// *************************************************************************** *
// *                                                                           *
// *                      Mentor Graphics Corporation                          *
// *                          All rights reserved                              *
// *                                                                           *
// *************************************************************************** *
// *                                                                           *
// * Description:         CANDB File                                           *
// * Generated at:        2020-04-14 13:10:10                                  *
// * System:              SDB20010                                             *
// * Variant:             HX11                                                 *
// * Network:             BodyExposedCAN                                       *
// *                                                                           *
// *************************************************************************** *
// *                                                                           *
// *             THIS CONFIGURATION MIGHT CONTAIN SOME ERRORS                  *
// *              IF THE INPUT MODEL WAS NOT PROPERLY FORMED!                  *
// *                    Do Not Use this File directly!                         *
// *                                                                           *
// *************************************************************************** *
VERSION "BodyExposedCAN"

NS_ :

BS_:

BU_:  CEM ETC HCML HCMR

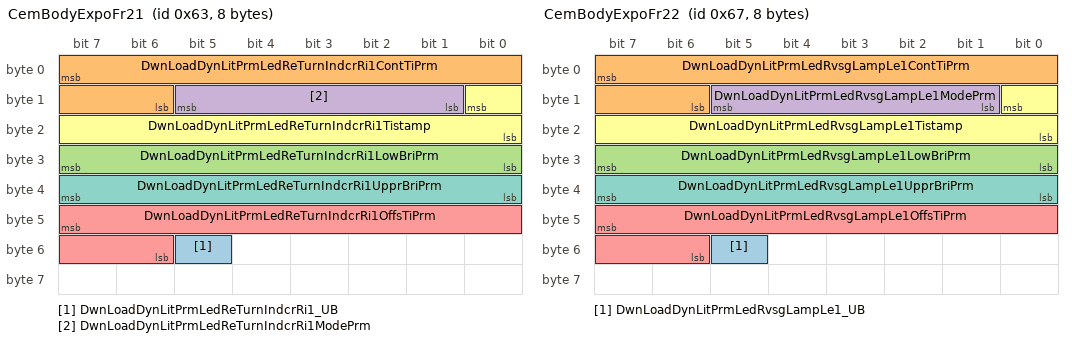
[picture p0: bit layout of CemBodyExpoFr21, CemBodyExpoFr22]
BO_ 99 CemBodyExpoFr21: 8 CEM
 SG_ DwnLoadDynLitPrmLedReTurnIndcrRi1_UB : 53|1@0+ (1,0) [0|1] "" Vector_XXX
 SG_ DwnLoadDynLitPrmLedReTurnIndcrRi1ContTiPrm : 7|10@0+ (1.0,0.0) [0.0|1000.0] "Milliseconds" Vector_XXX
 SG_ DwnLoadDynLitPrmLedReTurnIndcrRi1LowBriPrm : 31|8@0+ (1.0,0.0) [0.0|100.0] "%" Vector_XXX
 SG_ DwnLoadDynLitPrmLedReTurnIndcrRi1ModePrm : 13|5@0+ (1,0) [0|31] "" Vector_XXX
 SG_ DwnLoadDynLitPrmLedReTurnIndcrRi1OffsTiPrm : 47|10@0+ (1.0,0.0) [0.0|1000.0] "Milliseconds" Vector_XXX
 SG_ DwnLoadDynLitPrmLedReTurnIndcrRi1Tistamp : 8|9@0+ (1.0,0.0) [0.0|511.0] "Unitless" Vector_XXX
 SG_ DwnLoadDynLitPrmLedReTurnIndcrRi1UpprBriPrm : 39|8@0+ (1.0,0.0) [0.0|100.0] "%" Vector_XXX

BO_ 103 CemBodyExpoFr22: 8 CEM
 SG_ DwnLoadDynLitPrmLedRvsgLampLe1_UB : 53|1@0+ (1,0) [0|1] "" Vector_XXX
 SG_ DwnLoadDynLitPrmLedRvsgLampLe1ContTiPrm : 7|10@0+ (1.0,0.0) [0.0|1000.0] "Milliseconds" Vector_XXX
 SG_ DwnLoadDynLitPrmLedRvsgLampLe1LowBriPrm : 31|8@0+ (1.0,0.0) [0.0|100.0] "%" Vector_XXX
 SG_ DwnLoadDynLitPrmLedRvsgLampLe1ModePrm : 13|5@0+ (1,0) [0|31] "" Vector_XXX
 SG_ DwnLoadDynLitPrmLedRvsgLampLe1OffsTiPrm : 47|10@0+ (1.0,0.0) [0.0|1000.0] "Milliseconds" Vector_XXX
 SG_ DwnLoadDynLitPrmLedRvsgLampLe1Tistamp : 8|9@0+ (1.0,0.0) [0.0|511.0] "Unitless" Vector_XXX
 SG_ DwnLoadDynLitPrmLedRvsgLampLe1UpprBriPrm : 39|8@0+ (1.0,0.0) [0.0|100.0] "%" Vector_XXX

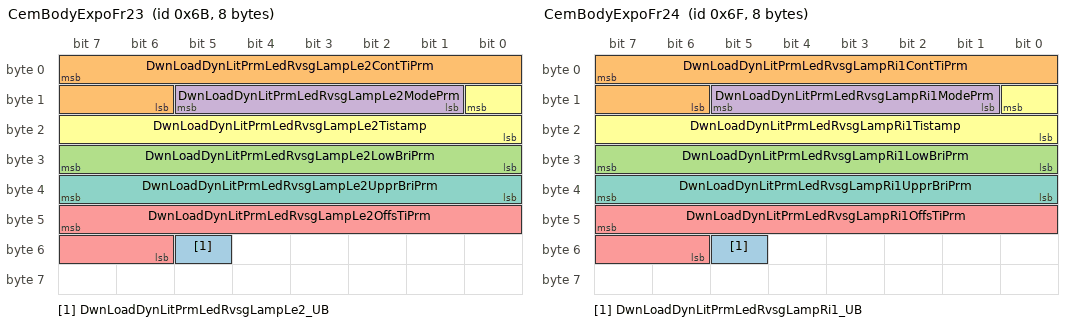
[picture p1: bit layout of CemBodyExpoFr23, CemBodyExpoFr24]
BO_ 107 CemBodyExpoFr23: 8 CEM
 SG_ DwnLoadDynLitPrmLedRvsgLampLe2_UB : 53|1@0+ (1,0) [0|1] "" Vector_XXX
 SG_ DwnLoadDynLitPrmLedRvsgLampLe2ContTiPrm : 7|10@0+ (1.0,0.0) [0.0|1000.0] "Milliseconds" Vector_XXX
 SG_ DwnLoadDynLitPrmLedRvsgLampLe2LowBriPrm : 31|8@0+ (1.0,0.0) [0.0|100.0] "%" Vector_XXX
 SG_ DwnLoadDynLitPrmLedRvsgLampLe2ModePrm : 13|5@0+ (1,0) [0|31] "" Vector_XXX
 SG_ DwnLoadDynLitPrmLedRvsgLampLe2OffsTiPrm : 47|10@0+ (1.0,0.0) [0.0|1000.0] "Milliseconds" Vector_XXX
 SG_ DwnLoadDynLitPrmLedRvsgLampLe2Tistamp : 8|9@0+ (1.0,0.0) [0.0|511.0] "Unitless" Vector_XXX
 SG_ DwnLoadDynLitPrmLedRvsgLampLe2UpprBriPrm : 39|8@0+ (1.0,0.0) [0.0|100.0] "%" Vector_XXX

BO_ 111 CemBodyExpoFr24: 8 CEM
 SG_ DwnLoadDynLitPrmLedRvsgLampRi1_UB : 53|1@0+ (1,0) [0|1] "" Vector_XXX
 SG_ DwnLoadDynLitPrmLedRvsgLampRi1ContTiPrm : 7|10@0+ (1.0,0.0) [0.0|1000.0] "Milliseconds" Vector_XXX
 SG_ DwnLoadDynLitPrmLedRvsgLampRi1LowBriPrm : 31|8@0+ (1.0,0.0) [0.0|100.0] "%" Vector_XXX
 SG_ DwnLoadDynLitPrmLedRvsgLampRi1ModePrm : 13|5@0+ (1,0) [0|31] "" Vector_XXX
 SG_ DwnLoadDynLitPrmLedRvsgLampRi1OffsTiPrm : 47|10@0+ (1.0,0.0) [0.0|1000.0] "Milliseconds" Vector_XXX
 SG_ DwnLoadDynLitPrmLedRvsgLampRi1Tistamp : 8|9@0+ (1.0,0.0) [0.0|511.0] "Unitless" Vector_XXX
 SG_ DwnLoadDynLitPrmLedRvsgLampRi1UpprBriPrm : 39|8@0+ (1.0,0.0) [0.0|100.0] "%" Vector_XXX

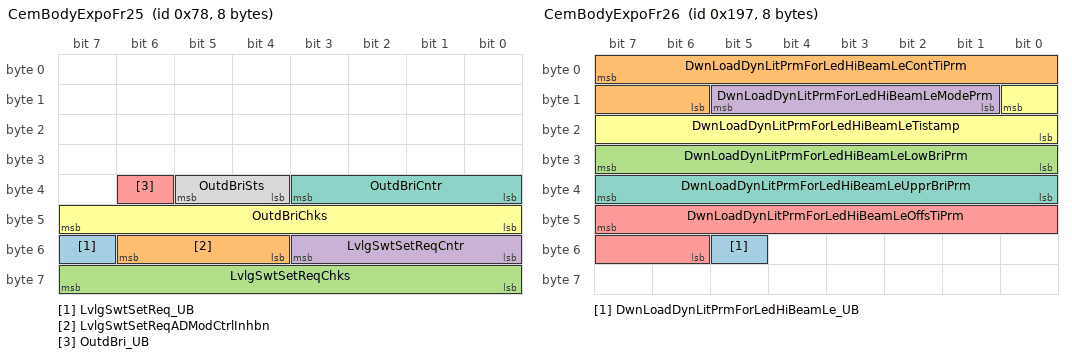
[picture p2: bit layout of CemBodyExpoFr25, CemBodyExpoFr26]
BO_ 120 CemBodyExpoFr25: 8 CEM
 SG_ LvlgSwtSetReq_UB : 55|1@0+ (1,0) [0|1] "" HCML,HCMR
 SG_ LvlgSwtSetReqADModCtrlInhbn : 54|3@0+ (1,0) [0|7] "" HCML,HCMR
 SG_ LvlgSwtSetReqChks : 63|8@0+ (1.0,0.0) [0.0|255.0] "Unitless" HCML,HCMR
 SG_ LvlgSwtSetReqCntr : 51|4@0+ (1.0,0.0) [0.0|15.0] "Unitless" HCML,HCMR
 SG_ OutdBri_UB : 38|1@0+ (1,0) [0|1] "" HCML,HCMR
 SG_ OutdBriChks : 47|8@0+ (1.0,0.0) [0.0|255.0] "Unitless" HCML,HCMR
 SG_ OutdBriCntr : 35|4@0+ (1.0,0.0) [0.0|15.0] "Unitless" HCML,HCMR
 SG_ OutdBriSts : 37|2@0+ (1,0) [0|3] "" HCML,HCMR

BO_ 407 CemBodyExpoFr26: 8 CEM
 SG_ DwnLoadDynLitPrmForLedHiBeamLe_UB : 53|1@0+ (1,0) [0|1] "" HCML
 SG_ DwnLoadDynLitPrmForLedHiBeamLeContTiPrm : 7|10@0+ (1.0,0.0) [0.0|1000.0] "Milliseconds" HCML
 SG_ DwnLoadDynLitPrmForLedHiBeamLeLowBriPrm : 31|8@0+ (1.0,0.0) [0.0|100.0] "%" HCML
 SG_ DwnLoadDynLitPrmForLedHiBeamLeModePrm : 13|5@0+ (1,0) [0|31] "" HCML
 SG_ DwnLoadDynLitPrmForLedHiBeamLeOffsTiPrm : 47|10@0+ (1.0,0.0) [0.0|1000.0] "Milliseconds" HCML
 SG_ DwnLoadDynLitPrmForLedHiBeamLeTistamp : 8|9@0+ (1.0,0.0) [0.0|511.0] "Unitless" HCML
 SG_ DwnLoadDynLitPrmForLedHiBeamLeUpprBriPrm : 39|8@0+ (1.0,0.0) [0.0|100.0] "%" HCML

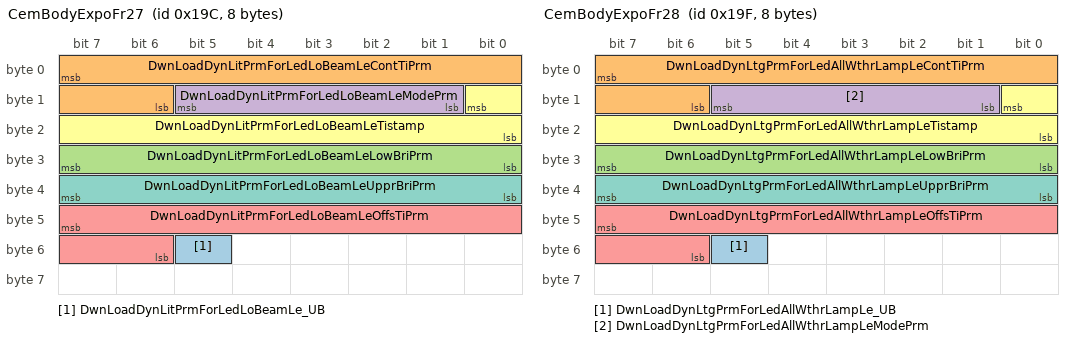
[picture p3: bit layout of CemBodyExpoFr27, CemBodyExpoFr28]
BO_ 412 CemBodyExpoFr27: 8 CEM
 SG_ DwnLoadDynLitPrmForLedLoBeamLe_UB : 53|1@0+ (1,0) [0|1] "" HCML
 SG_ DwnLoadDynLitPrmForLedLoBeamLeContTiPrm : 7|10@0+ (1.0,0.0) [0.0|1000.0] "Milliseconds" HCML
 SG_ DwnLoadDynLitPrmForLedLoBeamLeLowBriPrm : 31|8@0+ (1.0,0.0) [0.0|100.0] "%" HCML
 SG_ DwnLoadDynLitPrmForLedLoBeamLeModePrm : 13|5@0+ (1,0) [0|31] "" HCML
 SG_ DwnLoadDynLitPrmForLedLoBeamLeOffsTiPrm : 47|10@0+ (1.0,0.0) [0.0|1000.0] "Milliseconds" HCML
 SG_ DwnLoadDynLitPrmForLedLoBeamLeTistamp : 8|9@0+ (1.0,0.0) [0.0|511.0] "Unitless" HCML
 SG_ DwnLoadDynLitPrmForLedLoBeamLeUpprBriPrm : 39|8@0+ (1.0,0.0) [0.0|100.0] "%" HCML

BO_ 415 CemBodyExpoFr28: 8 CEM
 SG_ DwnLoadDynLtgPrmForLedAllWthrLampLe_UB : 53|1@0+ (1,0) [0|1] "" HCML
 SG_ DwnLoadDynLtgPrmForLedAllWthrLampLeContTiPrm : 7|10@0+ (1.0,0.0) [0.0|1000.0] "Milliseconds" HCML
 SG_ DwnLoadDynLtgPrmForLedAllWthrLampLeLowBriPrm : 31|8@0+ (1.0,0.0) [0.0|100.0] "%" HCML
 SG_ DwnLoadDynLtgPrmForLedAllWthrLampLeModePrm : 13|5@0+ (1,0) [0|31] "" HCML
 SG_ DwnLoadDynLtgPrmForLedAllWthrLampLeOffsTiPrm : 47|10@0+ (1.0,0.0) [0.0|1000.0] "Milliseconds" HCML
 SG_ DwnLoadDynLtgPrmForLedAllWthrLampLeTistamp : 8|9@0+ (1.0,0.0) [0.0|511.0] "Unitless" HCML
 SG_ DwnLoadDynLtgPrmForLedAllWthrLampLeUpprBriPrm : 39|8@0+ (1.0,0.0) [0.0|100.0] "%" HCML

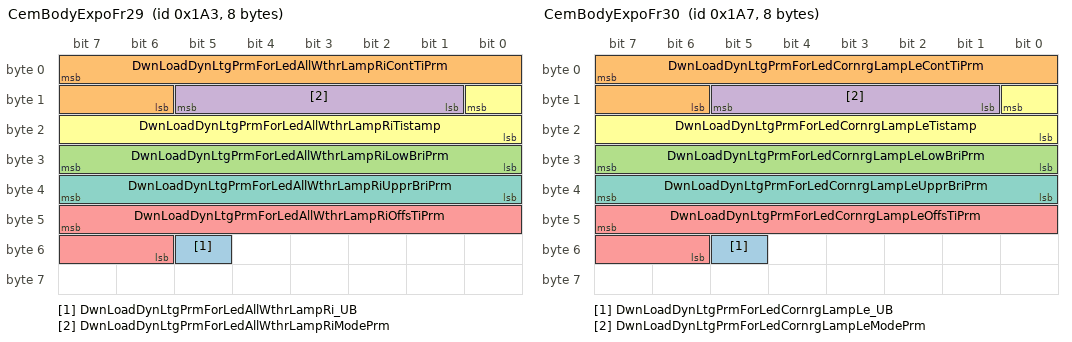
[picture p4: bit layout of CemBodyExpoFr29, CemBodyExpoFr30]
BO_ 419 CemBodyExpoFr29: 8 CEM
 SG_ DwnLoadDynLtgPrmForLedAllWthrLampRi_UB : 53|1@0+ (1,0) [0|1] "" HCMR
 SG_ DwnLoadDynLtgPrmForLedAllWthrLampRiContTiPrm : 7|10@0+ (1.0,0.0) [0.0|1000.0] "Milliseconds" HCMR
 SG_ DwnLoadDynLtgPrmForLedAllWthrLampRiLowBriPrm : 31|8@0+ (1.0,0.0) [0.0|100.0] "%" HCMR
 SG_ DwnLoadDynLtgPrmForLedAllWthrLampRiModePrm : 13|5@0+ (1,0) [0|31] "" HCMR
 SG_ DwnLoadDynLtgPrmForLedAllWthrLampRiOffsTiPrm : 47|10@0+ (1.0,0.0) [0.0|1000.0] "Milliseconds" HCMR
 SG_ DwnLoadDynLtgPrmForLedAllWthrLampRiTistamp : 8|9@0+ (1.0,0.0) [0.0|511.0] "Unitless" HCMR
 SG_ DwnLoadDynLtgPrmForLedAllWthrLampRiUpprBriPrm : 39|8@0+ (1.0,0.0) [0.0|100.0] "%" HCMR

BO_ 423 CemBodyExpoFr30: 8 CEM
 SG_ DwnLoadDynLtgPrmForLedCornrgLampLe_UB : 53|1@0+ (1,0) [0|1] "" HCML
 SG_ DwnLoadDynLtgPrmForLedCornrgLampLeContTiPrm : 7|10@0+ (1.0,0.0) [0.0|1000.0] "Milliseconds" HCML
 SG_ DwnLoadDynLtgPrmForLedCornrgLampLeLowBriPrm : 31|8@0+ (1.0,0.0) [0.0|100.0] "%" HCML
 SG_ DwnLoadDynLtgPrmForLedCornrgLampLeModePrm : 13|5@0+ (1,0) [0|31] "" HCML
 SG_ DwnLoadDynLtgPrmForLedCornrgLampLeOffsTiPrm : 47|10@0+ (1.0,0.0) [0.0|1000.0] "Milliseconds" HCML
 SG_ DwnLoadDynLtgPrmForLedCornrgLampLeTistamp : 8|9@0+ (1.0,0.0) [0.0|511.0] "Unitless" HCML
 SG_ DwnLoadDynLtgPrmForLedCornrgLampLeUpprBriPrm : 39|8@0+ (1.0,0.0) [0.0|100.0] "%" HCML

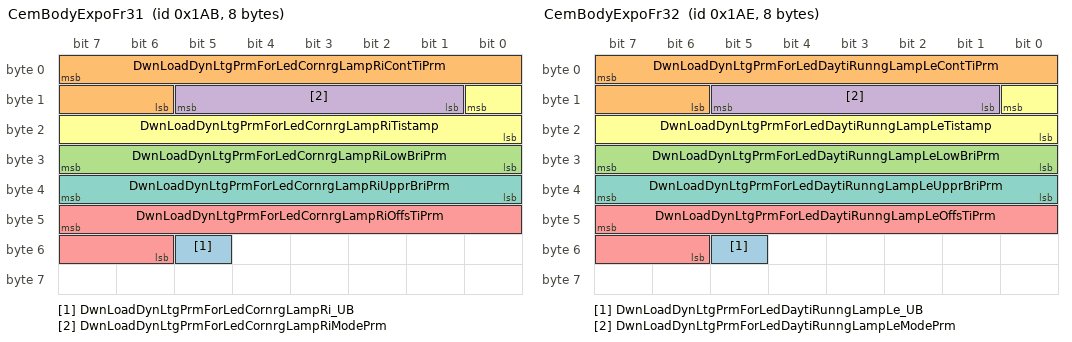
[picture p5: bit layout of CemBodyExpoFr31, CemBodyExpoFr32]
BO_ 427 CemBodyExpoFr31: 8 CEM
 SG_ DwnLoadDynLtgPrmForLedCornrgLampRi_UB : 53|1@0+ (1,0) [0|1] "" HCMR
 SG_ DwnLoadDynLtgPrmForLedCornrgLampRiContTiPrm : 7|10@0+ (1.0,0.0) [0.0|1000.0] "Milliseconds" HCMR
 SG_ DwnLoadDynLtgPrmForLedCornrgLampRiLowBriPrm : 31|8@0+ (1.0,0.0) [0.0|100.0] "%" HCMR
 SG_ DwnLoadDynLtgPrmForLedCornrgLampRiModePrm : 13|5@0+ (1,0) [0|31] "" HCMR
 SG_ DwnLoadDynLtgPrmForLedCornrgLampRiOffsTiPrm : 47|10@0+ (1.0,0.0) [0.0|1000.0] "Milliseconds" HCMR
 SG_ DwnLoadDynLtgPrmForLedCornrgLampRiTistamp : 8|9@0+ (1.0,0.0) [0.0|511.0] "Unitless" HCMR
 SG_ DwnLoadDynLtgPrmForLedCornrgLampRiUpprBriPrm : 39|8@0+ (1.0,0.0) [0.0|100.0] "%" HCMR

BO_ 430 CemBodyExpoFr32: 8 CEM
 SG_ DwnLoadDynLtgPrmForLedDaytiRunngLampLe_UB : 53|1@0+ (1,0) [0|1] "" HCML
 SG_ DwnLoadDynLtgPrmForLedDaytiRunngLampLeContTiPrm : 7|10@0+ (1.0,0.0) [0.0|1000.0] "Milliseconds" HCML
 SG_ DwnLoadDynLtgPrmForLedDaytiRunngLampLeLowBriPrm : 31|8@0+ (1.0,0.0) [0.0|100.0] "%" HCML
 SG_ DwnLoadDynLtgPrmForLedDaytiRunngLampLeModePrm : 13|5@0+ (1,0) [0|31] "" HCML
 SG_ DwnLoadDynLtgPrmForLedDaytiRunngLampLeOffsTiPrm : 47|10@0+ (1.0,0.0) [0.0|1000.0] "Milliseconds" HCML
 SG_ DwnLoadDynLtgPrmForLedDaytiRunngLampLeTistamp : 8|9@0+ (1.0,0.0) [0.0|511.0] "Unitless" HCML
 SG_ DwnLoadDynLtgPrmForLedDaytiRunngLampLeUpprBriPrm : 39|8@0+ (1.0,0.0) [0.0|100.0] "%" HCML

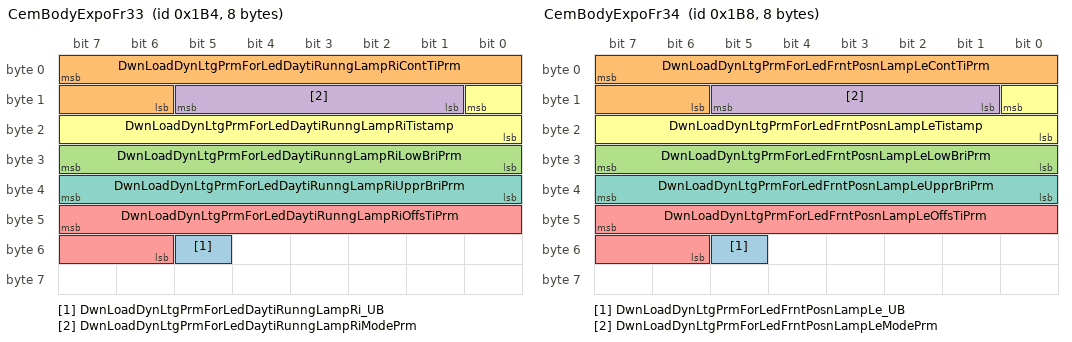
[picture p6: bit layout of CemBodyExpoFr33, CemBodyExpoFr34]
BO_ 436 CemBodyExpoFr33: 8 CEM
 SG_ DwnLoadDynLtgPrmForLedDaytiRunngLampRi_UB : 53|1@0+ (1,0) [0|1] "" HCMR
 SG_ DwnLoadDynLtgPrmForLedDaytiRunngLampRiContTiPrm : 7|10@0+ (1.0,0.0) [0.0|1000.0] "Milliseconds" HCMR
 SG_ DwnLoadDynLtgPrmForLedDaytiRunngLampRiLowBriPrm : 31|8@0+ (1.0,0.0) [0.0|100.0] "%" HCMR
 SG_ DwnLoadDynLtgPrmForLedDaytiRunngLampRiModePrm : 13|5@0+ (1,0) [0|31] "" HCMR
 SG_ DwnLoadDynLtgPrmForLedDaytiRunngLampRiOffsTiPrm : 47|10@0+ (1.0,0.0) [0.0|1000.0] "Milliseconds" HCMR
 SG_ DwnLoadDynLtgPrmForLedDaytiRunngLampRiTistamp : 8|9@0+ (1.0,0.0) [0.0|511.0] "Unitless" HCMR
 SG_ DwnLoadDynLtgPrmForLedDaytiRunngLampRiUpprBriPrm : 39|8@0+ (1.0,0.0) [0.0|100.0] "%" HCMR

BO_ 440 CemBodyExpoFr34: 8 CEM
 SG_ DwnLoadDynLtgPrmForLedFrntPosnLampLe_UB : 53|1@0+ (1,0) [0|1] "" HCML
 SG_ DwnLoadDynLtgPrmForLedFrntPosnLampLeContTiPrm : 7|10@0+ (1.0,0.0) [0.0|1000.0] "Milliseconds" HCML
 SG_ DwnLoadDynLtgPrmForLedFrntPosnLampLeLowBriPrm : 31|8@0+ (1.0,0.0) [0.0|100.0] "%" HCML
 SG_ DwnLoadDynLtgPrmForLedFrntPosnLampLeModePrm : 13|5@0+ (1,0) [0|31] "" HCML
 SG_ DwnLoadDynLtgPrmForLedFrntPosnLampLeOffsTiPrm : 47|10@0+ (1.0,0.0) [0.0|1000.0] "Milliseconds" HCML
 SG_ DwnLoadDynLtgPrmForLedFrntPosnLampLeTistamp : 8|9@0+ (1.0,0.0) [0.0|511.0] "Unitless" HCML
 SG_ DwnLoadDynLtgPrmForLedFrntPosnLampLeUpprBriPrm : 39|8@0+ (1.0,0.0) [0.0|100.0] "%" HCML

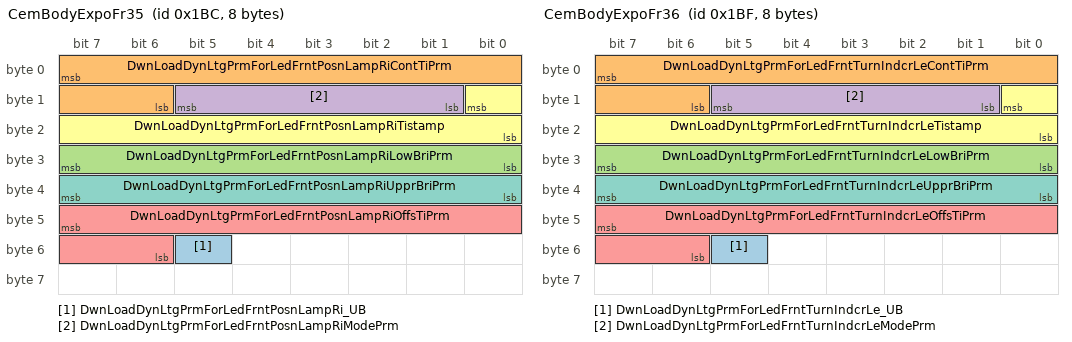
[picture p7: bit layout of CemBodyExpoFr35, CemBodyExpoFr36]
BO_ 444 CemBodyExpoFr35: 8 CEM
 SG_ DwnLoadDynLtgPrmForLedFrntPosnLampRi_UB : 53|1@0+ (1,0) [0|1] "" HCMR
 SG_ DwnLoadDynLtgPrmForLedFrntPosnLampRiContTiPrm : 7|10@0+ (1.0,0.0) [0.0|1000.0] "Milliseconds" HCMR
 SG_ DwnLoadDynLtgPrmForLedFrntPosnLampRiLowBriPrm : 31|8@0+ (1.0,0.0) [0.0|100.0] "%" HCMR
 SG_ DwnLoadDynLtgPrmForLedFrntPosnLampRiModePrm : 13|5@0+ (1,0) [0|31] "" HCMR
 SG_ DwnLoadDynLtgPrmForLedFrntPosnLampRiOffsTiPrm : 47|10@0+ (1.0,0.0) [0.0|1000.0] "Milliseconds" HCMR
 SG_ DwnLoadDynLtgPrmForLedFrntPosnLampRiTistamp : 8|9@0+ (1.0,0.0) [0.0|511.0] "Unitless" HCMR
 SG_ DwnLoadDynLtgPrmForLedFrntPosnLampRiUpprBriPrm : 39|8@0+ (1.0,0.0) [0.0|100.0] "%" HCMR

BO_ 447 CemBodyExpoFr36: 8 CEM
 SG_ DwnLoadDynLtgPrmForLedFrntTurnIndcrLe_UB : 53|1@0+ (1,0) [0|1] "" HCML
 SG_ DwnLoadDynLtgPrmForLedFrntTurnIndcrLeContTiPrm : 7|10@0+ (1.0,0.0) [0.0|1000.0] "Milliseconds" HCML
 SG_ DwnLoadDynLtgPrmForLedFrntTurnIndcrLeLowBriPrm : 31|8@0+ (1.0,0.0) [0.0|100.0] "%" HCML
 SG_ DwnLoadDynLtgPrmForLedFrntTurnIndcrLeModePrm : 13|5@0+ (1,0) [0|31] "" HCML
 SG_ DwnLoadDynLtgPrmForLedFrntTurnIndcrLeOffsTiPrm : 47|10@0+ (1.0,0.0) [0.0|1000.0] "Milliseconds" HCML
 SG_ DwnLoadDynLtgPrmForLedFrntTurnIndcrLeTistamp : 8|9@0+ (1.0,0.0) [0.0|511.0] "Unitless" HCML
 SG_ DwnLoadDynLtgPrmForLedFrntTurnIndcrLeUpprBriPrm : 39|8@0+ (1.0,0.0) [0.0|100.0] "%" HCML

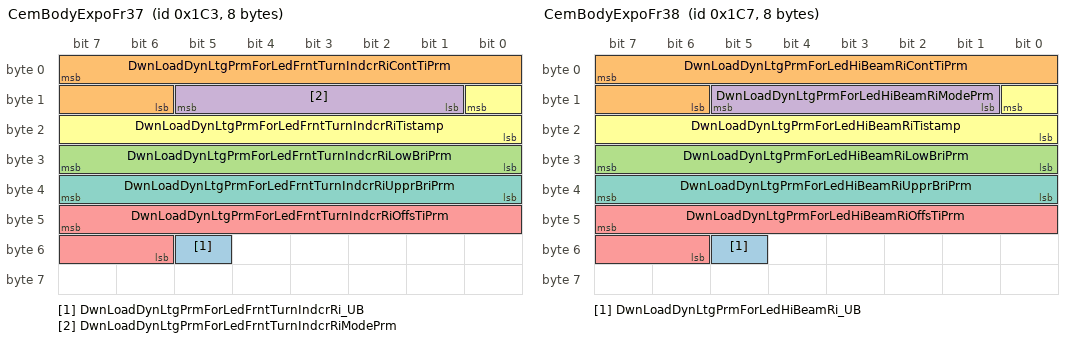
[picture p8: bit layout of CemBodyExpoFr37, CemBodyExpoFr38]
BO_ 451 CemBodyExpoFr37: 8 CEM
 SG_ DwnLoadDynLtgPrmForLedFrntTurnIndcrRi_UB : 53|1@0+ (1,0) [0|1] "" HCMR
 SG_ DwnLoadDynLtgPrmForLedFrntTurnIndcrRiContTiPrm : 7|10@0+ (1.0,0.0) [0.0|1000.0] "Milliseconds" HCMR
 SG_ DwnLoadDynLtgPrmForLedFrntTurnIndcrRiLowBriPrm : 31|8@0+ (1.0,0.0) [0.0|100.0] "%" HCMR
 SG_ DwnLoadDynLtgPrmForLedFrntTurnIndcrRiModePrm : 13|5@0+ (1,0) [0|31] "" HCMR
 SG_ DwnLoadDynLtgPrmForLedFrntTurnIndcrRiOffsTiPrm : 47|10@0+ (1.0,0.0) [0.0|1000.0] "Milliseconds" HCMR
 SG_ DwnLoadDynLtgPrmForLedFrntTurnIndcrRiTistamp : 8|9@0+ (1.0,0.0) [0.0|511.0] "Unitless" HCMR
 SG_ DwnLoadDynLtgPrmForLedFrntTurnIndcrRiUpprBriPrm : 39|8@0+ (1.0,0.0) [0.0|100.0] "%" HCMR

BO_ 455 CemBodyExpoFr38: 8 CEM
 SG_ DwnLoadDynLtgPrmForLedHiBeamRi_UB : 53|1@0+ (1,0) [0|1] "" HCMR
 SG_ DwnLoadDynLtgPrmForLedHiBeamRiContTiPrm : 7|10@0+ (1.0,0.0) [0.0|1000.0] "Milliseconds" HCMR
 SG_ DwnLoadDynLtgPrmForLedHiBeamRiLowBriPrm : 31|8@0+ (1.0,0.0) [0.0|100.0] "%" HCMR
 SG_ DwnLoadDynLtgPrmForLedHiBeamRiModePrm : 13|5@0+ (1,0) [0|31] "" HCMR
 SG_ DwnLoadDynLtgPrmForLedHiBeamRiOffsTiPrm : 47|10@0+ (1.0,0.0) [0.0|1000.0] "Milliseconds" HCMR
 SG_ DwnLoadDynLtgPrmForLedHiBeamRiTistamp : 8|9@0+ (1.0,0.0) [0.0|511.0] "Unitless" HCMR
 SG_ DwnLoadDynLtgPrmForLedHiBeamRiUpprBriPrm : 39|8@0+ (1.0,0.0) [0.0|100.0] "%" HCMR

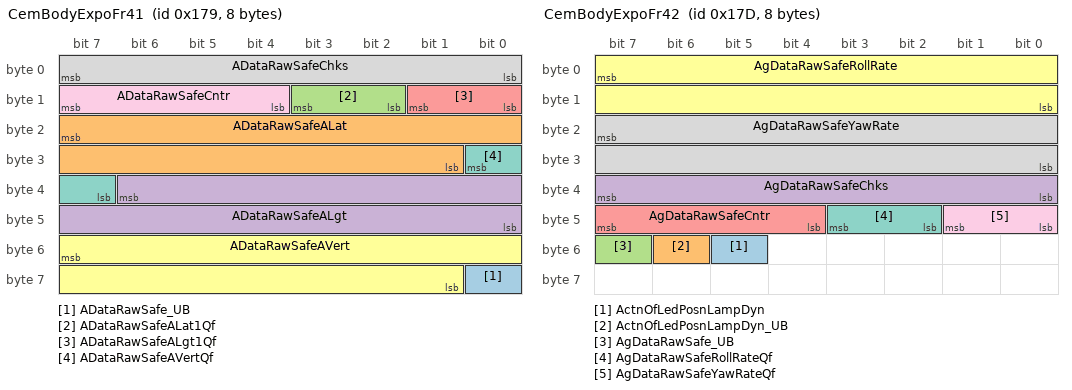
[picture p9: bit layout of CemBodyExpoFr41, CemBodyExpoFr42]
BO_ 377 CemBodyExpoFr41: 8 CEM
 SG_ ADataRawSafe_UB : 56|1@0+ (1,0) [0|1] "" HCML,HCMR
 SG_ ADataRawSafeALat : 23|15@0- (0.0085,0.0) [-138.99200000000002|139.00050000000002] "m/s^2" HCML,HCMR
 SG_ ADataRawSafeALat1Qf : 11|2@0+ (1,0) [0|3] "" HCML,HCMR
 SG_ ADataRawSafeALgt : 38|15@0- (0.0085,0.0) [-138.99200000000002|139.00050000000002] "m/s^2" HCML,HCMR
 SG_ ADataRawSafeALgt1Qf : 9|2@0+ (1,0) [0|3] "" HCML,HCMR
 SG_ ADataRawSafeAVert : 55|15@0- (0.0085,0.0) [-138.99200000000002|139.00050000000002] "m/s^2" HCML,HCMR
 SG_ ADataRawSafeAVertQf : 24|2@0+ (1,0) [0|3] "" HCML,HCMR
 SG_ ADataRawSafeChks : 7|8@0+ (1.0,0.0) [0.0|255.0] "Unitless" HCML,HCMR
 SG_ ADataRawSafeCntr : 15|4@0+ (1.0,0.0) [0.0|15.0] "Unitless" HCML,HCMR

BO_ 381 CemBodyExpoFr42: 8 CEM
 SG_ ActnOfLedPosnLampDyn : 53|1@0+ (1,0) [0|1] "" HCML,HCMR
 SG_ ActnOfLedPosnLampDyn_UB : 54|1@0+ (1,0) [0|1] "" HCML,HCMR
 SG_ AgDataRawSafe_UB : 55|1@0+ (1,0) [0|1] "" HCML,HCMR
 SG_ AgDataRawSafeChks : 39|8@0+ (1.0,0.0) [0.0|255.0] "Unitless" HCML,HCMR
 SG_ AgDataRawSafeCntr : 47|4@0+ (1.0,0.0) [0.0|15.0] "Unitless" HCML,HCMR
 SG_ AgDataRawSafeRollRate : 7|16@0- (0.000244140625,0.0) [-6.0|6.0] "rad/s" HCML,HCMR
 SG_ AgDataRawSafeRollRateQf : 43|2@0+ (1,0) [0|3] "" HCML,HCMR
 SG_ AgDataRawSafeYawRate : 23|16@0- (0.000244140625,0.0) [-6.0|6.0] "rad/s" HCML,HCMR
 SG_ AgDataRawSafeYawRateQf : 41|2@0+ (1,0) [0|3] "" HCML,HCMR

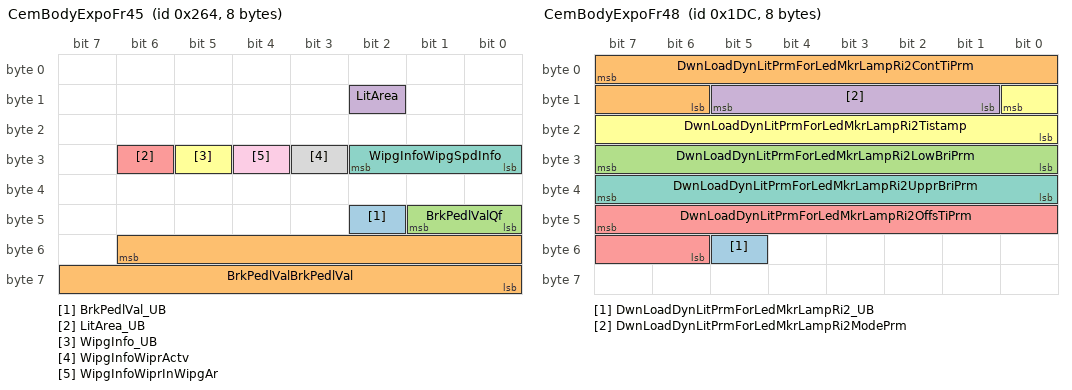
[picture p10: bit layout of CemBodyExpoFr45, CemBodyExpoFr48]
BO_ 612 CemBodyExpoFr45: 8 CEM
 SG_ BrkPedlVal_UB : 42|1@0+ (1,0) [0|1] "" HCML,HCMR
 SG_ BrkPedlValBrkPedlVal : 54|15@0+ (0.00390625,0.0) [0.0|100.0] "%" HCML,HCMR
 SG_ BrkPedlValQf : 41|2@0+ (1,0) [0|3] "" HCML,HCMR
 SG_ LitArea : 10|1@0+ (1,0) [0|1] "" HCML,HCMR
 SG_ LitArea_UB : 30|1@0+ (1,0) [0|1] "" HCML,HCMR
 SG_ WipgInfo_UB : 29|1@0+ (1,0) [0|1] "" HCML,HCMR
 SG_ WipgInfoWipgSpdInfo : 26|3@0+ (1,0) [0|7] "" HCML,HCMR
 SG_ WipgInfoWiprActv : 27|1@0+ (1,0) [0|1] "" HCML,HCMR
 SG_ WipgInfoWiprInWipgAr : 28|1@0+ (1,0) [0|1] "" HCML,HCMR

BO_ 476 CemBodyExpoFr48: 8 CEM
 SG_ DwnLoadDynLitPrmForLedMkrLampRi2_UB : 53|1@0+ (1,0) [0|1] "" Vector_XXX
 SG_ DwnLoadDynLitPrmForLedMkrLampRi2ContTiPrm : 7|10@0+ (1.0,0.0) [0.0|1000.0] "Milliseconds" Vector_XXX
 SG_ DwnLoadDynLitPrmForLedMkrLampRi2LowBriPrm : 31|8@0+ (1.0,0.0) [0.0|100.0] "%" Vector_XXX
 SG_ DwnLoadDynLitPrmForLedMkrLampRi2ModePrm : 13|5@0+ (1,0) [0|31] "" Vector_XXX
 SG_ DwnLoadDynLitPrmForLedMkrLampRi2OffsTiPrm : 47|10@0+ (1.0,0.0) [0.0|1000.0] "Milliseconds" Vector_XXX
 SG_ DwnLoadDynLitPrmForLedMkrLampRi2Tistamp : 8|9@0+ (1.0,0.0) [0.0|511.0] "Unitless" Vector_XXX
 SG_ DwnLoadDynLitPrmForLedMkrLampRi2UpprBriPrm : 39|8@0+ (1.0,0.0) [0.0|100.0] "%" Vector_XXX

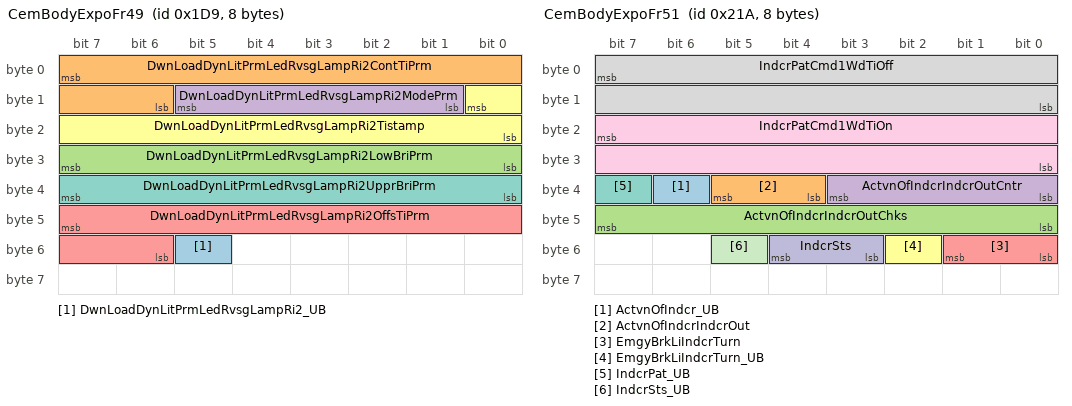
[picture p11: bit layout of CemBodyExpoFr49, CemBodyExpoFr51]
BO_ 473 CemBodyExpoFr49: 8 CEM
 SG_ DwnLoadDynLitPrmLedRvsgLampRi2_UB : 53|1@0+ (1,0) [0|1] "" Vector_XXX
 SG_ DwnLoadDynLitPrmLedRvsgLampRi2ContTiPrm : 7|10@0+ (1.0,0.0) [0.0|1000.0] "Milliseconds" Vector_XXX
 SG_ DwnLoadDynLitPrmLedRvsgLampRi2LowBriPrm : 31|8@0+ (1.0,0.0) [0.0|100.0] "%" Vector_XXX
 SG_ DwnLoadDynLitPrmLedRvsgLampRi2ModePrm : 13|5@0+ (1,0) [0|31] "" Vector_XXX
 SG_ DwnLoadDynLitPrmLedRvsgLampRi2OffsTiPrm : 47|10@0+ (1.0,0.0) [0.0|1000.0] "Milliseconds" Vector_XXX
 SG_ DwnLoadDynLitPrmLedRvsgLampRi2Tistamp : 8|9@0+ (1.0,0.0) [0.0|511.0] "Unitless" Vector_XXX
 SG_ DwnLoadDynLitPrmLedRvsgLampRi2UpprBriPrm : 39|8@0+ (1.0,0.0) [0.0|100.0] "%" Vector_XXX

BO_ 522 CemBodyExpoFr50: 8 CEM
 SG_ ActnOfLedCornrgLampLe : 6|1@0+ (1,0) [0|1] "" HCML
 SG_ ActnOfLedCornrgLampLe_UB : 7|1@0+ (1,0) [0|1] "" HCML
 SG_ ActnOfLedCornrgLampRi : 22|1@0+ (1,0) [0|1] "" HCMR
 SG_ ActnOfLedCornrgLampRi_UB : 23|1@0+ (1,0) [0|1] "" HCMR
 SG_ ActnOfLedDaytiRunngLamp : 32|1@0+ (1,0) [0|1] "" HCML,HCMR
 SG_ ActnOfLedDaytiRunngLamp_UB : 33|1@0+ (1,0) [0|1] "" HCML,HCMR
 SG_ ActnOfLedFrntFogLamp : 34|1@0+ (1,0) [0|1] "" HCML,HCMR
 SG_ ActnOfLedFrntFogLamp_UB : 35|1@0+ (1,0) [0|1] "" HCML,HCMR
 SG_ ActnOfLedHiBeam : 36|1@0+ (1,0) [0|1] "" HCML,HCMR
 SG_ ActnOfLedHiBeam_UB : 37|1@0+ (1,0) [0|1] "" HCML,HCMR
 SG_ ActnOfLedLoBeam_UB : 5|1@0+ (1,0) [0|1] "" HCML,HCMR
 SG_ ActnOfLedLoBeamActnOfLedLoBeam : 4|1@0+ (1,0) [0|1] "" HCML,HCMR
 SG_ ActnOfLedLoBeamChks : 15|8@0+ (1.0,0.0) [0.0|255.0] "Unitless" HCML,HCMR
 SG_ ActnOfLedLoBeamCntr : 3|4@0+ (1.0,0.0) [0.0|15.0] "Unitless" HCML,HCMR
 SG_ ActnOfLedPosnLamp : 38|1@0+ (1,0) [0|1] "" HCML,HCMR
 SG_ ActnOfLedPosnLamp_UB : 39|1@0+ (1,0) [0|1] "" HCML,HCMR
 SG_ ActnOfLedReFogLamp : 40|1@0+ (1,0) [0|1] "" Vector_XXX
 SG_ ActnOfLedReFogLamp_UB : 41|1@0+ (1,0) [0|1] "" Vector_XXX
 SG_ ActnOfLedRvsgLamp : 42|1@0+ (1,0) [0|1] "" Vector_XXX
 SG_ ActnOfLedRvsgLamp_UB : 43|1@0+ (1,0) [0|1] "" Vector_XXX
 SG_ ActnOfLedStopLamp_UB : 21|1@0+ (1,0) [0|1] "" Vector_XXX
 SG_ ActnOfLedStopLampActnOfLedStopLamp : 20|1@0+ (1,0) [0|1] "" Vector_XXX
 SG_ ActnOfLedStopLampChks : 31|8@0+ (1.0,0.0) [0.0|255.0] "Unitless" Vector_XXX
 SG_ ActnOfLedStopLampCntr : 19|4@0+ (1.0,0.0) [0.0|15.0] "Unitless" Vector_XXX
 SG_ ActvnOfAfs : 44|1@0+ (1,0) [0|1] "" HCML,HCMR
 SG_ ActvnOfAfs_UB : 45|1@0+ (1,0) [0|1] "" HCML,HCMR
 SG_ ActvnOfAhbc : 46|1@0+ (1,0) [0|1] "" HCML,HCMR
 SG_ ActvnOfAhbc_UB : 47|1@0+ (1,0) [0|1] "" HCML,HCMR
 SG_ ActvnOfAhl : 48|1@0+ (1,0) [0|1] "" HCML,HCMR
 SG_ ActvnOfAhl_UB : 49|1@0+ (1,0) [0|1] "" HCML,HCMR
 SG_ ActvnOfBrkLi : 50|1@0+ (1,0) [0|1] "" Vector_XXX
 SG_ ActvnOfBrkLi_UB : 51|1@0+ (1,0) [0|1] "" Vector_XXX
 SG_ ActvnOfDbl : 52|1@0+ (1,0) [0|1] "" HCML,HCMR
 SG_ ActvnOfDbl_UB : 53|1@0+ (1,0) [0|1] "" HCML,HCMR
 SG_ ActvnOfGoodByeLi : 54|1@0+ (1,0) [0|1] "" HCML,HCMR
 SG_ ActvnOfGoodByeLi_UB : 55|1@0+ (1,0) [0|1] "" HCML,HCMR
 SG_ ActvnOfTouristMod : 56|1@0+ (1,0) [0|1] "" HCML,HCMR
 SG_ ActvnOfTouristMod_UB : 57|1@0+ (1,0) [0|1] "" HCML,HCMR
 SG_ ActvnOfWelcomeLi : 58|1@0+ (1,0) [0|1] "" HCML,HCMR
 SG_ ActvnOfWelcomeLi_UB : 59|1@0+ (1,0) [0|1] "" HCML,HCMR

BO_ 538 CemBodyExpoFr51: 8 CEM
 SG_ ActvnOfIndcr_UB : 38|1@0+ (1,0) [0|1] "" HCML,HCMR
 SG_ ActvnOfIndcrIndcrOut : 37|2@0+ (1,0) [0|3] "" HCML,HCMR
 SG_ ActvnOfIndcrIndcrOutChks : 47|8@0+ (1.0,0.0) [0.0|255.0] "Unitless" HCML,HCMR
 SG_ ActvnOfIndcrIndcrOutCntr : 35|4@0+ (1.0,0.0) [0.0|15.0] "Unitless" HCML,HCMR
 SG_ EmgyBrkLiIndcrTurn : 49|2@0+ (1,0) [0|3] "" Vector_XXX
 SG_ EmgyBrkLiIndcrTurn_UB : 50|1@0+ (1,0) [0|1] "" Vector_XXX
 SG_ IndcrPat_UB : 39|1@0+ (1,0) [0|1] "" HCML,HCMR
 SG_ IndcrPatCmd1WdTiOff : 7|16@0+ (0.001,0.0) [0.0|65.535] "s" HCML,HCMR
 SG_ IndcrPatCmd1WdTiOn : 23|16@0+ (0.001,0.0) [0.0|65.535] "s" HCML,HCMR
 SG_ IndcrSts : 52|2@0+ (1,0) [0|3] "" HCML,HCMR
 SG_ IndcrSts_UB : 53|1@0+ (1,0) [0|1] "" HCML,HCMR

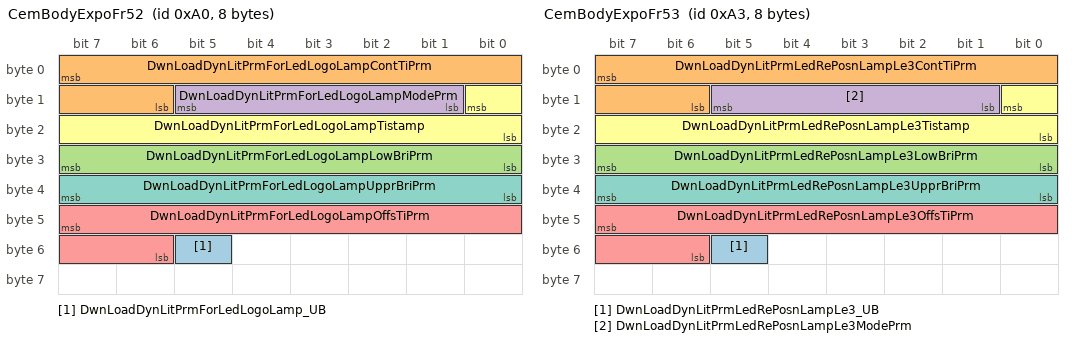
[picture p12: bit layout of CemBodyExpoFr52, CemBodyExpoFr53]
BO_ 160 CemBodyExpoFr52: 8 CEM
 SG_ DwnLoadDynLitPrmForLedLogoLamp_UB : 53|1@0+ (1,0) [0|1] "" Vector_XXX
 SG_ DwnLoadDynLitPrmForLedLogoLampContTiPrm : 7|10@0+ (1.0,0.0) [0.0|1000.0] "Milliseconds" Vector_XXX
 SG_ DwnLoadDynLitPrmForLedLogoLampLowBriPrm : 31|8@0+ (1.0,0.0) [0.0|100.0] "%" Vector_XXX
 SG_ DwnLoadDynLitPrmForLedLogoLampModePrm : 13|5@0+ (1,0) [0|31] "" Vector_XXX
 SG_ DwnLoadDynLitPrmForLedLogoLampOffsTiPrm : 47|10@0+ (1.0,0.0) [0.0|1000.0] "Milliseconds" Vector_XXX
 SG_ DwnLoadDynLitPrmForLedLogoLampTistamp : 8|9@0+ (1.0,0.0) [0.0|511.0] "Unitless" Vector_XXX
 SG_ DwnLoadDynLitPrmForLedLogoLampUpprBriPrm : 39|8@0+ (1.0,0.0) [0.0|100.0] "%" Vector_XXX

BO_ 163 CemBodyExpoFr53: 8 CEM
 SG_ DwnLoadDynLitPrmLedRePosnLampLe3_UB : 53|1@0+ (1,0) [0|1] "" Vector_XXX
 SG_ DwnLoadDynLitPrmLedRePosnLampLe3ContTiPrm : 7|10@0+ (1.0,0.0) [0.0|1000.0] "Milliseconds" Vector_XXX
 SG_ DwnLoadDynLitPrmLedRePosnLampLe3LowBriPrm : 31|8@0+ (1.0,0.0) [0.0|100.0] "%" Vector_XXX
 SG_ DwnLoadDynLitPrmLedRePosnLampLe3ModePrm : 13|5@0+ (1,0) [0|31] "" Vector_XXX
 SG_ DwnLoadDynLitPrmLedRePosnLampLe3OffsTiPrm : 47|10@0+ (1.0,0.0) [0.0|1000.0] "Milliseconds" Vector_XXX
 SG_ DwnLoadDynLitPrmLedRePosnLampLe3Tistamp : 8|9@0+ (1.0,0.0) [0.0|511.0] "Unitless" Vector_XXX
 SG_ DwnLoadDynLitPrmLedRePosnLampLe3UpprBriPrm : 39|8@0+ (1.0,0.0) [0.0|100.0] "%" Vector_XXX

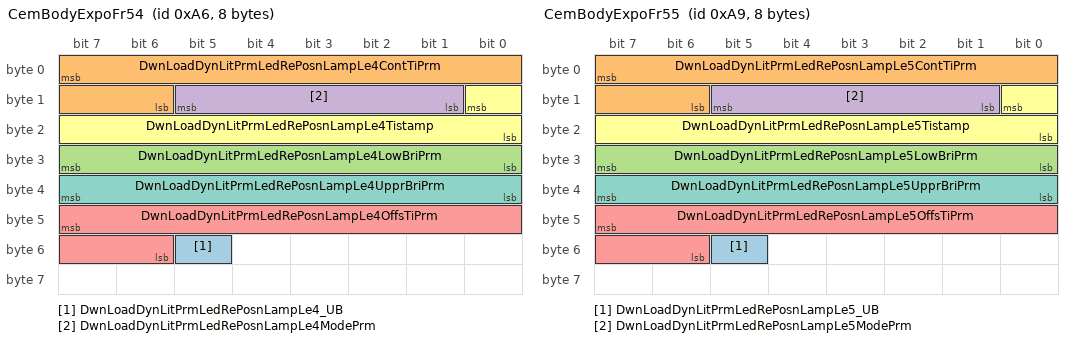
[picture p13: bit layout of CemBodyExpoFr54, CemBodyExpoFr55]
BO_ 166 CemBodyExpoFr54: 8 CEM
 SG_ DwnLoadDynLitPrmLedRePosnLampLe4_UB : 53|1@0+ (1,0) [0|1] "" Vector_XXX
 SG_ DwnLoadDynLitPrmLedRePosnLampLe4ContTiPrm : 7|10@0+ (1.0,0.0) [0.0|1000.0] "Milliseconds" Vector_XXX
 SG_ DwnLoadDynLitPrmLedRePosnLampLe4LowBriPrm : 31|8@0+ (1.0,0.0) [0.0|100.0] "%" Vector_XXX
 SG_ DwnLoadDynLitPrmLedRePosnLampLe4ModePrm : 13|5@0+ (1,0) [0|31] "" Vector_XXX
 SG_ DwnLoadDynLitPrmLedRePosnLampLe4OffsTiPrm : 47|10@0+ (1.0,0.0) [0.0|1000.0] "Milliseconds" Vector_XXX
 SG_ DwnLoadDynLitPrmLedRePosnLampLe4Tistamp : 8|9@0+ (1.0,0.0) [0.0|511.0] "Unitless" Vector_XXX
 SG_ DwnLoadDynLitPrmLedRePosnLampLe4UpprBriPrm : 39|8@0+ (1.0,0.0) [0.0|100.0] "%" Vector_XXX

BO_ 169 CemBodyExpoFr55: 8 CEM
 SG_ DwnLoadDynLitPrmLedRePosnLampLe5_UB : 53|1@0+ (1,0) [0|1] "" Vector_XXX
 SG_ DwnLoadDynLitPrmLedRePosnLampLe5ContTiPrm : 7|10@0+ (1.0,0.0) [0.0|1000.0] "Milliseconds" Vector_XXX
 SG_ DwnLoadDynLitPrmLedRePosnLampLe5LowBriPrm : 31|8@0+ (1.0,0.0) [0.0|100.0] "%" Vector_XXX
 SG_ DwnLoadDynLitPrmLedRePosnLampLe5ModePrm : 13|5@0+ (1,0) [0|31] "" Vector_XXX
 SG_ DwnLoadDynLitPrmLedRePosnLampLe5OffsTiPrm : 47|10@0+ (1.0,0.0) [0.0|1000.0] "Milliseconds" Vector_XXX
 SG_ DwnLoadDynLitPrmLedRePosnLampLe5Tistamp : 8|9@0+ (1.0,0.0) [0.0|511.0] "Unitless" Vector_XXX
 SG_ DwnLoadDynLitPrmLedRePosnLampLe5UpprBriPrm : 39|8@0+ (1.0,0.0) [0.0|100.0] "%" Vector_XXX

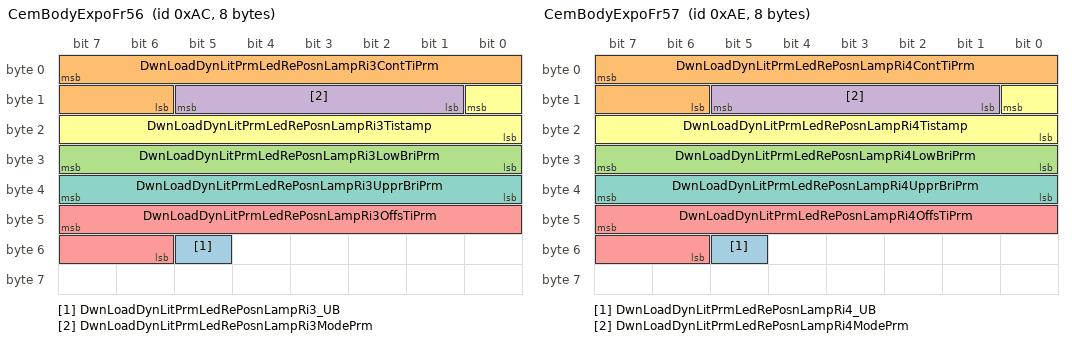
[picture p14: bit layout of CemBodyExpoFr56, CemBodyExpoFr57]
BO_ 172 CemBodyExpoFr56: 8 CEM
 SG_ DwnLoadDynLitPrmLedRePosnLampRi3_UB : 53|1@0+ (1,0) [0|1] "" Vector_XXX
 SG_ DwnLoadDynLitPrmLedRePosnLampRi3ContTiPrm : 7|10@0+ (1.0,0.0) [0.0|1000.0] "Milliseconds" Vector_XXX
 SG_ DwnLoadDynLitPrmLedRePosnLampRi3LowBriPrm : 31|8@0+ (1.0,0.0) [0.0|100.0] "%" Vector_XXX
 SG_ DwnLoadDynLitPrmLedRePosnLampRi3ModePrm : 13|5@0+ (1,0) [0|31] "" Vector_XXX
 SG_ DwnLoadDynLitPrmLedRePosnLampRi3OffsTiPrm : 47|10@0+ (1.0,0.0) [0.0|1000.0] "Milliseconds" Vector_XXX
 SG_ DwnLoadDynLitPrmLedRePosnLampRi3Tistamp : 8|9@0+ (1.0,0.0) [0.0|511.0] "Unitless" Vector_XXX
 SG_ DwnLoadDynLitPrmLedRePosnLampRi3UpprBriPrm : 39|8@0+ (1.0,0.0) [0.0|100.0] "%" Vector_XXX

BO_ 174 CemBodyExpoFr57: 8 CEM
 SG_ DwnLoadDynLitPrmLedRePosnLampRi4_UB : 53|1@0+ (1,0) [0|1] "" Vector_XXX
 SG_ DwnLoadDynLitPrmLedRePosnLampRi4ContTiPrm : 7|10@0+ (1.0,0.0) [0.0|1000.0] "Milliseconds" Vector_XXX
 SG_ DwnLoadDynLitPrmLedRePosnLampRi4LowBriPrm : 31|8@0+ (1.0,0.0) [0.0|100.0] "%" Vector_XXX
 SG_ DwnLoadDynLitPrmLedRePosnLampRi4ModePrm : 13|5@0+ (1,0) [0|31] "" Vector_XXX
 SG_ DwnLoadDynLitPrmLedRePosnLampRi4OffsTiPrm : 47|10@0+ (1.0,0.0) [0.0|1000.0] "Milliseconds" Vector_XXX
 SG_ DwnLoadDynLitPrmLedRePosnLampRi4Tistamp : 8|9@0+ (1.0,0.0) [0.0|511.0] "Unitless" Vector_XXX
 SG_ DwnLoadDynLitPrmLedRePosnLampRi4UpprBriPrm : 39|8@0+ (1.0,0.0) [0.0|100.0] "%" Vector_XXX

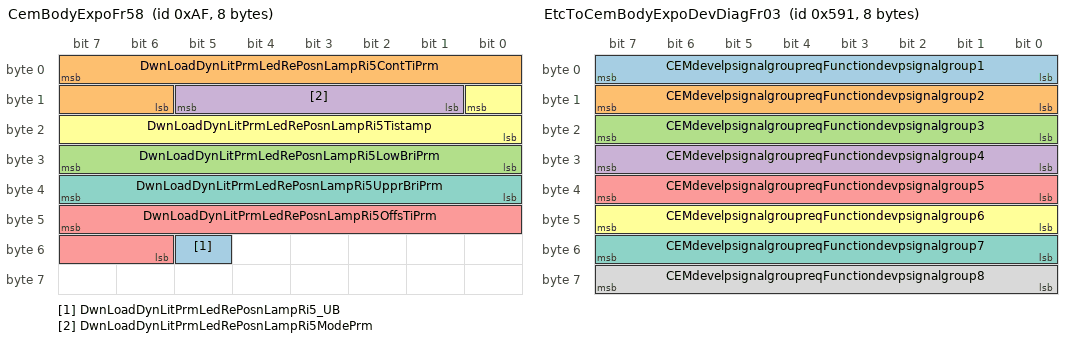
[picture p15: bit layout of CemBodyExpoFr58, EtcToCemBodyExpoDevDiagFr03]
BO_ 175 CemBodyExpoFr58: 8 CEM
 SG_ DwnLoadDynLitPrmLedRePosnLampRi5_UB : 53|1@0+ (1,0) [0|1] "" Vector_XXX
 SG_ DwnLoadDynLitPrmLedRePosnLampRi5ContTiPrm : 7|10@0+ (1.0,0.0) [0.0|1000.0] "Milliseconds" Vector_XXX
 SG_ DwnLoadDynLitPrmLedRePosnLampRi5LowBriPrm : 31|8@0+ (1.0,0.0) [0.0|100.0] "%" Vector_XXX
 SG_ DwnLoadDynLitPrmLedRePosnLampRi5ModePrm : 13|5@0+ (1,0) [0|31] "" Vector_XXX
 SG_ DwnLoadDynLitPrmLedRePosnLampRi5OffsTiPrm : 47|10@0+ (1.0,0.0) [0.0|1000.0] "Milliseconds" Vector_XXX
 SG_ DwnLoadDynLitPrmLedRePosnLampRi5Tistamp : 8|9@0+ (1.0,0.0) [0.0|511.0] "Unitless" Vector_XXX
 SG_ DwnLoadDynLitPrmLedRePosnLampRi5UpprBriPrm : 39|8@0+ (1.0,0.0) [0.0|100.0] "%" Vector_XXX

BO_ 2047 CemToAllFuncBodyCanExposedDiagReqFrame: 8 CEM
 SG_ CemToAllFuncBodyCanExpDiagReqNpdu : 7|64@0+ (1,0) [0|0] "" HCML, HCMR

BO_ 1971 CemToHcmlBodyCanExposedDiagReqFrame: 8 CEM
 SG_ CemToHcmlBodyCanExpDiagReqNpdu : 7|64@0+ (1,0) [0|0] "" HCML

BO_ 1972 CemToHcmrBodyCanExposedDiagReqFrame: 8 CEM
 SG_ CemToHcmrBodyCanExpDiagReqNpdu : 7|64@0+ (1,0) [0|0] "" HCMR

BO_ 1973 CemToRcmlBodyCanExposedDiagReqFrame: 8 CEM
 SG_ CemToRcmlBodyCanExpDiagReqNpdu : 7|64@0+ (1,0) [0|0] "" Vector_XXX

BO_ 1975 CemToRcmmBodyCanExposedDiagReqFrame: 8 CEM
 SG_ CemToRcmmBodyCanExpDiagReqNpdu : 7|64@0+ (1,0) [0|0] "" Vector_XXX

BO_ 1974 CemToRcmrBodyCanExposedDiagReqFrame: 8 CEM
 SG_ CemToRcmrBodyCanExpDiagReqNpdu : 7|64@0+ (1,0) [0|0] "" Vector_XXX

BO_ 1425 EtcToCemBodyExpoDevDiagFr03: 8 ETC
 SG_ CEMdevelpsignalgroupreqFunctiondevpsignalgroup1 : 7|8@0+ (1.0,0.0) [0.0|255.0] "Unitless" CEM
 SG_ CEMdevelpsignalgroupreqFunctiondevpsignalgroup2 : 15|8@0+ (1.0,0.0) [0.0|255.0] "Unitless" CEM
 SG_ CEMdevelpsignalgroupreqFunctiondevpsignalgroup3 : 23|8@0+ (1.0,0.0) [0.0|255.0] "Unitless" CEM
 SG_ CEMdevelpsignalgroupreqFunctiondevpsignalgroup4 : 31|8@0+ (1.0,0.0) [0.0|255.0] "Unitless" CEM
 SG_ CEMdevelpsignalgroupreqFunctiondevpsignalgroup5 : 39|8@0+ (1.0,0.0) [0.0|255.0] "Unitless" CEM
 SG_ CEMdevelpsignalgroupreqFunctiondevpsignalgroup6 : 47|8@0+ (1.0,0.0) [0.0|255.0] "Unitless" CEM
 SG_ CEMdevelpsignalgroupreqFunctiondevpsignalgroup7 : 55|8@0+ (1.0,0.0) [0.0|255.0] "Unitless" CEM
 SG_ CEMdevelpsignalgroupreqFunctiondevpsignalgroup8 : 63|8@0+ (1.0,0.0) [0.0|255.0] "Unitless" CEM

BO_ 1430 EtctoHcmlXCPFr01: 8 ETC

BO_ 1428 EtctoHcmrXCPFr01: 8 ETC

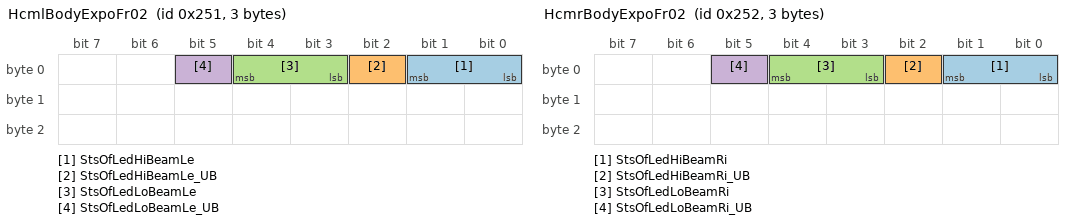
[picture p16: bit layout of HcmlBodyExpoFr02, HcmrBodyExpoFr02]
BO_ 593 HcmlBodyExpoFr02: 3 HCML
 SG_ StsOfLedHiBeamLe : 1|2@0+ (1,0) [0|3] "" CEM
 SG_ StsOfLedHiBeamLe_UB : 2|1@0+ (1,0) [0|1] "" CEM
 SG_ StsOfLedLoBeamLe : 4|2@0+ (1,0) [0|3] "" CEM
 SG_ StsOfLedLoBeamLe_UB : 5|1@0+ (1,0) [0|1] "" CEM

BO_ 124 HcmlBodyExpoFr04: 8 HCML
 SG_ DwnLoadStsFbOfHdlampLe : 5|2@0+ (1,0) [0|3] "" CEM
 SG_ DwnLoadStsFbOfHdlampLe_UB : 39|1@0+ (1,0) [0|1] "" CEM
 SG_ ExtrLiShowActvnFrntLeFb : 28|2@0+ (1,0) [0|3] "" CEM
 SG_ ExtrLiShowActvnFrntLeFb_UB : 20|1@0+ (1,0) [0|1] "" CEM
 SG_ HdlampLeInpSts1 : 49|1@0+ (1,0) [0|1] "" CEM
 SG_ HdlampLeInpSts1_UB : 48|1@0+ (1,0) [0|1] "" CEM
 SG_ HdlampLeInpSts2 : 63|1@0+ (1,0) [0|1] "" CEM
 SG_ HdlampLeInpSts2_UB : 62|1@0+ (1,0) [0|1] "" CEM
 SG_ StsOfAfsLe : 1|2@0+ (1,0) [0|3] "" CEM
 SG_ StsOfAfsLe_UB : 38|1@0+ (1,0) [0|1] "" CEM
 SG_ StsOfAhbcLe : 3|2@0+ (1,0) [0|3] "" CEM
 SG_ StsOfAhbcLe_UB : 37|1@0+ (1,0) [0|1] "" CEM
 SG_ StsOfFrntSideMkrLampLe2 : 9|2@0+ (1,0) [0|3] "" CEM
 SG_ StsOfFrntSideMkrLampLe2_UB : 34|1@0+ (1,0) [0|1] "" CEM
 SG_ StsOfLedCornrgLampLe : 11|2@0+ (1,0) [0|3] "" CEM
 SG_ StsOfLedCornrgLampLe_UB : 33|1@0+ (1,0) [0|1] "" CEM
 SG_ StsOfLedDaytiRunngLampLe : 13|2@0+ (1,0) [0|3] "" CEM
 SG_ StsOfLedDaytiRunngLampLe_UB : 32|1@0+ (1,0) [0|1] "" CEM
 SG_ StsOfLedFrntFogLampLe : 15|2@0+ (1,0) [0|3] "" CEM
 SG_ StsOfLedFrntFogLampLe_UB : 31|1@0+ (1,0) [0|1] "" CEM
 SG_ StsOfLedFrntPosnLampLe : 17|2@0+ (1,0) [0|3] "" CEM
 SG_ StsOfLedFrntPosnLampLe_UB : 30|1@0+ (1,0) [0|1] "" CEM
 SG_ StsOfLedFrntTurnIndcrLe : 19|2@0+ (1,0) [0|3] "" CEM
 SG_ StsOfLedFrntTurnIndcrLe_UB : 29|1@0+ (1,0) [0|1] "" CEM
 SG_ StsOfLvlgLe_UB : 36|1@0+ (1,0) [0|1] "" CEM
 SG_ StsOfLvlgLeChks : 47|8@0+ (1.0,0.0) [0.0|255.0] "Unitless" CEM
 SG_ StsOfLvlgLeCntr : 55|4@0+ (1.0,0.0) [0.0|15.0] "Unitless" CEM
 SG_ StsOfLvlgLeStsOfLvlgLe : 51|2@0+ (1,0) [0|3] "" CEM
 SG_ StsOfSwvlgLe : 7|2@0+ (1,0) [0|3] "" CEM
 SG_ StsOfSwvlgLe_UB : 35|1@0+ (1,0) [0|1] "" CEM
 SG_ StsOfTouristModLe : 25|2@0+ (1,0) [0|3] "" CEM
 SG_ StsOfTouristModLe_UB : 26|1@0+ (1,0) [0|1] "" CEM

BO_ 1329 HcmlBodyExposedNMFr: 8 HCML
 SG_ PNC16_HCML : 16|1@0+ (1,0) [0|0] "" HCMR
 SG_ PNC17_HCML : 17|1@0+ (1,0) [0|0] "" HCMR
 SG_ PNC18_HCML : 18|1@0+ (1,0) [0|0] "" HCMR
 SG_ PNC19_HCML : 19|1@0+ (1,0) [0|0] "" HCMR
 SG_ PNC20_HCML : 20|1@0+ (1,0) [0|0] "" HCMR
 SG_ PNC21_HCML : 21|1@0+ (1,0) [0|0] "" HCMR
 SG_ PNC22_HCML : 22|1@0+ (1,0) [0|0] "" HCMR
 SG_ PNC23_HCML : 23|1@0+ (1,0) [0|0] "" HCMR
 SG_ PNC24_HCML : 24|1@0+ (1,0) [0|0] "" HCMR
 SG_ PNC25_HCML : 25|1@0+ (1,0) [0|0] "" HCMR
 SG_ PNC26_HCML : 26|1@0+ (1,0) [0|0] "" HCMR
 SG_ PNC27_HCML : 27|1@0+ (1,0) [0|0] "" HCMR
 SG_ PNC28_HCML : 28|1@0+ (1,0) [0|0] "" HCMR
 SG_ PNC29_HCML : 29|1@0+ (1,0) [0|0] "" HCMR
 SG_ PNC30_HCML : 30|1@0+ (1,0) [0|0] "" HCMR
 SG_ PNC31_HCML : 31|1@0+ (1,0) [0|0] "" HCMR
 SG_ PNC32_HCML : 32|1@0+ (1,0) [0|0] "" HCMR
 SG_ PNC33_HCML : 33|1@0+ (1,0) [0|0] "" HCMR
 SG_ PNC34_HCML : 34|1@0+ (1,0) [0|0] "" HCMR
 SG_ PNC35_HCML : 35|1@0+ (1,0) [0|0] "" HCMR
 SG_ PNC36_HCML : 36|1@0+ (1,0) [0|0] "" HCMR
 SG_ PNC37_HCML : 37|1@0+ (1,0) [0|0] "" HCMR
 SG_ PNC38_HCML : 38|1@0+ (1,0) [0|0] "" HCMR
 SG_ PNC39_HCML : 39|1@0+ (1,0) [0|0] "" HCMR
 SG_ NM_PNI_HCML : 14|1@0+ (1,0) [0|0] "" HCMR
 SG_ NM_AW_HCML : 12|1@0+ (1,0) [0|0] "" HCMR
 SG_ NM_CS_HCML : 11|1@0+ (1,0) [0|0] "" HCMR
 SG_ NM_RMR_HCML : 8|1@0+ (1,0) [0|0] "" HCMR
 SG_ NM_NodeID_HCML : 7|8@0+ (1,0) [0|0] "" HCMR

BO_ 1715 HcmlToCemBodyCanExposedDiagResFrame: 8 HCML
 SG_ HcmlToCemBodyCanExpDiagResNpdu : 7|64@0+ (1,0) [0|0] "" CEM

BO_ 1424 HcmltoEtcXCPFr01: 8 HCML

BO_ 594 HcmrBodyExpoFr02: 3 HCMR
 SG_ StsOfLedHiBeamRi : 1|2@0+ (1,0) [0|3] "" CEM
 SG_ StsOfLedHiBeamRi_UB : 2|1@0+ (1,0) [0|1] "" CEM
 SG_ StsOfLedLoBeamRi : 4|2@0+ (1,0) [0|3] "" CEM
 SG_ StsOfLedLoBeamRi_UB : 5|1@0+ (1,0) [0|1] "" CEM

BO_ 127 HcmrBodyExpoFr04: 8 HCMR
 SG_ DwnLoadStsFbOfHdlampRi : 5|2@0+ (1,0) [0|3] "" CEM
 SG_ DwnLoadStsFbOfHdlampRi_UB : 39|1@0+ (1,0) [0|1] "" CEM
 SG_ ExtrLiShowActvnFrntRiFb : 28|2@0+ (1,0) [0|3] "" CEM
 SG_ ExtrLiShowActvnFrntRiFb_UB : 20|1@0+ (1,0) [0|1] "" CEM
 SG_ HdlampRiInpSts1 : 49|1@0+ (1,0) [0|1] "" CEM
 SG_ HdlampRiInpSts1_UB : 48|1@0+ (1,0) [0|1] "" CEM
 SG_ HdlampRiInpSts2 : 63|1@0+ (1,0) [0|1] "" CEM
 SG_ HdlampRiInpSts2_UB : 62|1@0+ (1,0) [0|1] "" CEM
 SG_ StsOfAfsRi : 1|2@0+ (1,0) [0|3] "" CEM
 SG_ StsOfAfsRi_UB : 38|1@0+ (1,0) [0|1] "" CEM
 SG_ StsOfAhbcRi : 3|2@0+ (1,0) [0|3] "" CEM
 SG_ StsOfAhbcRi_UB : 37|1@0+ (1,0) [0|1] "" CEM
 SG_ StsOfFrntSideMkrLampRi2 : 9|2@0+ (1,0) [0|3] "" CEM
 SG_ StsOfFrntSideMkrLampRi2_UB : 34|1@0+ (1,0) [0|1] "" CEM
 SG_ StsOfLedCornrgLampRi : 11|2@0+ (1,0) [0|3] "" CEM
 SG_ StsOfLedCornrgLampRi_UB : 33|1@0+ (1,0) [0|1] "" CEM
 SG_ StsOfLedDaytiRunngLampRi : 13|2@0+ (1,0) [0|3] "" CEM
 SG_ StsOfLedDaytiRunngLampRi_UB : 32|1@0+ (1,0) [0|1] "" CEM
 SG_ StsOfLedFrntFogLampRi : 15|2@0+ (1,0) [0|3] "" CEM
 SG_ StsOfLedFrntFogLampRi_UB : 31|1@0+ (1,0) [0|1] "" CEM
 SG_ StsOfLedFrntPosnLampRi : 17|2@0+ (1,0) [0|3] "" CEM
 SG_ StsOfLedFrntPosnLampRi_UB : 30|1@0+ (1,0) [0|1] "" CEM
 SG_ StsOfLedFrntTurnIndcrRi : 19|2@0+ (1,0) [0|3] "" CEM
 SG_ StsOfLedFrntTurnIndcrRi_UB : 29|1@0+ (1,0) [0|1] "" CEM
 SG_ StsOfLvlgRi_UB : 36|1@0+ (1,0) [0|1] "" CEM
 SG_ StsOfLvlgRiChks : 47|8@0+ (1.0,0.0) [0.0|255.0] "Unitless" CEM
 SG_ StsOfLvlgRiCntr : 55|4@0+ (1.0,0.0) [0.0|15.0] "Unitless" CEM
 SG_ StsOfLvlgRiStsOfLvlgRi : 51|2@0+ (1,0) [0|3] "" CEM
 SG_ StsOfSwvlgRi : 7|2@0+ (1,0) [0|3] "" CEM
 SG_ StsOfSwvlgRi_UB : 35|1@0+ (1,0) [0|1] "" CEM
 SG_ StsOfTouristModRi : 25|2@0+ (1,0) [0|3] "" CEM
 SG_ StsOfTouristModRi_UB : 26|1@0+ (1,0) [0|1] "" CEM

BO_ 1330 HcmrBodyExposedNMFr: 8 HCMR
 SG_ PNC16_HCMR : 16|1@0+ (1,0) [0|0] "" CEM
 SG_ PNC17_HCMR : 17|1@0+ (1,0) [0|0] "" CEM
 SG_ PNC18_HCMR : 18|1@0+ (1,0) [0|0] "" CEM
 SG_ PNC19_HCMR : 19|1@0+ (1,0) [0|0] "" CEM
 SG_ PNC20_HCMR : 20|1@0+ (1,0) [0|0] "" CEM
 SG_ PNC21_HCMR : 21|1@0+ (1,0) [0|0] "" CEM
 SG_ PNC22_HCMR : 22|1@0+ (1,0) [0|0] "" CEM
 SG_ PNC23_HCMR : 23|1@0+ (1,0) [0|0] "" CEM
 SG_ PNC24_HCMR : 24|1@0+ (1,0) [0|0] "" CEM
 SG_ PNC25_HCMR : 25|1@0+ (1,0) [0|0] "" CEM
 SG_ PNC26_HCMR : 26|1@0+ (1,0) [0|0] "" CEM
 SG_ PNC27_HCMR : 27|1@0+ (1,0) [0|0] "" CEM
 SG_ PNC28_HCMR : 28|1@0+ (1,0) [0|0] "" CEM
 SG_ PNC29_HCMR : 29|1@0+ (1,0) [0|0] "" CEM
 SG_ PNC30_HCMR : 30|1@0+ (1,0) [0|0] "" CEM
 SG_ PNC31_HCMR : 31|1@0+ (1,0) [0|0] "" CEM
 SG_ PNC32_HCMR : 32|1@0+ (1,0) [0|0] "" CEM
 SG_ PNC33_HCMR : 33|1@0+ (1,0) [0|0] "" CEM
 SG_ PNC34_HCMR : 34|1@0+ (1,0) [0|0] "" CEM
 SG_ PNC35_HCMR : 35|1@0+ (1,0) [0|0] "" CEM
 SG_ PNC36_HCMR : 36|1@0+ (1,0) [0|0] "" CEM
 SG_ PNC37_HCMR : 37|1@0+ (1,0) [0|0] "" CEM
 SG_ PNC38_HCMR : 38|1@0+ (1,0) [0|0] "" CEM
 SG_ PNC39_HCMR : 39|1@0+ (1,0) [0|0] "" CEM
 SG_ NM_PNI_HCMR : 14|1@0+ (1,0) [0|0] "" CEM
 SG_ NM_AW_HCMR : 12|1@0+ (1,0) [0|0] "" CEM
 SG_ NM_CS_HCMR : 11|1@0+ (1,0) [0|0] "" CEM
 SG_ NM_RMR_HCMR : 8|1@0+ (1,0) [0|0] "" CEM
 SG_ NM_NodeID_HCMR : 7|8@0+ (1,0) [0|0] "" CEM

BO_ 1716 HcmrToCemBodyCanExposedDiagResFrame: 8 HCMR
 SG_ HcmrToCemBodyCanExpDiagResNpdu : 7|64@0+ (1,0) [0|0] "" CEM

BO_ 1426 HcmrtoEtcXCPFr01: 8 HCMR

CM_ SG_ 99 DwnLoadDynLitPrmLedReTurnIndcrRi1ContTiPrm "Light Show Continue Time Parameter 1";
CM_ SG_ 99 DwnLoadDynLitPrmLedReTurnIndcrRi1LowBriPrm "Light Show Lower Brightness Parameter 1";
CM_ SG_ 99 DwnLoadDynLitPrmLedReTurnIndcrRi1ModePrm "Light Show Mode Parameter 1";
CM_ SG_ 99 DwnLoadDynLitPrmLedReTurnIndcrRi1OffsTiPrm "Light Show Offset Time Parameter 1";
CM_ SG_ 99 DwnLoadDynLitPrmLedReTurnIndcrRi1Tistamp "Light Show time stamp";
CM_ SG_ 99 DwnLoadDynLitPrmLedReTurnIndcrRi1UpprBriPrm "Light Show Upper Brightness Parameter 1";
CM_ SG_ 103 DwnLoadDynLitPrmLedRvsgLampLe1ContTiPrm "Light Show Continue Time Parameter 1";
CM_ SG_ 103 DwnLoadDynLitPrmLedRvsgLampLe1LowBriPrm "Light Show Lower Brightness Parameter 1";
CM_ SG_ 103 DwnLoadDynLitPrmLedRvsgLampLe1ModePrm "Light Show Mode Parameter 1";
CM_ SG_ 103 DwnLoadDynLitPrmLedRvsgLampLe1OffsTiPrm "Light Show Offset Time Parameter 1";
CM_ SG_ 103 DwnLoadDynLitPrmLedRvsgLampLe1Tistamp "Light Show time stamp";
CM_ SG_ 103 DwnLoadDynLitPrmLedRvsgLampLe1UpprBriPrm "Light Show Upper Brightness Parameter 1";
CM_ SG_ 107 DwnLoadDynLitPrmLedRvsgLampLe2ContTiPrm "Light Show Continue Time Parameter 1";
CM_ SG_ 107 DwnLoadDynLitPrmLedRvsgLampLe2LowBriPrm "Light Show Lower Brightness Parameter 1";
CM_ SG_ 107 DwnLoadDynLitPrmLedRvsgLampLe2ModePrm "Light Show Mode Parameter 1";
CM_ SG_ 107 DwnLoadDynLitPrmLedRvsgLampLe2OffsTiPrm "Light Show Offset Time Parameter 1";
CM_ SG_ 107 DwnLoadDynLitPrmLedRvsgLampLe2Tistamp "Light Show time stamp";
CM_ SG_ 107 DwnLoadDynLitPrmLedRvsgLampLe2UpprBriPrm "Light Show Upper Brightness Parameter 1";
CM_ SG_ 111 DwnLoadDynLitPrmLedRvsgLampRi1ContTiPrm "Light Show Continue Time Parameter 1";
CM_ SG_ 111 DwnLoadDynLitPrmLedRvsgLampRi1LowBriPrm "Light Show Lower Brightness Parameter 1";
CM_ SG_ 111 DwnLoadDynLitPrmLedRvsgLampRi1ModePrm "Light Show Mode Parameter 1";
CM_ SG_ 111 DwnLoadDynLitPrmLedRvsgLampRi1OffsTiPrm "Light Show Offset Time Parameter 1";
CM_ SG_ 111 DwnLoadDynLitPrmLedRvsgLampRi1Tistamp "Light Show time stamp";
CM_ SG_ 111 DwnLoadDynLitPrmLedRvsgLampRi1UpprBriPrm "Light Show Upper Brightness Parameter 1";
CM_ SG_ 120 LvlgSwtSetReqADModCtrlInhbn "0.LvlgSwtSetReq.Level0
1.LvlgSwtSetReq.Level1
2.LvlgSwtSetReq.Level2
3.LvlgSwtSetReq.Level3
4.LvlgSwtSetReq.Level4
5.LvlgSwtSetReq.Level5";
CM_ SG_ 120 LvlgSwtSetReqChks "checksum";
CM_ SG_ 120 LvlgSwtSetReqCntr "counter";
CM_ SG_ 120 OutdBriChks "Input for controlling lights on and off automatically. Checksum";
CM_ SG_ 120 OutdBriCntr "Input for controlling lights on and off automatically. Counter";
CM_ SG_ 120 OutdBriSts "Input for controlling lights on and off automatically. Status information.";
CM_ SG_ 407 DwnLoadDynLitPrmForLedHiBeamLeContTiPrm "Light Show Continue Time Parameter 1";
CM_ SG_ 407 DwnLoadDynLitPrmForLedHiBeamLeLowBriPrm "Light Show Lower Brightness Parameter 1";
CM_ SG_ 407 DwnLoadDynLitPrmForLedHiBeamLeModePrm "Light Show Mode Parameter 1";
CM_ SG_ 407 DwnLoadDynLitPrmForLedHiBeamLeOffsTiPrm "Light Show Offset time Parameter 1";
CM_ SG_ 407 DwnLoadDynLitPrmForLedHiBeamLeTistamp "Light Show time stamp";
CM_ SG_ 407 DwnLoadDynLitPrmForLedHiBeamLeUpprBriPrm "Light Show Upper Brightness Parameter 1";
CM_ SG_ 412 DwnLoadDynLitPrmForLedLoBeamLeContTiPrm "Light Show Continue Time Parameter 1";
CM_ SG_ 412 DwnLoadDynLitPrmForLedLoBeamLeLowBriPrm "Light Show Lower Brightness Parameter 1";
CM_ SG_ 412 DwnLoadDynLitPrmForLedLoBeamLeModePrm "Light Show Mode Parameter 1";
CM_ SG_ 412 DwnLoadDynLitPrmForLedLoBeamLeOffsTiPrm "Light Show Offset Time Parameter 1";
CM_ SG_ 412 DwnLoadDynLitPrmForLedLoBeamLeTistamp "Light Show time stamp";
CM_ SG_ 412 DwnLoadDynLitPrmForLedLoBeamLeUpprBriPrm "Light Show Upper Brightness Parameter 1";
CM_ SG_ 415 DwnLoadDynLtgPrmForLedAllWthrLampLeContTiPrm "Light Show Continue Time Parameter 1";
CM_ SG_ 415 DwnLoadDynLtgPrmForLedAllWthrLampLeLowBriPrm "Light Show Lower Brightness Parameter 1";
CM_ SG_ 415 DwnLoadDynLtgPrmForLedAllWthrLampLeModePrm "Light Show Mode Parameter 1";
CM_ SG_ 415 DwnLoadDynLtgPrmForLedAllWthrLampLeOffsTiPrm "Light Show Offset Time Parameter 1";
CM_ SG_ 415 DwnLoadDynLtgPrmForLedAllWthrLampLeTistamp "Light Show time stamp";
CM_ SG_ 415 DwnLoadDynLtgPrmForLedAllWthrLampLeUpprBriPrm "Light Show Upper Brightness Parameter 1";
CM_ SG_ 419 DwnLoadDynLtgPrmForLedAllWthrLampRiContTiPrm "Light Show Continue Time Parameter 1";
CM_ SG_ 419 DwnLoadDynLtgPrmForLedAllWthrLampRiLowBriPrm "Light Show Lower Brightness Parameter 1";
CM_ SG_ 419 DwnLoadDynLtgPrmForLedAllWthrLampRiModePrm "Light Show Mode Parameter 1";
CM_ SG_ 419 DwnLoadDynLtgPrmForLedAllWthrLampRiOffsTiPrm "Light Show Offset Time Parameter 1";
CM_ SG_ 419 DwnLoadDynLtgPrmForLedAllWthrLampRiTistamp "Light Show time stamp";
CM_ SG_ 419 DwnLoadDynLtgPrmForLedAllWthrLampRiUpprBriPrm "Light Show Upper Brightness Parameter 1";
CM_ SG_ 423 DwnLoadDynLtgPrmForLedCornrgLampLeContTiPrm "Light Show Continue Time Parameter 1";
CM_ SG_ 423 DwnLoadDynLtgPrmForLedCornrgLampLeLowBriPrm "Light Show Lower Brightness Parameter 1";
CM_ SG_ 423 DwnLoadDynLtgPrmForLedCornrgLampLeModePrm "Light Show Mode Parameter 1";
CM_ SG_ 423 DwnLoadDynLtgPrmForLedCornrgLampLeOffsTiPrm "Light Show Offset Time Parameter 1";
CM_ SG_ 423 DwnLoadDynLtgPrmForLedCornrgLampLeTistamp "Light Show time stamp";
CM_ SG_ 423 DwnLoadDynLtgPrmForLedCornrgLampLeUpprBriPrm "Light Show Upper Brightness Parameter 1";
CM_ SG_ 427 DwnLoadDynLtgPrmForLedCornrgLampRiContTiPrm "Light Show Continue Time Parameter 1";
CM_ SG_ 427 DwnLoadDynLtgPrmForLedCornrgLampRiLowBriPrm "Light Show Lower Brightness Parameter 1";
CM_ SG_ 427 DwnLoadDynLtgPrmForLedCornrgLampRiModePrm "Light Show Mode Parameter 1";
CM_ SG_ 427 DwnLoadDynLtgPrmForLedCornrgLampRiOffsTiPrm "Light Show Offset Time Parameter 1";
CM_ SG_ 427 DwnLoadDynLtgPrmForLedCornrgLampRiTistamp "Light Show time stamp";
CM_ SG_ 427 DwnLoadDynLtgPrmForLedCornrgLampRiUpprBriPrm "Light Show Upper Brightness Parameter 1";
CM_ SG_ 430 DwnLoadDynLtgPrmForLedDaytiRunngLampLeContTiPrm "Light Show Continue Time Parameter 1";
CM_ SG_ 430 DwnLoadDynLtgPrmForLedDaytiRunngLampLeLowBriPrm "Light Show Lower Brightness Parameter 1";
CM_ SG_ 430 DwnLoadDynLtgPrmForLedDaytiRunngLampLeModePrm "Light Show Mode Parameter 1";
CM_ SG_ 430 DwnLoadDynLtgPrmForLedDaytiRunngLampLeOffsTiPrm "Light Show Offset Time Parameter 1";
CM_ SG_ 430 DwnLoadDynLtgPrmForLedDaytiRunngLampLeTistamp "Light Show time stamp";
CM_ SG_ 430 DwnLoadDynLtgPrmForLedDaytiRunngLampLeUpprBriPrm "Light Show Upper Brightness Parameter 1";
CM_ SG_ 436 DwnLoadDynLtgPrmForLedDaytiRunngLampRiContTiPrm "Light Show Continue Time Parameter 1";
CM_ SG_ 436 DwnLoadDynLtgPrmForLedDaytiRunngLampRiLowBriPrm "Light Show Lower Brightness Parameter 1";
CM_ SG_ 436 DwnLoadDynLtgPrmForLedDaytiRunngLampRiModePrm "Light Show Mode Parameter 1";
CM_ SG_ 436 DwnLoadDynLtgPrmForLedDaytiRunngLampRiOffsTiPrm "Light Show Offset Time Parameter 1";
CM_ SG_ 436 DwnLoadDynLtgPrmForLedDaytiRunngLampRiTistamp "Light Show time stamp";
CM_ SG_ 436 DwnLoadDynLtgPrmForLedDaytiRunngLampRiUpprBriPrm "Light Show Upper Brightness Parameter 1";
CM_ SG_ 440 DwnLoadDynLtgPrmForLedFrntPosnLampLeContTiPrm "Light Show Continue Time Parameter 1";
CM_ SG_ 440 DwnLoadDynLtgPrmForLedFrntPosnLampLeLowBriPrm "Light Show Lower Brightness Parameter 1";
CM_ SG_ 440 DwnLoadDynLtgPrmForLedFrntPosnLampLeModePrm "Light Show Mode Parameter 1";
CM_ SG_ 440 DwnLoadDynLtgPrmForLedFrntPosnLampLeOffsTiPrm "Light Show Offset Time Parameter 1";
CM_ SG_ 440 DwnLoadDynLtgPrmForLedFrntPosnLampLeTistamp "Light Show time stamp";
CM_ SG_ 440 DwnLoadDynLtgPrmForLedFrntPosnLampLeUpprBriPrm "Light Show Upper Brightness Parameter 1";
CM_ SG_ 444 DwnLoadDynLtgPrmForLedFrntPosnLampRiContTiPrm "Light Show Continue Time Parameter 1";
CM_ SG_ 444 DwnLoadDynLtgPrmForLedFrntPosnLampRiLowBriPrm "Light Show Lower Brightness Parameter 1";
CM_ SG_ 444 DwnLoadDynLtgPrmForLedFrntPosnLampRiModePrm "Light Show Mode Parameter 1";
CM_ SG_ 444 DwnLoadDynLtgPrmForLedFrntPosnLampRiOffsTiPrm "Light Show Offset Time Parameter 1";
CM_ SG_ 444 DwnLoadDynLtgPrmForLedFrntPosnLampRiTistamp "Light Show time stamp";
CM_ SG_ 444 DwnLoadDynLtgPrmForLedFrntPosnLampRiUpprBriPrm "Light Show Upper Brightness Parameter 1";
CM_ SG_ 447 DwnLoadDynLtgPrmForLedFrntTurnIndcrLeContTiPrm "Light Show Continue Time Parameter 1";
CM_ SG_ 447 DwnLoadDynLtgPrmForLedFrntTurnIndcrLeLowBriPrm "Light Show Lower Brightness Parameter 1";
CM_ SG_ 447 DwnLoadDynLtgPrmForLedFrntTurnIndcrLeModePrm "Light Show Mode Parameter 1";
CM_ SG_ 447 DwnLoadDynLtgPrmForLedFrntTurnIndcrLeOffsTiPrm "Light Show Offset Time Parameter 1";
CM_ SG_ 447 DwnLoadDynLtgPrmForLedFrntTurnIndcrLeTistamp "Light Show time stamp";
CM_ SG_ 447 DwnLoadDynLtgPrmForLedFrntTurnIndcrLeUpprBriPrm "Light Show Upper Brightness Parameter 1";
CM_ SG_ 451 DwnLoadDynLtgPrmForLedFrntTurnIndcrRiContTiPrm "Light Show Continue Time Parameter 1";
CM_ SG_ 451 DwnLoadDynLtgPrmForLedFrntTurnIndcrRiLowBriPrm "Light Show Lower Brightness Parameter 1";
CM_ SG_ 451 DwnLoadDynLtgPrmForLedFrntTurnIndcrRiModePrm "Light Show Mode Parameter 1";
CM_ SG_ 451 DwnLoadDynLtgPrmForLedFrntTurnIndcrRiOffsTiPrm "Light Show Offset Time Parameter 1";
CM_ SG_ 451 DwnLoadDynLtgPrmForLedFrntTurnIndcrRiTistamp "Light Show time stamp";
CM_ SG_ 451 DwnLoadDynLtgPrmForLedFrntTurnIndcrRiUpprBriPrm "Light Show Upper Brightness Parameter 1";
CM_ SG_ 455 DwnLoadDynLtgPrmForLedHiBeamRiContTiPrm "Light Show Continue Time Parameter 1";
CM_ SG_ 455 DwnLoadDynLtgPrmForLedHiBeamRiLowBriPrm "Light Show Lower Brightness Parameter 1";
CM_ SG_ 455 DwnLoadDynLtgPrmForLedHiBeamRiModePrm "Light Show Mode Parameter 1";
CM_ SG_ 455 DwnLoadDynLtgPrmForLedHiBeamRiOffsTiPrm "Light Show Offset Time Parameter 1";
CM_ SG_ 455 DwnLoadDynLtgPrmForLedHiBeamRiTistamp "Light Show time stamp";
CM_ SG_ 455 DwnLoadDynLtgPrmForLedHiBeamRiUpprBriPrm "Light Show Upper Brightness Parameter 1";
CM_ SG_ 377 ADataRawSafeALat "IMU acceleration data Lateral acceleration";
CM_ SG_ 377 ADataRawSafeALat1Qf "IMU acceleration data Quality factor for Lateral acceleration signal";
CM_ SG_ 377 ADataRawSafeALgt "IMU acceleration data Longitudinal acceleration";
CM_ SG_ 377 ADataRawSafeALgt1Qf "IMU acceleration data Quality factor for Longitudinal acceleration";
CM_ SG_ 377 ADataRawSafeAVert "IMU acceleration data Vertical acceleration";
CM_ SG_ 377 ADataRawSafeAVertQf "IMU acceleration data Quality factor for Vertical acceleration";
CM_ SG_ 377 ADataRawSafeChks "IMU acceleration data Check sum";
CM_ SG_ 377 ADataRawSafeCntr "IMU acceleration data Counter";
CM_ SG_ 381 ActnOfLedPosnLampDyn "Activation of Led Position Lamp Dynamic mode";
CM_ SG_ 381 AgDataRawSafeChks "IMU angular rate data. Check summa";
CM_ SG_ 381 AgDataRawSafeCntr "IMU angular rate data. Counter";
CM_ SG_ 381 AgDataRawSafeRollRate "IMU angular rate data. Roll Rate";
CM_ SG_ 381 AgDataRawSafeRollRateQf "IMU angular rate data. Quality factor for Roll Rate";
CM_ SG_ 381 AgDataRawSafeYawRate "IMU angular rate data. Yaw Rate";
CM_ SG_ 381 AgDataRawSafeYawRateQf "IMU angular rate data. Quality Factor for Yaw Rate";
CM_ SG_ 612 BrkPedlValBrkPedlVal "Position of the brake pedal. Physical lower limit: no pedal activation. Physical upper limit: full pedal stroke Brake pedal position";
CM_ SG_ 612 BrkPedlValQf "Position of the brake pedal. Physical lower limit: no pedal activation. Physical upper limit: full pedal stroke Brake pedal sensor quality factor";
CM_ SG_ 612 LitArea "Whether the host vehicle is in a lit area";
CM_ SG_ 612 WipgInfoWipgSpdInfo "Information regarding how the wipers are run";
CM_ SG_ 612 WipgInfoWiprActv " 0 No wiping, 1 Wiping";
CM_ SG_ 612 WipgInfoWiprInWipgAr " 0 Wiper in lower reversing area or parked, 1 Wiper in wiping area";
CM_ SG_ 476 DwnLoadDynLitPrmForLedMkrLampRi2ContTiPrm "Light Show Continue Time Parameter 1";
CM_ SG_ 476 DwnLoadDynLitPrmForLedMkrLampRi2LowBriPrm "Light Show Lower Brightness Parameter 1";
CM_ SG_ 476 DwnLoadDynLitPrmForLedMkrLampRi2ModePrm "Light Show Mode Parameter 1";
CM_ SG_ 476 DwnLoadDynLitPrmForLedMkrLampRi2OffsTiPrm "Light Show Offset Time Parameter 1";
CM_ SG_ 476 DwnLoadDynLitPrmForLedMkrLampRi2Tistamp "Light Show time stamp";
CM_ SG_ 476 DwnLoadDynLitPrmForLedMkrLampRi2UpprBriPrm "Light Show Upper Brightness Parameter 1";
CM_ SG_ 473 DwnLoadDynLitPrmLedRvsgLampRi2ContTiPrm "Light Show Continue Time Parameter 1";
CM_ SG_ 473 DwnLoadDynLitPrmLedRvsgLampRi2LowBriPrm "Light Show Lower Brightness Parameter 1";
CM_ SG_ 473 DwnLoadDynLitPrmLedRvsgLampRi2ModePrm "Light Show Mode Parameter 1";
CM_ SG_ 473 DwnLoadDynLitPrmLedRvsgLampRi2OffsTiPrm "Light Show Offset Time Parameter 1";
CM_ SG_ 473 DwnLoadDynLitPrmLedRvsgLampRi2Tistamp "Light Show time stamp";
CM_ SG_ 473 DwnLoadDynLitPrmLedRvsgLampRi2UpprBriPrm "Light Show Upper Brightness Parameter 1";
CM_ SG_ 522 ActnOfLedCornrgLampLe "Acitvation of Led Cornering Lamp Left";
CM_ SG_ 522 ActnOfLedCornrgLampRi "Activate LED Cornering Lamp Right.";
CM_ SG_ 522 ActnOfLedDaytiRunngLamp "Activate LED Daytime Running Lamp.";
CM_ SG_ 522 ActnOfLedFrntFogLamp "Activate LED Front Fog Lamp.";
CM_ SG_ 522 ActnOfLedHiBeam "Activate LED High Beam.";
CM_ SG_ 522 ActnOfLedLoBeamActnOfLedLoBeam "Activation of Low Beam function to HCM";
CM_ SG_ 522 ActnOfLedLoBeamChks "Low Beam Check Sum ASIL B";
CM_ SG_ 522 ActnOfLedLoBeamCntr "Low Beam Counter ASIL B";
CM_ SG_ 522 ActnOfLedPosnLamp "Activate LED Position Lamp.";
CM_ SG_ 522 ActnOfLedReFogLamp "Activate LED Rear Fog Lamp.";
CM_ SG_ 522 ActnOfLedRvsgLamp "Activate LED Revering Lamp.";
CM_ SG_ 522 ActnOfLedStopLampActnOfLedStopLamp "Activation of Stop Lamps by HCM";
CM_ SG_ 522 ActnOfLedStopLampChks "Stop Lamps Check Sum ASIL B";
CM_ SG_ 522 ActnOfLedStopLampCntr "Stop Lamps Counter ASIL B";
CM_ SG_ 522 ActvnOfAfs "Activation of Aaptive Frontlight System ";
CM_ SG_ 522 ActvnOfAhbc "Activate Auto High Beam Control.";
CM_ SG_ 522 ActvnOfAhl "Activate Auto Headlamp Leveling";
CM_ SG_ 522 ActvnOfBrkLi "Activation of Break Light";
CM_ SG_ 522 ActvnOfDbl "Activate Bending Light.";
CM_ SG_ 522 ActvnOfGoodByeLi "Activation Request for Goodbye Light";
CM_ SG_ 522 ActvnOfTouristMod "Activate Tourist Mode.";
CM_ SG_ 522 ActvnOfWelcomeLi "Activation Request for Welcome Light";
CM_ SG_ 538 ActvnOfIndcrIndcrOut "Direction indicator command";
CM_ SG_ 538 ActvnOfIndcrIndcrOutChks "CheckSum";
CM_ SG_ 538 ActvnOfIndcrIndcrOutCntr "Coounter";
CM_ SG_ 538 EmgyBrkLiIndcrTurn "Activation of both rear direction indicators for EBL.";
CM_ SG_ 538 IndcrPatCmd1WdTiOff "Used for Hazard Sleep (subfunction to Hazard Warning Light).

This signal holds the pattern of the flashing to use when buses are asleep and TRM/DCUs shall flash synchronized by themselves.

Holds both on and off timing in two separate record items. HWL Off time";
CM_ SG_ 538 IndcrPatCmd1WdTiOn "Used for Hazard Sleep (subfunction to Hazard Warning Light).

This signal holds the pattern of the flashing to use when buses are asleep and TRM/DCUs shall flash synchronized by themselves.

Holds both on and off timing in two separate record items. HWL On time";
CM_ SG_ 538 IndcrSts "Provides the state and not the event of HWL/Direction Indicator.";
CM_ SG_ 160 DwnLoadDynLitPrmForLedLogoLampContTiPrm "Light Show Continue Time Parameter 1";
CM_ SG_ 160 DwnLoadDynLitPrmForLedLogoLampLowBriPrm "Light Show Lower Brightness Parameter 1";
CM_ SG_ 160 DwnLoadDynLitPrmForLedLogoLampModePrm "Light Show Mode Parameter 1";
CM_ SG_ 160 DwnLoadDynLitPrmForLedLogoLampOffsTiPrm "Light Show Offset Time Parameter 1";
CM_ SG_ 160 DwnLoadDynLitPrmForLedLogoLampTistamp "Light Show time stamp";
CM_ SG_ 160 DwnLoadDynLitPrmForLedLogoLampUpprBriPrm "Light Show Upper Brightness Parameter 1";
CM_ SG_ 163 DwnLoadDynLitPrmLedRePosnLampLe3ContTiPrm "Light Show Offset Time Parameter 1";
CM_ SG_ 163 DwnLoadDynLitPrmLedRePosnLampLe3LowBriPrm "Light Show Lower Brightness Parameter 1";
CM_ SG_ 163 DwnLoadDynLitPrmLedRePosnLampLe3ModePrm "Light Show Mode Parameter 1";
CM_ SG_ 163 DwnLoadDynLitPrmLedRePosnLampLe3OffsTiPrm "Light Show Offset Time Parameter 1";
CM_ SG_ 163 DwnLoadDynLitPrmLedRePosnLampLe3Tistamp "Light Show time stamp";
CM_ SG_ 163 DwnLoadDynLitPrmLedRePosnLampLe3UpprBriPrm "Light Show Upper Brightness Parameter 1";
CM_ SG_ 166 DwnLoadDynLitPrmLedRePosnLampLe4ContTiPrm "Light Show Continue Time Parameter 1";
CM_ SG_ 166 DwnLoadDynLitPrmLedRePosnLampLe4LowBriPrm "Light Show Lower Brightness Parameter 1";
CM_ SG_ 166 DwnLoadDynLitPrmLedRePosnLampLe4ModePrm "Light Show Mode Parameter 1";
CM_ SG_ 166 DwnLoadDynLitPrmLedRePosnLampLe4OffsTiPrm "Light Show Offset Time Parameter 1";
CM_ SG_ 166 DwnLoadDynLitPrmLedRePosnLampLe4Tistamp "Light Show time stamp";
CM_ SG_ 166 DwnLoadDynLitPrmLedRePosnLampLe4UpprBriPrm "Light Show Upper Brightness Parameter 1";
CM_ SG_ 169 DwnLoadDynLitPrmLedRePosnLampLe5ContTiPrm "Light Show Continue Time Parameter 1";
CM_ SG_ 169 DwnLoadDynLitPrmLedRePosnLampLe5LowBriPrm "Light Show Lower Brightness Parameter 1";
CM_ SG_ 169 DwnLoadDynLitPrmLedRePosnLampLe5ModePrm "Light Show Mode Parameter 1";
CM_ SG_ 169 DwnLoadDynLitPrmLedRePosnLampLe5OffsTiPrm "Light Show Offset Time Parameter 1";
CM_ SG_ 169 DwnLoadDynLitPrmLedRePosnLampLe5Tistamp "Light Show time stamp";
CM_ SG_ 169 DwnLoadDynLitPrmLedRePosnLampLe5UpprBriPrm "Light Show Upper Brightness Parameter 1";
CM_ SG_ 172 DwnLoadDynLitPrmLedRePosnLampRi3ContTiPrm "Light Show Continue Time Parameter 1";
CM_ SG_ 172 DwnLoadDynLitPrmLedRePosnLampRi3LowBriPrm "Light Show Lower Brightness Parameter 1";
CM_ SG_ 172 DwnLoadDynLitPrmLedRePosnLampRi3ModePrm "Light Show Mode Parameter 1";
CM_ SG_ 172 DwnLoadDynLitPrmLedRePosnLampRi3OffsTiPrm "Light Show Offset Time Parameter 1";
CM_ SG_ 172 DwnLoadDynLitPrmLedRePosnLampRi3Tistamp "Light Show time stamp";
CM_ SG_ 172 DwnLoadDynLitPrmLedRePosnLampRi3UpprBriPrm "Light Show Upper Brightness Parameter 1";
CM_ SG_ 174 DwnLoadDynLitPrmLedRePosnLampRi4ContTiPrm "Light Show Continue Time Parameter 1";
CM_ SG_ 174 DwnLoadDynLitPrmLedRePosnLampRi4LowBriPrm "Light Show Lower Brightness Parameter 1";
CM_ SG_ 174 DwnLoadDynLitPrmLedRePosnLampRi4ModePrm "Light Show Mode Parameter 1";
CM_ SG_ 174 DwnLoadDynLitPrmLedRePosnLampRi4OffsTiPrm "Light Show Offset Time Parameter 1";
CM_ SG_ 174 DwnLoadDynLitPrmLedRePosnLampRi4Tistamp "Light Show time stamp";
CM_ SG_ 174 DwnLoadDynLitPrmLedRePosnLampRi4UpprBriPrm "Light Show Upper Brightness Parameter 1";
CM_ SG_ 175 DwnLoadDynLitPrmLedRePosnLampRi5ContTiPrm "Light Show Continue Time Parameter 1";
CM_ SG_ 175 DwnLoadDynLitPrmLedRePosnLampRi5LowBriPrm "Light Show Lower Brightness Parameter 1";
CM_ SG_ 175 DwnLoadDynLitPrmLedRePosnLampRi5ModePrm "Light Show Mode Parameter 1";
CM_ SG_ 175 DwnLoadDynLitPrmLedRePosnLampRi5OffsTiPrm "Light Show Offset Time Parameter 1";
CM_ SG_ 175 DwnLoadDynLitPrmLedRePosnLampRi5Tistamp "Light Show time stamp";
CM_ SG_ 175 DwnLoadDynLitPrmLedRePosnLampRi5UpprBriPrm "Light Show Upper Brightness Parameter 1";
CM_ SG_ 1425 CEMdevelpsignalgroupreqFunctiondevpsignalgroup1 "develop signal group request";
CM_ SG_ 1425 CEMdevelpsignalgroupreqFunctiondevpsignalgroup2 "develop signal group request";
CM_ SG_ 1425 CEMdevelpsignalgroupreqFunctiondevpsignalgroup3 "develop signal group request";
CM_ SG_ 1425 CEMdevelpsignalgroupreqFunctiondevpsignalgroup4 "develop signal group request";
CM_ SG_ 1425 CEMdevelpsignalgroupreqFunctiondevpsignalgroup5 "develop signal group request";
CM_ SG_ 1425 CEMdevelpsignalgroupreqFunctiondevpsignalgroup6 "develop signal group request";
CM_ SG_ 1425 CEMdevelpsignalgroupreqFunctiondevpsignalgroup7 "develop signal group request";
CM_ SG_ 1425 CEMdevelpsignalgroupreqFunctiondevpsignalgroup8 "develop signal group request";
CM_ SG_ 593 StsOfLedHiBeamLe "Status of Led High Beam Left.";
CM_ SG_ 593 StsOfLedLoBeamLe "Status of Led Low Beam Left.";
CM_ SG_ 124 DwnLoadStsFbOfHdlampLe "Download of Dynamic light sequence Feedback signal.";
CM_ SG_ 124 ExtrLiShowActvnFrntLeFb "Activation of Exterior Light Show Feedback Frong Left Head Lamp";
CM_ SG_ 124 HdlampLeInpSts1 "Ext. Light relay input driver warning and fault tracing";
CM_ SG_ 124 HdlampLeInpSts2 "Ignition relay input driver warning and fault tracing";
CM_ SG_ 124 StsOfAfsLe "Status of AFS light distribution Left.";
CM_ SG_ 124 StsOfAhbcLe "Status of Auto High Beam Control Left.";
CM_ SG_ 124 StsOfFrntSideMkrLampLe2 "Status of Front Side Marker Lamp Left 2.";
CM_ SG_ 124 StsOfLedCornrgLampLe "Status of Led Cornering Lamp Left.";
CM_ SG_ 124 StsOfLedDaytiRunngLampLe "Status of Led Day Time Running Lamp Left.";
CM_ SG_ 124 StsOfLedFrntFogLampLe "Status of Led Front Fog Light Left.";
CM_ SG_ 124 StsOfLedFrntPosnLampLe "Status of Led Front Position Lamp Left.";
CM_ SG_ 124 StsOfLedFrntTurnIndcrLe "Status of Led Front Turn Indicator Left.";
CM_ SG_ 124 StsOfLvlgLeChks "Status of Head Lamp Leveling Motor Check Sum";
CM_ SG_ 124 StsOfLvlgLeCntr "Status of Head Lamp Leveling Motor Counter";
CM_ SG_ 124 StsOfLvlgLeStsOfLvlgLe "Status of Head Lamp Leveling Motor";
CM_ SG_ 124 StsOfSwvlgLe "Status of Bending Light Left.";
CM_ SG_ 124 StsOfTouristModLe "Status of Tourist Mode Left.";
CM_ SG_ 594 StsOfLedHiBeamRi "Status of High Beam Led Right.";
CM_ SG_ 594 StsOfLedLoBeamRi "Status of Low Beam Led Right";
CM_ SG_ 127 DwnLoadStsFbOfHdlampRi "Download of Dynamic light sequence Feedback signal.";
CM_ SG_ 127 ExtrLiShowActvnFrntRiFb "Activation of Exterior Light Show Feedback Frong Right Head Lamp";
CM_ SG_ 127 HdlampRiInpSts1 "Ext. Light relay input driver warning and fault tracing";
CM_ SG_ 127 HdlampRiInpSts2 "Ignition relay input driver warning and fault tracing";
CM_ SG_ 127 StsOfAfsRi "Status of AFS light distribution Right.";
CM_ SG_ 127 StsOfAhbcRi "Status of Auto High Beam Control Right.";
CM_ SG_ 127 StsOfFrntSideMkrLampRi2 "Status of Front Side Marker Lamp Right 2.";
CM_ SG_ 127 StsOfLedCornrgLampRi "Status of Led Cornering Lamp Right.";
CM_ SG_ 127 StsOfLedDaytiRunngLampRi "Status of Led Day Time Running Lamp Right.";
CM_ SG_ 127 StsOfLedFrntFogLampRi "Status of Led Front Fog Lamp Right.";
CM_ SG_ 127 StsOfLedFrntPosnLampRi "Status of Led Front Position Lamp Right.";
CM_ SG_ 127 StsOfLedFrntTurnIndcrRi "Status of Front Turn Right Indicator";
CM_ SG_ 127 StsOfLvlgRiChks "Status of Head Lamp Leveling Motor Check Sum";
CM_ SG_ 127 StsOfLvlgRiCntr "Status of Head Lamp Leveling Motor Counter";
CM_ SG_ 127 StsOfLvlgRiStsOfLvlgRi "Status of Head Lamp Leveling Motor";
CM_ SG_ 127 StsOfSwvlgRi "Status of Bending Light Right.";
CM_ SG_ 127 StsOfTouristModRi "Status of Tourist Mode Right.";
BA_DEF_ BO_ "GenMsgSendType" ENUM "cyclic", "spontaneous", "not-used", "not-used", "not-used", "cyclicAndSpontaneous", "not-used", "cyclicIfActive", "NoMsgSendType"; // [us]
BA_DEF_ BO_ "GenMsgCycleTime" INT 0 65536; // [ms]
BA_DEF_ BO_ "GenMsgStartDelayTime" INT 0 65536; // [ms]
BA_DEF_ BO_ "GenMsgDelayTime" INT 0 65536; // [ms]
BA_DEF_ SG_ "GenSigSendType" ENUM "Cyclic","OnWrite","OnWriteWithRepetition","OnChange","OnChangeWithRepetition","IfActive","IfActiveWithRepetition","NoSigSendType";
BA_DEF_ SG_ "GenSigStartValue" HEX 0 80000000;
BA_DEF_ BO_ "GenMsgILSupport" ENUM "No","Yes";
BA_DEF_ BO_ "NmAsrMessage" ENUM "No","Yes";
BA_DEF_ SG_ "GenSigFuncType" ENUM "NoFunction","n/a","n/a","n/a","n/a","n/a","n/a","n/a","n/a","n/a","n/a","n/a","n/a","n/a","n/a","CHK","CNTR","n/a","n/a","n/a","CNTR_AR_01","CRC_AR_01_BOTH","CRC_AR_01_ALT","CRC_AR_01_LOW","CRC_AR_01_NIBBLE","CNTR_AR_04","CRC_AR_04A","CNTR_AR_05","CRC_AR_05";
BA_DEF_ SG_ "GenSigDataID" STRING;
BA_DEF_ SG_ "SigGroup" STRING;

BA_DEF_DEF_ "GenSigStartValue" 0;
BA_DEF_DEF_ "GenSigSendType" "NoSigSendType";
BA_DEF_DEF_ "GenMsgCycleTime" 0;
BA_DEF_DEF_ "GenMsgDelayTime" 0;
BA_DEF_DEF_ "GenMsgStartDelayTime" 0;
BA_DEF_DEF_ "GenMsgSendType" "NoMsgSendType";
BA_DEF_DEF_ "GenMsgILSupport" "Yes";
BA_DEF_DEF_ "NmAsrMessage" "No";
BA_DEF_DEF_ "GenSigFuncType" "NoFunction";
BA_DEF_DEF_ "GenSigDataID" "";
BA_DEF_DEF_ "SigGroup" "";
// Frame: CemBodyExpoFr21
BA_ "GenMsgSendType" BO_ 99 1;
BA_ "GenMsgDelayTime" BO_ 99 70.000;
BA_ "GenSigSendType" SG_ 99 DwnLoadDynLitPrmLedReTurnIndcrRi1ContTiPrm 1;
BA_ "SigGroup" SG_ 99 DwnLoadDynLitPrmLedReTurnIndcrRi1ContTiPrm "DwnLoadDynLitPrmLedReTurnIndcrRi1";
BA_ "GenSigSendType" SG_ 99 DwnLoadDynLitPrmLedReTurnIndcrRi1LowBriPrm 1;
BA_ "SigGroup" SG_ 99 DwnLoadDynLitPrmLedReTurnIndcrRi1LowBriPrm "DwnLoadDynLitPrmLedReTurnIndcrRi1";
BA_ "GenSigSendType" SG_ 99 DwnLoadDynLitPrmLedReTurnIndcrRi1ModePrm 1;
BA_ "SigGroup" SG_ 99 DwnLoadDynLitPrmLedReTurnIndcrRi1ModePrm "DwnLoadDynLitPrmLedReTurnIndcrRi1";
BA_ "GenSigSendType" SG_ 99 DwnLoadDynLitPrmLedReTurnIndcrRi1OffsTiPrm 1;
BA_ "SigGroup" SG_ 99 DwnLoadDynLitPrmLedReTurnIndcrRi1OffsTiPrm "DwnLoadDynLitPrmLedReTurnIndcrRi1";
BA_ "GenSigSendType" SG_ 99 DwnLoadDynLitPrmLedReTurnIndcrRi1Tistamp 1;
BA_ "SigGroup" SG_ 99 DwnLoadDynLitPrmLedReTurnIndcrRi1Tistamp "DwnLoadDynLitPrmLedReTurnIndcrRi1";
BA_ "GenSigSendType" SG_ 99 DwnLoadDynLitPrmLedReTurnIndcrRi1UpprBriPrm 1;
BA_ "SigGroup" SG_ 99 DwnLoadDynLitPrmLedReTurnIndcrRi1UpprBriPrm "DwnLoadDynLitPrmLedReTurnIndcrRi1";
// Frame: CemBodyExpoFr22
BA_ "GenMsgSendType" BO_ 103 1;
BA_ "GenMsgDelayTime" BO_ 103 70.000;
BA_ "GenSigSendType" SG_ 103 DwnLoadDynLitPrmLedRvsgLampLe1ContTiPrm 1;
BA_ "GenSigSendType" SG_ 103 DwnLoadDynLitPrmLedRvsgLampLe1LowBriPrm 1;
BA_ "GenSigSendType" SG_ 103 DwnLoadDynLitPrmLedRvsgLampLe1ModePrm 1;
BA_ "GenSigSendType" SG_ 103 DwnLoadDynLitPrmLedRvsgLampLe1OffsTiPrm 1;
BA_ "GenSigSendType" SG_ 103 DwnLoadDynLitPrmLedRvsgLampLe1Tistamp 1;
BA_ "GenSigSendType" SG_ 103 DwnLoadDynLitPrmLedRvsgLampLe1UpprBriPrm 1;
// Frame: CemBodyExpoFr23
BA_ "GenMsgSendType" BO_ 107 1;
BA_ "GenMsgDelayTime" BO_ 107 70.000;
BA_ "GenSigSendType" SG_ 107 DwnLoadDynLitPrmLedRvsgLampLe2ContTiPrm 1;
BA_ "GenSigSendType" SG_ 107 DwnLoadDynLitPrmLedRvsgLampLe2LowBriPrm 1;
BA_ "GenSigSendType" SG_ 107 DwnLoadDynLitPrmLedRvsgLampLe2ModePrm 1;
BA_ "GenSigSendType" SG_ 107 DwnLoadDynLitPrmLedRvsgLampLe2OffsTiPrm 1;
BA_ "GenSigSendType" SG_ 107 DwnLoadDynLitPrmLedRvsgLampLe2Tistamp 1;
BA_ "GenSigSendType" SG_ 107 DwnLoadDynLitPrmLedRvsgLampLe2UpprBriPrm 1;
// Frame: CemBodyExpoFr24
BA_ "GenMsgSendType" BO_ 111 1;
BA_ "GenMsgDelayTime" BO_ 111 70.000;
BA_ "GenSigSendType" SG_ 111 DwnLoadDynLitPrmLedRvsgLampRi1ContTiPrm 1;
BA_ "GenSigSendType" SG_ 111 DwnLoadDynLitPrmLedRvsgLampRi1LowBriPrm 1;
BA_ "GenSigSendType" SG_ 111 DwnLoadDynLitPrmLedRvsgLampRi1ModePrm 1;
BA_ "GenSigSendType" SG_ 111 DwnLoadDynLitPrmLedRvsgLampRi1OffsTiPrm 1;
BA_ "GenSigSendType" SG_ 111 DwnLoadDynLitPrmLedRvsgLampRi1Tistamp 1;
BA_ "GenSigSendType" SG_ 111 DwnLoadDynLitPrmLedRvsgLampRi1UpprBriPrm 1;
// Frame: CemBodyExpoFr25
BA_ "GenMsgSendType" BO_ 120 0;
BA_ "GenMsgCycleTime" BO_ 120 25.000;
BA_ "GenSigSendType" SG_ 120 LvlgSwtSetReqADModCtrlInhbn 0;
BA_ "GenSigSendType" SG_ 120 LvlgSwtSetReqChks 0;
BA_ "GenSigSendType" SG_ 120 LvlgSwtSetReqCntr 0;
BA_ "GenSigSendType" SG_ 120 OutdBriChks 0;
BA_ "GenSigFuncType" SG_ 120 OutdBriChks 15;
BA_ "GenSigDataID" SG_ 120 OutdBriChks "0x1F42";
BA_ "GenSigSendType" SG_ 120 OutdBriCntr 0;
BA_ "GenSigFuncType" SG_ 120 OutdBriCntr 16;
BA_ "GenSigSendType" SG_ 120 OutdBriSts 0;
// Frame: CemBodyExpoFr26
BA_ "GenMsgSendType" BO_ 407 1;
BA_ "GenMsgDelayTime" BO_ 407 70.000;
BA_ "GenSigSendType" SG_ 407 DwnLoadDynLitPrmForLedHiBeamLeContTiPrm 1;
BA_ "GenSigSendType" SG_ 407 DwnLoadDynLitPrmForLedHiBeamLeLowBriPrm 1;
BA_ "GenSigSendType" SG_ 407 DwnLoadDynLitPrmForLedHiBeamLeModePrm 1;
BA_ "GenSigSendType" SG_ 407 DwnLoadDynLitPrmForLedHiBeamLeOffsTiPrm 1;
BA_ "GenSigSendType" SG_ 407 DwnLoadDynLitPrmForLedHiBeamLeTistamp 1;
BA_ "GenSigSendType" SG_ 407 DwnLoadDynLitPrmForLedHiBeamLeUpprBriPrm 1;
// Frame: CemBodyExpoFr27
BA_ "GenMsgSendType" BO_ 412 1;
BA_ "GenMsgDelayTime" BO_ 412 70.000;
BA_ "GenSigSendType" SG_ 412 DwnLoadDynLitPrmForLedLoBeamLeContTiPrm 1;
BA_ "GenSigSendType" SG_ 412 DwnLoadDynLitPrmForLedLoBeamLeLowBriPrm 1;
BA_ "GenSigSendType" SG_ 412 DwnLoadDynLitPrmForLedLoBeamLeModePrm 1;
BA_ "GenSigSendType" SG_ 412 DwnLoadDynLitPrmForLedLoBeamLeOffsTiPrm 1;
BA_ "GenSigSendType" SG_ 412 DwnLoadDynLitPrmForLedLoBeamLeTistamp 1;
BA_ "GenSigSendType" SG_ 412 DwnLoadDynLitPrmForLedLoBeamLeUpprBriPrm 1;
// Frame: CemBodyExpoFr28
BA_ "GenMsgSendType" BO_ 415 1;
BA_ "GenMsgDelayTime" BO_ 415 70.000;
BA_ "GenSigSendType" SG_ 415 DwnLoadDynLtgPrmForLedAllWthrLampLeContTiPrm 1;
BA_ "SigGroup" SG_ 415 DwnLoadDynLtgPrmForLedAllWthrLampLeContTiPrm "DwnLoadDynLtgPrmForLedAllWthrLampLe";
BA_ "GenSigSendType" SG_ 415 DwnLoadDynLtgPrmForLedAllWthrLampLeLowBriPrm 1;
BA_ "SigGroup" SG_ 415 DwnLoadDynLtgPrmForLedAllWthrLampLeLowBriPrm "DwnLoadDynLtgPrmForLedAllWthrLampLe";
BA_ "GenSigSendType" SG_ 415 DwnLoadDynLtgPrmForLedAllWthrLampLeModePrm 1;
BA_ "SigGroup" SG_ 415 DwnLoadDynLtgPrmForLedAllWthrLampLeModePrm "DwnLoadDynLtgPrmForLedAllWthrLampLe";
BA_ "GenSigSendType" SG_ 415 DwnLoadDynLtgPrmForLedAllWthrLampLeOffsTiPrm 1;
BA_ "SigGroup" SG_ 415 DwnLoadDynLtgPrmForLedAllWthrLampLeOffsTiPrm "DwnLoadDynLtgPrmForLedAllWthrLampLe";
BA_ "GenSigSendType" SG_ 415 DwnLoadDynLtgPrmForLedAllWthrLampLeTistamp 1;
BA_ "SigGroup" SG_ 415 DwnLoadDynLtgPrmForLedAllWthrLampLeTistamp "DwnLoadDynLtgPrmForLedAllWthrLampLe";
BA_ "GenSigSendType" SG_ 415 DwnLoadDynLtgPrmForLedAllWthrLampLeUpprBriPrm 1;
BA_ "SigGroup" SG_ 415 DwnLoadDynLtgPrmForLedAllWthrLampLeUpprBriPrm "DwnLoadDynLtgPrmForLedAllWthrLampLe";
// Frame: CemBodyExpoFr29
BA_ "GenMsgSendType" BO_ 419 1;
BA_ "GenMsgDelayTime" BO_ 419 70.000;
BA_ "GenSigSendType" SG_ 419 DwnLoadDynLtgPrmForLedAllWthrLampRiContTiPrm 1;
BA_ "SigGroup" SG_ 419 DwnLoadDynLtgPrmForLedAllWthrLampRiContTiPrm "DwnLoadDynLtgPrmForLedAllWthrLampRi";
BA_ "GenSigSendType" SG_ 419 DwnLoadDynLtgPrmForLedAllWthrLampRiLowBriPrm 1;
BA_ "SigGroup" SG_ 419 DwnLoadDynLtgPrmForLedAllWthrLampRiLowBriPrm "DwnLoadDynLtgPrmForLedAllWthrLampRi";
BA_ "GenSigSendType" SG_ 419 DwnLoadDynLtgPrmForLedAllWthrLampRiModePrm 1;
BA_ "SigGroup" SG_ 419 DwnLoadDynLtgPrmForLedAllWthrLampRiModePrm "DwnLoadDynLtgPrmForLedAllWthrLampRi";
BA_ "GenSigSendType" SG_ 419 DwnLoadDynLtgPrmForLedAllWthrLampRiOffsTiPrm 1;
BA_ "SigGroup" SG_ 419 DwnLoadDynLtgPrmForLedAllWthrLampRiOffsTiPrm "DwnLoadDynLtgPrmForLedAllWthrLampRi";
BA_ "GenSigSendType" SG_ 419 DwnLoadDynLtgPrmForLedAllWthrLampRiTistamp 1;
BA_ "SigGroup" SG_ 419 DwnLoadDynLtgPrmForLedAllWthrLampRiTistamp "DwnLoadDynLtgPrmForLedAllWthrLampRi";
BA_ "GenSigSendType" SG_ 419 DwnLoadDynLtgPrmForLedAllWthrLampRiUpprBriPrm 1;
BA_ "SigGroup" SG_ 419 DwnLoadDynLtgPrmForLedAllWthrLampRiUpprBriPrm "DwnLoadDynLtgPrmForLedAllWthrLampRi";
// Frame: CemBodyExpoFr30
BA_ "GenMsgSendType" BO_ 423 1;
BA_ "GenMsgDelayTime" BO_ 423 70.000;
BA_ "GenSigSendType" SG_ 423 DwnLoadDynLtgPrmForLedCornrgLampLeContTiPrm 1;
BA_ "SigGroup" SG_ 423 DwnLoadDynLtgPrmForLedCornrgLampLeContTiPrm "DwnLoadDynLtgPrmForLedCornrgLampLe";
BA_ "GenSigSendType" SG_ 423 DwnLoadDynLtgPrmForLedCornrgLampLeLowBriPrm 1;
BA_ "SigGroup" SG_ 423 DwnLoadDynLtgPrmForLedCornrgLampLeLowBriPrm "DwnLoadDynLtgPrmForLedCornrgLampLe";
BA_ "GenSigSendType" SG_ 423 DwnLoadDynLtgPrmForLedCornrgLampLeModePrm 1;
BA_ "SigGroup" SG_ 423 DwnLoadDynLtgPrmForLedCornrgLampLeModePrm "DwnLoadDynLtgPrmForLedCornrgLampLe";
BA_ "GenSigSendType" SG_ 423 DwnLoadDynLtgPrmForLedCornrgLampLeOffsTiPrm 1;
BA_ "SigGroup" SG_ 423 DwnLoadDynLtgPrmForLedCornrgLampLeOffsTiPrm "DwnLoadDynLtgPrmForLedCornrgLampLe";
BA_ "GenSigSendType" SG_ 423 DwnLoadDynLtgPrmForLedCornrgLampLeTistamp 1;
BA_ "SigGroup" SG_ 423 DwnLoadDynLtgPrmForLedCornrgLampLeTistamp "DwnLoadDynLtgPrmForLedCornrgLampLe";
BA_ "GenSigSendType" SG_ 423 DwnLoadDynLtgPrmForLedCornrgLampLeUpprBriPrm 1;
BA_ "SigGroup" SG_ 423 DwnLoadDynLtgPrmForLedCornrgLampLeUpprBriPrm "DwnLoadDynLtgPrmForLedCornrgLampLe";
// Frame: CemBodyExpoFr31
BA_ "GenMsgSendType" BO_ 427 1;
BA_ "GenMsgDelayTime" BO_ 427 70.000;
BA_ "GenSigSendType" SG_ 427 DwnLoadDynLtgPrmForLedCornrgLampRiContTiPrm 1;
BA_ "SigGroup" SG_ 427 DwnLoadDynLtgPrmForLedCornrgLampRiContTiPrm "DwnLoadDynLtgPrmForLedCornrgLampRi";
BA_ "GenSigSendType" SG_ 427 DwnLoadDynLtgPrmForLedCornrgLampRiLowBriPrm 1;
BA_ "SigGroup" SG_ 427 DwnLoadDynLtgPrmForLedCornrgLampRiLowBriPrm "DwnLoadDynLtgPrmForLedCornrgLampRi";
BA_ "GenSigSendType" SG_ 427 DwnLoadDynLtgPrmForLedCornrgLampRiModePrm 1;
BA_ "SigGroup" SG_ 427 DwnLoadDynLtgPrmForLedCornrgLampRiModePrm "DwnLoadDynLtgPrmForLedCornrgLampRi";
BA_ "GenSigSendType" SG_ 427 DwnLoadDynLtgPrmForLedCornrgLampRiOffsTiPrm 1;
BA_ "SigGroup" SG_ 427 DwnLoadDynLtgPrmForLedCornrgLampRiOffsTiPrm "DwnLoadDynLtgPrmForLedCornrgLampRi";
BA_ "GenSigSendType" SG_ 427 DwnLoadDynLtgPrmForLedCornrgLampRiTistamp 1;
BA_ "SigGroup" SG_ 427 DwnLoadDynLtgPrmForLedCornrgLampRiTistamp "DwnLoadDynLtgPrmForLedCornrgLampRi";
BA_ "GenSigSendType" SG_ 427 DwnLoadDynLtgPrmForLedCornrgLampRiUpprBriPrm 1;
BA_ "SigGroup" SG_ 427 DwnLoadDynLtgPrmForLedCornrgLampRiUpprBriPrm "DwnLoadDynLtgPrmForLedCornrgLampRi";
// Frame: CemBodyExpoFr32
BA_ "GenMsgSendType" BO_ 430 1;
BA_ "GenMsgDelayTime" BO_ 430 70.000;
BA_ "GenSigSendType" SG_ 430 DwnLoadDynLtgPrmForLedDaytiRunngLampLeContTiPrm 1;
BA_ "SigGroup" SG_ 430 DwnLoadDynLtgPrmForLedDaytiRunngLampLeContTiPrm "DwnLoadDynLtgPrmForLedDaytiRunngLampLe";
BA_ "GenSigSendType" SG_ 430 DwnLoadDynLtgPrmForLedDaytiRunngLampLeLowBriPrm 1;
BA_ "SigGroup" SG_ 430 DwnLoadDynLtgPrmForLedDaytiRunngLampLeLowBriPrm "DwnLoadDynLtgPrmForLedDaytiRunngLampLe";
BA_ "GenSigSendType" SG_ 430 DwnLoadDynLtgPrmForLedDaytiRunngLampLeModePrm 1;
BA_ "SigGroup" SG_ 430 DwnLoadDynLtgPrmForLedDaytiRunngLampLeModePrm "DwnLoadDynLtgPrmForLedDaytiRunngLampLe";
BA_ "GenSigSendType" SG_ 430 DwnLoadDynLtgPrmForLedDaytiRunngLampLeOffsTiPrm 1;
BA_ "SigGroup" SG_ 430 DwnLoadDynLtgPrmForLedDaytiRunngLampLeOffsTiPrm "DwnLoadDynLtgPrmForLedDaytiRunngLampLe";
BA_ "GenSigSendType" SG_ 430 DwnLoadDynLtgPrmForLedDaytiRunngLampLeTistamp 1;
BA_ "SigGroup" SG_ 430 DwnLoadDynLtgPrmForLedDaytiRunngLampLeTistamp "DwnLoadDynLtgPrmForLedDaytiRunngLampLe";
BA_ "GenSigSendType" SG_ 430 DwnLoadDynLtgPrmForLedDaytiRunngLampLeUpprBriPrm 1;
BA_ "SigGroup" SG_ 430 DwnLoadDynLtgPrmForLedDaytiRunngLampLeUpprBriPrm "DwnLoadDynLtgPrmForLedDaytiRunngLampLe";
// Frame: CemBodyExpoFr33
BA_ "GenMsgSendType" BO_ 436 1;
BA_ "GenMsgDelayTime" BO_ 436 70.000;
BA_ "GenSigSendType" SG_ 436 DwnLoadDynLtgPrmForLedDaytiRunngLampRiContTiPrm 1;
BA_ "SigGroup" SG_ 436 DwnLoadDynLtgPrmForLedDaytiRunngLampRiContTiPrm "DwnLoadDynLtgPrmForLedDaytiRunngLampRi";
BA_ "GenSigSendType" SG_ 436 DwnLoadDynLtgPrmForLedDaytiRunngLampRiLowBriPrm 1;
BA_ "SigGroup" SG_ 436 DwnLoadDynLtgPrmForLedDaytiRunngLampRiLowBriPrm "DwnLoadDynLtgPrmForLedDaytiRunngLampRi";
BA_ "GenSigSendType" SG_ 436 DwnLoadDynLtgPrmForLedDaytiRunngLampRiModePrm 1;
BA_ "SigGroup" SG_ 436 DwnLoadDynLtgPrmForLedDaytiRunngLampRiModePrm "DwnLoadDynLtgPrmForLedDaytiRunngLampRi";
BA_ "GenSigSendType" SG_ 436 DwnLoadDynLtgPrmForLedDaytiRunngLampRiOffsTiPrm 1;
BA_ "SigGroup" SG_ 436 DwnLoadDynLtgPrmForLedDaytiRunngLampRiOffsTiPrm "DwnLoadDynLtgPrmForLedDaytiRunngLampRi";
BA_ "GenSigSendType" SG_ 436 DwnLoadDynLtgPrmForLedDaytiRunngLampRiTistamp 1;
BA_ "SigGroup" SG_ 436 DwnLoadDynLtgPrmForLedDaytiRunngLampRiTistamp "DwnLoadDynLtgPrmForLedDaytiRunngLampRi";
BA_ "GenSigSendType" SG_ 436 DwnLoadDynLtgPrmForLedDaytiRunngLampRiUpprBriPrm 1;
BA_ "SigGroup" SG_ 436 DwnLoadDynLtgPrmForLedDaytiRunngLampRiUpprBriPrm "DwnLoadDynLtgPrmForLedDaytiRunngLampRi";
// Frame: CemBodyExpoFr34
BA_ "GenMsgSendType" BO_ 440 1;
BA_ "GenMsgDelayTime" BO_ 440 70.000;
BA_ "GenSigSendType" SG_ 440 DwnLoadDynLtgPrmForLedFrntPosnLampLeContTiPrm 1;
BA_ "SigGroup" SG_ 440 DwnLoadDynLtgPrmForLedFrntPosnLampLeContTiPrm "DwnLoadDynLtgPrmForLedFrntPosnLampLe";
BA_ "GenSigSendType" SG_ 440 DwnLoadDynLtgPrmForLedFrntPosnLampLeLowBriPrm 1;
BA_ "SigGroup" SG_ 440 DwnLoadDynLtgPrmForLedFrntPosnLampLeLowBriPrm "DwnLoadDynLtgPrmForLedFrntPosnLampLe";
BA_ "GenSigSendType" SG_ 440 DwnLoadDynLtgPrmForLedFrntPosnLampLeModePrm 1;
BA_ "SigGroup" SG_ 440 DwnLoadDynLtgPrmForLedFrntPosnLampLeModePrm "DwnLoadDynLtgPrmForLedFrntPosnLampLe";
BA_ "GenSigSendType" SG_ 440 DwnLoadDynLtgPrmForLedFrntPosnLampLeOffsTiPrm 1;
BA_ "SigGroup" SG_ 440 DwnLoadDynLtgPrmForLedFrntPosnLampLeOffsTiPrm "DwnLoadDynLtgPrmForLedFrntPosnLampLe";
BA_ "GenSigSendType" SG_ 440 DwnLoadDynLtgPrmForLedFrntPosnLampLeTistamp 1;
BA_ "SigGroup" SG_ 440 DwnLoadDynLtgPrmForLedFrntPosnLampLeTistamp "DwnLoadDynLtgPrmForLedFrntPosnLampLe";
BA_ "GenSigSendType" SG_ 440 DwnLoadDynLtgPrmForLedFrntPosnLampLeUpprBriPrm 1;
BA_ "SigGroup" SG_ 440 DwnLoadDynLtgPrmForLedFrntPosnLampLeUpprBriPrm "DwnLoadDynLtgPrmForLedFrntPosnLampLe";
// Frame: CemBodyExpoFr35
BA_ "GenMsgSendType" BO_ 444 1;
BA_ "GenMsgDelayTime" BO_ 444 70.000;
BA_ "GenSigSendType" SG_ 444 DwnLoadDynLtgPrmForLedFrntPosnLampRiContTiPrm 1;
BA_ "SigGroup" SG_ 444 DwnLoadDynLtgPrmForLedFrntPosnLampRiContTiPrm "DwnLoadDynLtgPrmForLedFrntPosnLampRi";
BA_ "GenSigSendType" SG_ 444 DwnLoadDynLtgPrmForLedFrntPosnLampRiLowBriPrm 1;
BA_ "SigGroup" SG_ 444 DwnLoadDynLtgPrmForLedFrntPosnLampRiLowBriPrm "DwnLoadDynLtgPrmForLedFrntPosnLampRi";
BA_ "GenSigSendType" SG_ 444 DwnLoadDynLtgPrmForLedFrntPosnLampRiModePrm 1;
BA_ "SigGroup" SG_ 444 DwnLoadDynLtgPrmForLedFrntPosnLampRiModePrm "DwnLoadDynLtgPrmForLedFrntPosnLampRi";
BA_ "GenSigSendType" SG_ 444 DwnLoadDynLtgPrmForLedFrntPosnLampRiOffsTiPrm 1;
BA_ "SigGroup" SG_ 444 DwnLoadDynLtgPrmForLedFrntPosnLampRiOffsTiPrm "DwnLoadDynLtgPrmForLedFrntPosnLampRi";
BA_ "GenSigSendType" SG_ 444 DwnLoadDynLtgPrmForLedFrntPosnLampRiTistamp 1;
BA_ "SigGroup" SG_ 444 DwnLoadDynLtgPrmForLedFrntPosnLampRiTistamp "DwnLoadDynLtgPrmForLedFrntPosnLampRi";
BA_ "GenSigSendType" SG_ 444 DwnLoadDynLtgPrmForLedFrntPosnLampRiUpprBriPrm 1;
BA_ "SigGroup" SG_ 444 DwnLoadDynLtgPrmForLedFrntPosnLampRiUpprBriPrm "DwnLoadDynLtgPrmForLedFrntPosnLampRi";
// Frame: CemBodyExpoFr36
BA_ "GenMsgSendType" BO_ 447 1;
BA_ "GenMsgDelayTime" BO_ 447 70.000;
BA_ "GenSigSendType" SG_ 447 DwnLoadDynLtgPrmForLedFrntTurnIndcrLeContTiPrm 1;
BA_ "SigGroup" SG_ 447 DwnLoadDynLtgPrmForLedFrntTurnIndcrLeContTiPrm "DwnLoadDynLtgPrmForLedFrntTurnIndcrLe";
BA_ "GenSigSendType" SG_ 447 DwnLoadDynLtgPrmForLedFrntTurnIndcrLeLowBriPrm 1;
BA_ "SigGroup" SG_ 447 DwnLoadDynLtgPrmForLedFrntTurnIndcrLeLowBriPrm "DwnLoadDynLtgPrmForLedFrntTurnIndcrLe";
BA_ "GenSigSendType" SG_ 447 DwnLoadDynLtgPrmForLedFrntTurnIndcrLeModePrm 1;
BA_ "SigGroup" SG_ 447 DwnLoadDynLtgPrmForLedFrntTurnIndcrLeModePrm "DwnLoadDynLtgPrmForLedFrntTurnIndcrLe";
BA_ "GenSigSendType" SG_ 447 DwnLoadDynLtgPrmForLedFrntTurnIndcrLeOffsTiPrm 1;
BA_ "SigGroup" SG_ 447 DwnLoadDynLtgPrmForLedFrntTurnIndcrLeOffsTiPrm "DwnLoadDynLtgPrmForLedFrntTurnIndcrLe";
BA_ "GenSigSendType" SG_ 447 DwnLoadDynLtgPrmForLedFrntTurnIndcrLeTistamp 1;
BA_ "SigGroup" SG_ 447 DwnLoadDynLtgPrmForLedFrntTurnIndcrLeTistamp "DwnLoadDynLtgPrmForLedFrntTurnIndcrLe";
BA_ "GenSigSendType" SG_ 447 DwnLoadDynLtgPrmForLedFrntTurnIndcrLeUpprBriPrm 1;
BA_ "SigGroup" SG_ 447 DwnLoadDynLtgPrmForLedFrntTurnIndcrLeUpprBriPrm "DwnLoadDynLtgPrmForLedFrntTurnIndcrLe";
// Frame: CemBodyExpoFr37
BA_ "GenMsgSendType" BO_ 451 1;
BA_ "GenMsgDelayTime" BO_ 451 70.000;
BA_ "GenSigSendType" SG_ 451 DwnLoadDynLtgPrmForLedFrntTurnIndcrRiContTiPrm 1;
BA_ "SigGroup" SG_ 451 DwnLoadDynLtgPrmForLedFrntTurnIndcrRiContTiPrm "DwnLoadDynLtgPrmForLedFrntTurnIndcrRi";
BA_ "GenSigSendType" SG_ 451 DwnLoadDynLtgPrmForLedFrntTurnIndcrRiLowBriPrm 1;
BA_ "SigGroup" SG_ 451 DwnLoadDynLtgPrmForLedFrntTurnIndcrRiLowBriPrm "DwnLoadDynLtgPrmForLedFrntTurnIndcrRi";
BA_ "GenSigSendType" SG_ 451 DwnLoadDynLtgPrmForLedFrntTurnIndcrRiModePrm 1;
BA_ "SigGroup" SG_ 451 DwnLoadDynLtgPrmForLedFrntTurnIndcrRiModePrm "DwnLoadDynLtgPrmForLedFrntTurnIndcrRi";
BA_ "GenSigSendType" SG_ 451 DwnLoadDynLtgPrmForLedFrntTurnIndcrRiOffsTiPrm 1;
BA_ "SigGroup" SG_ 451 DwnLoadDynLtgPrmForLedFrntTurnIndcrRiOffsTiPrm "DwnLoadDynLtgPrmForLedFrntTurnIndcrRi";
BA_ "GenSigSendType" SG_ 451 DwnLoadDynLtgPrmForLedFrntTurnIndcrRiTistamp 1;
BA_ "SigGroup" SG_ 451 DwnLoadDynLtgPrmForLedFrntTurnIndcrRiTistamp "DwnLoadDynLtgPrmForLedFrntTurnIndcrRi";
BA_ "GenSigSendType" SG_ 451 DwnLoadDynLtgPrmForLedFrntTurnIndcrRiUpprBriPrm 1;
BA_ "SigGroup" SG_ 451 DwnLoadDynLtgPrmForLedFrntTurnIndcrRiUpprBriPrm "DwnLoadDynLtgPrmForLedFrntTurnIndcrRi";
// Frame: CemBodyExpoFr38
BA_ "GenMsgSendType" BO_ 455 1;
BA_ "GenMsgDelayTime" BO_ 455 70.000;
BA_ "GenSigSendType" SG_ 455 DwnLoadDynLtgPrmForLedHiBeamRiContTiPrm 1;
BA_ "GenSigSendType" SG_ 455 DwnLoadDynLtgPrmForLedHiBeamRiLowBriPrm 1;
BA_ "GenSigSendType" SG_ 455 DwnLoadDynLtgPrmForLedHiBeamRiModePrm 1;
BA_ "GenSigSendType" SG_ 455 DwnLoadDynLtgPrmForLedHiBeamRiOffsTiPrm 1;
BA_ "GenSigSendType" SG_ 455 DwnLoadDynLtgPrmForLedHiBeamRiTistamp 1;
BA_ "GenSigSendType" SG_ 455 DwnLoadDynLtgPrmForLedHiBeamRiUpprBriPrm 1;
// Frame: CemBodyExpoFr41
BA_ "GenMsgSendType" BO_ 377 0;
BA_ "GenMsgCycleTime" BO_ 377 65.000;
BA_ "GenSigSendType" SG_ 377 ADataRawSafeALat 0;
BA_ "GenSigStartValue" SG_ 377 ADataRawSafeALat1Qf 1;
BA_ "GenSigSendType" SG_ 377 ADataRawSafeALat1Qf 0;
BA_ "GenSigSendType" SG_ 377 ADataRawSafeALgt 0;
BA_ "GenSigStartValue" SG_ 377 ADataRawSafeALgt1Qf 1;
BA_ "GenSigSendType" SG_ 377 ADataRawSafeALgt1Qf 0;
BA_ "GenSigStartValue" SG_ 377 ADataRawSafeAVert 1155.059;
BA_ "GenSigSendType" SG_ 377 ADataRawSafeAVert 0;
BA_ "GenSigStartValue" SG_ 377 ADataRawSafeAVertQf 1;
BA_ "GenSigSendType" SG_ 377 ADataRawSafeAVertQf 0;
BA_ "GenSigStartValue" SG_ 377 ADataRawSafeChks 255;
BA_ "GenSigSendType" SG_ 377 ADataRawSafeChks 0;
BA_ "GenSigFuncType" SG_ 377 ADataRawSafeChks 15;
BA_ "GenSigDataID" SG_ 377 ADataRawSafeChks "0x22";
BA_ "GenSigSendType" SG_ 377 ADataRawSafeCntr 0;
BA_ "GenSigFuncType" SG_ 377 ADataRawSafeCntr 16;
// Frame: CemBodyExpoFr42
BA_ "GenMsgSendType" BO_ 381 0;
BA_ "GenMsgCycleTime" BO_ 381 65.000;
BA_ "GenSigSendType" SG_ 381 ActnOfLedPosnLampDyn 0;
BA_ "GenSigStartValue" SG_ 381 AgDataRawSafeChks 255;
BA_ "GenSigSendType" SG_ 381 AgDataRawSafeChks 0;
BA_ "GenSigFuncType" SG_ 381 AgDataRawSafeChks 15;
BA_ "GenSigDataID" SG_ 381 AgDataRawSafeChks "0x23";
BA_ "GenSigSendType" SG_ 381 AgDataRawSafeCntr 0;
BA_ "GenSigFuncType" SG_ 381 AgDataRawSafeCntr 16;
BA_ "GenSigSendType" SG_ 381 AgDataRawSafeRollRate 0;
BA_ "GenSigStartValue" SG_ 381 AgDataRawSafeRollRateQf 1;
BA_ "GenSigSendType" SG_ 381 AgDataRawSafeRollRateQf 0;
BA_ "GenSigSendType" SG_ 381 AgDataRawSafeYawRate 0;
BA_ "GenSigStartValue" SG_ 381 AgDataRawSafeYawRateQf 1;
BA_ "GenSigSendType" SG_ 381 AgDataRawSafeYawRateQf 0;
// Frame: CemBodyExpoFr45
BA_ "GenMsgSendType" BO_ 612 0;
BA_ "GenMsgCycleTime" BO_ 612 65.000;
BA_ "GenSigSendType" SG_ 612 BrkPedlValBrkPedlVal 0;
BA_ "GenSigStartValue" SG_ 612 BrkPedlValQf 1;
BA_ "GenSigSendType" SG_ 612 BrkPedlValQf 0;
BA_ "GenSigSendType" SG_ 612 LitArea 0;
BA_ "GenSigSendType" SG_ 612 WipgInfoWipgSpdInfo 0;
BA_ "GenSigSendType" SG_ 612 WipgInfoWiprActv 0;
BA_ "GenSigSendType" SG_ 612 WipgInfoWiprInWipgAr 0;
// Frame: CemBodyExpoFr48
BA_ "GenMsgSendType" BO_ 476 1;
BA_ "GenMsgDelayTime" BO_ 476 70.000;
BA_ "GenSigSendType" SG_ 476 DwnLoadDynLitPrmForLedMkrLampRi2ContTiPrm 1;
BA_ "SigGroup" SG_ 476 DwnLoadDynLitPrmForLedMkrLampRi2ContTiPrm "DwnLoadDynLitPrmForLedMkrLampRi2";
BA_ "GenSigSendType" SG_ 476 DwnLoadDynLitPrmForLedMkrLampRi2LowBriPrm 1;
BA_ "SigGroup" SG_ 476 DwnLoadDynLitPrmForLedMkrLampRi2LowBriPrm "DwnLoadDynLitPrmForLedMkrLampRi2";
BA_ "GenSigSendType" SG_ 476 DwnLoadDynLitPrmForLedMkrLampRi2ModePrm 1;
BA_ "SigGroup" SG_ 476 DwnLoadDynLitPrmForLedMkrLampRi2ModePrm "DwnLoadDynLitPrmForLedMkrLampRi2";
BA_ "GenSigSendType" SG_ 476 DwnLoadDynLitPrmForLedMkrLampRi2OffsTiPrm 1;
BA_ "SigGroup" SG_ 476 DwnLoadDynLitPrmForLedMkrLampRi2OffsTiPrm "DwnLoadDynLitPrmForLedMkrLampRi2";
BA_ "GenSigSendType" SG_ 476 DwnLoadDynLitPrmForLedMkrLampRi2Tistamp 1;
BA_ "SigGroup" SG_ 476 DwnLoadDynLitPrmForLedMkrLampRi2Tistamp "DwnLoadDynLitPrmForLedMkrLampRi2";
BA_ "GenSigSendType" SG_ 476 DwnLoadDynLitPrmForLedMkrLampRi2UpprBriPrm 1;
BA_ "SigGroup" SG_ 476 DwnLoadDynLitPrmForLedMkrLampRi2UpprBriPrm "DwnLoadDynLitPrmForLedMkrLampRi2";
// Frame: CemBodyExpoFr49
BA_ "GenMsgSendType" BO_ 473 1;
BA_ "GenMsgDelayTime" BO_ 473 70.000;
BA_ "GenSigSendType" SG_ 473 DwnLoadDynLitPrmLedRvsgLampRi2ContTiPrm 1;
BA_ "GenSigSendType" SG_ 473 DwnLoadDynLitPrmLedRvsgLampRi2LowBriPrm 1;
BA_ "GenSigSendType" SG_ 473 DwnLoadDynLitPrmLedRvsgLampRi2ModePrm 1;
BA_ "GenSigSendType" SG_ 473 DwnLoadDynLitPrmLedRvsgLampRi2OffsTiPrm 1;
BA_ "GenSigSendType" SG_ 473 DwnLoadDynLitPrmLedRvsgLampRi2Tistamp 1;
BA_ "GenSigSendType" SG_ 473 DwnLoadDynLitPrmLedRvsgLampRi2UpprBriPrm 1;
// Frame: CemBodyExpoFr50
BA_ "GenMsgSendType" BO_ 522 0;
BA_ "GenMsgCycleTime" BO_ 522 50.000;
BA_ "GenSigSendType" SG_ 522 ActnOfLedCornrgLampLe 0;
BA_ "GenSigSendType" SG_ 522 ActnOfLedCornrgLampRi 0;
BA_ "GenSigSendType" SG_ 522 ActnOfLedDaytiRunngLamp 0;
BA_ "GenSigSendType" SG_ 522 ActnOfLedFrntFogLamp 0;
BA_ "GenSigSendType" SG_ 522 ActnOfLedHiBeam 0;
BA_ "GenSigSendType" SG_ 522 ActnOfLedLoBeamActnOfLedLoBeam 0;
BA_ "GenSigSendType" SG_ 522 ActnOfLedLoBeamChks 0;
BA_ "GenSigFuncType" SG_ 522 ActnOfLedLoBeamChks 15;
BA_ "GenSigDataID" SG_ 522 ActnOfLedLoBeamChks "0x441";
BA_ "GenSigSendType" SG_ 522 ActnOfLedLoBeamCntr 0;
BA_ "GenSigFuncType" SG_ 522 ActnOfLedLoBeamCntr 16;
BA_ "GenSigSendType" SG_ 522 ActnOfLedPosnLamp 0;
BA_ "GenSigSendType" SG_ 522 ActnOfLedReFogLamp 0;
BA_ "GenSigSendType" SG_ 522 ActnOfLedRvsgLamp 0;
BA_ "GenSigSendType" SG_ 522 ActnOfLedStopLampActnOfLedStopLamp 0;
BA_ "GenSigSendType" SG_ 522 ActnOfLedStopLampChks 0;
BA_ "GenSigFuncType" SG_ 522 ActnOfLedStopLampChks 15;
BA_ "GenSigDataID" SG_ 522 ActnOfLedStopLampChks "0x443";
BA_ "GenSigSendType" SG_ 522 ActnOfLedStopLampCntr 0;
BA_ "GenSigFuncType" SG_ 522 ActnOfLedStopLampCntr 16;
BA_ "GenSigSendType" SG_ 522 ActvnOfAfs 0;
BA_ "GenSigSendType" SG_ 522 ActvnOfAhbc 0;
BA_ "GenSigSendType" SG_ 522 ActvnOfAhl 0;
BA_ "GenSigSendType" SG_ 522 ActvnOfBrkLi 0;
BA_ "GenSigSendType" SG_ 522 ActvnOfDbl 0;
BA_ "GenSigSendType" SG_ 522 ActvnOfGoodByeLi 0;
BA_ "GenSigSendType" SG_ 522 ActvnOfTouristMod 0;
BA_ "GenSigSendType" SG_ 522 ActvnOfWelcomeLi 0;
// Frame: CemBodyExpoFr51
BA_ "GenMsgSendType" BO_ 538 0;
BA_ "GenMsgCycleTime" BO_ 538 50.000;
BA_ "GenSigSendType" SG_ 538 ActvnOfIndcrIndcrOut 0;
BA_ "GenSigSendType" SG_ 538 ActvnOfIndcrIndcrOutChks 0;
BA_ "GenSigFuncType" SG_ 538 ActvnOfIndcrIndcrOutChks 15;
BA_ "GenSigDataID" SG_ 538 ActvnOfIndcrIndcrOutChks "0x9E";
BA_ "GenSigSendType" SG_ 538 ActvnOfIndcrIndcrOutCntr 0;
BA_ "GenSigFuncType" SG_ 538 ActvnOfIndcrIndcrOutCntr 16;
BA_ "GenSigStartValue" SG_ 538 EmgyBrkLiIndcrTurn 1;
BA_ "GenSigSendType" SG_ 538 EmgyBrkLiIndcrTurn 0;
BA_ "GenSigSendType" SG_ 538 IndcrPatCmd1WdTiOff 0;
BA_ "GenSigSendType" SG_ 538 IndcrPatCmd1WdTiOn 0;
BA_ "GenSigSendType" SG_ 538 IndcrSts 0;
// Frame: CemBodyExpoFr52
BA_ "GenMsgSendType" BO_ 160 0;
BA_ "GenMsgCycleTime" BO_ 160 30.000;
BA_ "GenSigSendType" SG_ 160 DwnLoadDynLitPrmForLedLogoLampContTiPrm 1;
BA_ "GenSigSendType" SG_ 160 DwnLoadDynLitPrmForLedLogoLampLowBriPrm 1;
BA_ "GenSigSendType" SG_ 160 DwnLoadDynLitPrmForLedLogoLampModePrm 1;
BA_ "GenSigSendType" SG_ 160 DwnLoadDynLitPrmForLedLogoLampOffsTiPrm 1;
BA_ "GenSigSendType" SG_ 160 DwnLoadDynLitPrmForLedLogoLampTistamp 1;
BA_ "GenSigSendType" SG_ 160 DwnLoadDynLitPrmForLedLogoLampUpprBriPrm 1;
// Frame: CemBodyExpoFr53
BA_ "GenMsgSendType" BO_ 163 0;
BA_ "GenMsgCycleTime" BO_ 163 30.000;
BA_ "GenSigSendType" SG_ 163 DwnLoadDynLitPrmLedRePosnLampLe3ContTiPrm 1;
BA_ "SigGroup" SG_ 163 DwnLoadDynLitPrmLedRePosnLampLe3ContTiPrm "DwnLoadDynLitPrmLedRePosnLampLe3";
BA_ "GenSigSendType" SG_ 163 DwnLoadDynLitPrmLedRePosnLampLe3LowBriPrm 1;
BA_ "SigGroup" SG_ 163 DwnLoadDynLitPrmLedRePosnLampLe3LowBriPrm "DwnLoadDynLitPrmLedRePosnLampLe3";
BA_ "GenSigSendType" SG_ 163 DwnLoadDynLitPrmLedRePosnLampLe3ModePrm 1;
BA_ "SigGroup" SG_ 163 DwnLoadDynLitPrmLedRePosnLampLe3ModePrm "DwnLoadDynLitPrmLedRePosnLampLe3";
BA_ "GenSigSendType" SG_ 163 DwnLoadDynLitPrmLedRePosnLampLe3OffsTiPrm 1;
BA_ "SigGroup" SG_ 163 DwnLoadDynLitPrmLedRePosnLampLe3OffsTiPrm "DwnLoadDynLitPrmLedRePosnLampLe3";
BA_ "GenSigSendType" SG_ 163 DwnLoadDynLitPrmLedRePosnLampLe3Tistamp 1;
BA_ "SigGroup" SG_ 163 DwnLoadDynLitPrmLedRePosnLampLe3Tistamp "DwnLoadDynLitPrmLedRePosnLampLe3";
BA_ "GenSigSendType" SG_ 163 DwnLoadDynLitPrmLedRePosnLampLe3UpprBriPrm 1;
BA_ "SigGroup" SG_ 163 DwnLoadDynLitPrmLedRePosnLampLe3UpprBriPrm "DwnLoadDynLitPrmLedRePosnLampLe3";
// Frame: CemBodyExpoFr54
BA_ "GenMsgSendType" BO_ 166 0;
BA_ "GenMsgCycleTime" BO_ 166 30.000;
BA_ "GenSigSendType" SG_ 166 DwnLoadDynLitPrmLedRePosnLampLe4ContTiPrm 1;
BA_ "SigGroup" SG_ 166 DwnLoadDynLitPrmLedRePosnLampLe4ContTiPrm "DwnLoadDynLitPrmLedRePosnLampLe4";
BA_ "GenSigSendType" SG_ 166 DwnLoadDynLitPrmLedRePosnLampLe4LowBriPrm 1;
BA_ "SigGroup" SG_ 166 DwnLoadDynLitPrmLedRePosnLampLe4LowBriPrm "DwnLoadDynLitPrmLedRePosnLampLe4";
BA_ "GenSigSendType" SG_ 166 DwnLoadDynLitPrmLedRePosnLampLe4ModePrm 1;
BA_ "SigGroup" SG_ 166 DwnLoadDynLitPrmLedRePosnLampLe4ModePrm "DwnLoadDynLitPrmLedRePosnLampLe4";
BA_ "GenSigSendType" SG_ 166 DwnLoadDynLitPrmLedRePosnLampLe4OffsTiPrm 1;
BA_ "SigGroup" SG_ 166 DwnLoadDynLitPrmLedRePosnLampLe4OffsTiPrm "DwnLoadDynLitPrmLedRePosnLampLe4";
BA_ "GenSigSendType" SG_ 166 DwnLoadDynLitPrmLedRePosnLampLe4Tistamp 1;
BA_ "SigGroup" SG_ 166 DwnLoadDynLitPrmLedRePosnLampLe4Tistamp "DwnLoadDynLitPrmLedRePosnLampLe4";
BA_ "GenSigSendType" SG_ 166 DwnLoadDynLitPrmLedRePosnLampLe4UpprBriPrm 1;
BA_ "SigGroup" SG_ 166 DwnLoadDynLitPrmLedRePosnLampLe4UpprBriPrm "DwnLoadDynLitPrmLedRePosnLampLe4";
// Frame: CemBodyExpoFr55
BA_ "GenMsgSendType" BO_ 169 0;
BA_ "GenMsgCycleTime" BO_ 169 30.000;
BA_ "GenSigSendType" SG_ 169 DwnLoadDynLitPrmLedRePosnLampLe5ContTiPrm 1;
BA_ "SigGroup" SG_ 169 DwnLoadDynLitPrmLedRePosnLampLe5ContTiPrm "DwnLoadDynLitPrmLedRePosnLampLe5";
BA_ "GenSigSendType" SG_ 169 DwnLoadDynLitPrmLedRePosnLampLe5LowBriPrm 1;
BA_ "SigGroup" SG_ 169 DwnLoadDynLitPrmLedRePosnLampLe5LowBriPrm "DwnLoadDynLitPrmLedRePosnLampLe5";
BA_ "GenSigSendType" SG_ 169 DwnLoadDynLitPrmLedRePosnLampLe5ModePrm 1;
BA_ "SigGroup" SG_ 169 DwnLoadDynLitPrmLedRePosnLampLe5ModePrm "DwnLoadDynLitPrmLedRePosnLampLe5";
BA_ "GenSigSendType" SG_ 169 DwnLoadDynLitPrmLedRePosnLampLe5OffsTiPrm 1;
BA_ "SigGroup" SG_ 169 DwnLoadDynLitPrmLedRePosnLampLe5OffsTiPrm "DwnLoadDynLitPrmLedRePosnLampLe5";
BA_ "GenSigSendType" SG_ 169 DwnLoadDynLitPrmLedRePosnLampLe5Tistamp 1;
BA_ "SigGroup" SG_ 169 DwnLoadDynLitPrmLedRePosnLampLe5Tistamp "DwnLoadDynLitPrmLedRePosnLampLe5";
BA_ "GenSigSendType" SG_ 169 DwnLoadDynLitPrmLedRePosnLampLe5UpprBriPrm 1;
BA_ "SigGroup" SG_ 169 DwnLoadDynLitPrmLedRePosnLampLe5UpprBriPrm "DwnLoadDynLitPrmLedRePosnLampLe5";
// Frame: CemBodyExpoFr56
BA_ "GenMsgSendType" BO_ 172 0;
BA_ "GenMsgCycleTime" BO_ 172 30.000;
BA_ "GenSigSendType" SG_ 172 DwnLoadDynLitPrmLedRePosnLampRi3ContTiPrm 1;
BA_ "SigGroup" SG_ 172 DwnLoadDynLitPrmLedRePosnLampRi3ContTiPrm "DwnLoadDynLitPrmLedRePosnLampRi3";
BA_ "GenSigSendType" SG_ 172 DwnLoadDynLitPrmLedRePosnLampRi3LowBriPrm 1;
BA_ "SigGroup" SG_ 172 DwnLoadDynLitPrmLedRePosnLampRi3LowBriPrm "DwnLoadDynLitPrmLedRePosnLampRi3";
BA_ "GenSigSendType" SG_ 172 DwnLoadDynLitPrmLedRePosnLampRi3ModePrm 1;
BA_ "SigGroup" SG_ 172 DwnLoadDynLitPrmLedRePosnLampRi3ModePrm "DwnLoadDynLitPrmLedRePosnLampRi3";
BA_ "GenSigSendType" SG_ 172 DwnLoadDynLitPrmLedRePosnLampRi3OffsTiPrm 1;
BA_ "SigGroup" SG_ 172 DwnLoadDynLitPrmLedRePosnLampRi3OffsTiPrm "DwnLoadDynLitPrmLedRePosnLampRi3";
BA_ "GenSigSendType" SG_ 172 DwnLoadDynLitPrmLedRePosnLampRi3Tistamp 1;
BA_ "SigGroup" SG_ 172 DwnLoadDynLitPrmLedRePosnLampRi3Tistamp "DwnLoadDynLitPrmLedRePosnLampRi3";
BA_ "GenSigSendType" SG_ 172 DwnLoadDynLitPrmLedRePosnLampRi3UpprBriPrm 1;
BA_ "SigGroup" SG_ 172 DwnLoadDynLitPrmLedRePosnLampRi3UpprBriPrm "DwnLoadDynLitPrmLedRePosnLampRi3";
// Frame: CemBodyExpoFr57
BA_ "GenMsgSendType" BO_ 174 0;
BA_ "GenMsgCycleTime" BO_ 174 30.000;
BA_ "GenSigSendType" SG_ 174 DwnLoadDynLitPrmLedRePosnLampRi4ContTiPrm 1;
BA_ "SigGroup" SG_ 174 DwnLoadDynLitPrmLedRePosnLampRi4ContTiPrm "DwnLoadDynLitPrmLedRePosnLampRi4";
BA_ "GenSigSendType" SG_ 174 DwnLoadDynLitPrmLedRePosnLampRi4LowBriPrm 1;
BA_ "SigGroup" SG_ 174 DwnLoadDynLitPrmLedRePosnLampRi4LowBriPrm "DwnLoadDynLitPrmLedRePosnLampRi4";
BA_ "GenSigSendType" SG_ 174 DwnLoadDynLitPrmLedRePosnLampRi4ModePrm 1;
BA_ "SigGroup" SG_ 174 DwnLoadDynLitPrmLedRePosnLampRi4ModePrm "DwnLoadDynLitPrmLedRePosnLampRi4";
BA_ "GenSigSendType" SG_ 174 DwnLoadDynLitPrmLedRePosnLampRi4OffsTiPrm 1;
BA_ "SigGroup" SG_ 174 DwnLoadDynLitPrmLedRePosnLampRi4OffsTiPrm "DwnLoadDynLitPrmLedRePosnLampRi4";
BA_ "GenSigSendType" SG_ 174 DwnLoadDynLitPrmLedRePosnLampRi4Tistamp 1;
BA_ "SigGroup" SG_ 174 DwnLoadDynLitPrmLedRePosnLampRi4Tistamp "DwnLoadDynLitPrmLedRePosnLampRi4";
BA_ "GenSigSendType" SG_ 174 DwnLoadDynLitPrmLedRePosnLampRi4UpprBriPrm 1;
BA_ "SigGroup" SG_ 174 DwnLoadDynLitPrmLedRePosnLampRi4UpprBriPrm "DwnLoadDynLitPrmLedRePosnLampRi4";
// Frame: CemBodyExpoFr58
BA_ "GenMsgSendType" BO_ 175 0;
BA_ "GenMsgCycleTime" BO_ 175 30.000;
BA_ "GenSigSendType" SG_ 175 DwnLoadDynLitPrmLedRePosnLampRi5ContTiPrm 1;
BA_ "SigGroup" SG_ 175 DwnLoadDynLitPrmLedRePosnLampRi5ContTiPrm "DwnLoadDynLitPrmLedRePosnLampRi5";
BA_ "GenSigSendType" SG_ 175 DwnLoadDynLitPrmLedRePosnLampRi5LowBriPrm 1;
BA_ "SigGroup" SG_ 175 DwnLoadDynLitPrmLedRePosnLampRi5LowBriPrm "DwnLoadDynLitPrmLedRePosnLampRi5";
BA_ "GenSigSendType" SG_ 175 DwnLoadDynLitPrmLedRePosnLampRi5ModePrm 1;
BA_ "SigGroup" SG_ 175 DwnLoadDynLitPrmLedRePosnLampRi5ModePrm "DwnLoadDynLitPrmLedRePosnLampRi5";
BA_ "GenSigSendType" SG_ 175 DwnLoadDynLitPrmLedRePosnLampRi5OffsTiPrm 1;
BA_ "SigGroup" SG_ 175 DwnLoadDynLitPrmLedRePosnLampRi5OffsTiPrm "DwnLoadDynLitPrmLedRePosnLampRi5";
BA_ "GenSigSendType" SG_ 175 DwnLoadDynLitPrmLedRePosnLampRi5Tistamp 1;
BA_ "SigGroup" SG_ 175 DwnLoadDynLitPrmLedRePosnLampRi5Tistamp "DwnLoadDynLitPrmLedRePosnLampRi5";
BA_ "GenSigSendType" SG_ 175 DwnLoadDynLitPrmLedRePosnLampRi5UpprBriPrm 1;
BA_ "SigGroup" SG_ 175 DwnLoadDynLitPrmLedRePosnLampRi5UpprBriPrm "DwnLoadDynLitPrmLedRePosnLampRi5";
// Frame: CemToAllFuncBodyCanExposedDiagReqFrame
BA_ "GenMsgSendType" BO_ 2047 1;
BA_ "GenMsgDelayTime" BO_ 2047 5.000;
// Frame: CemToHcmlBodyCanExposedDiagReqFrame
BA_ "GenMsgSendType" BO_ 1971 1;
BA_ "GenMsgDelayTime" BO_ 1971 5.000;
// Frame: CemToHcmrBodyCanExposedDiagReqFrame
BA_ "GenMsgSendType" BO_ 1972 1;
BA_ "GenMsgDelayTime" BO_ 1972 5.000;
// Frame: CemToRcmlBodyCanExposedDiagReqFrame
BA_ "GenMsgSendType" BO_ 1973 1;
BA_ "GenMsgDelayTime" BO_ 1973 5.000;
// Frame: CemToRcmmBodyCanExposedDiagReqFrame
BA_ "GenMsgSendType" BO_ 1975 1;
BA_ "GenMsgDelayTime" BO_ 1975 5.000;
// Frame: CemToRcmrBodyCanExposedDiagReqFrame
BA_ "GenMsgSendType" BO_ 1974 1;
BA_ "GenMsgDelayTime" BO_ 1974 5.000;
// Frame: EtcToCemBodyExpoDevDiagFr03
BA_ "GenMsgSendType" BO_ 1425 1;
BA_ "GenMsgDelayTime" BO_ 1425 95.000;
BA_ "GenSigSendType" SG_ 1425 CEMdevelpsignalgroupreqFunctiondevpsignalgroup1 1;
BA_ "GenSigSendType" SG_ 1425 CEMdevelpsignalgroupreqFunctiondevpsignalgroup2 1;
BA_ "GenSigSendType" SG_ 1425 CEMdevelpsignalgroupreqFunctiondevpsignalgroup3 1;
BA_ "GenSigSendType" SG_ 1425 CEMdevelpsignalgroupreqFunctiondevpsignalgroup4 1;
BA_ "GenSigSendType" SG_ 1425 CEMdevelpsignalgroupreqFunctiondevpsignalgroup5 1;
BA_ "GenSigSendType" SG_ 1425 CEMdevelpsignalgroupreqFunctiondevpsignalgroup6 1;
BA_ "GenSigSendType" SG_ 1425 CEMdevelpsignalgroupreqFunctiondevpsignalgroup7 1;
BA_ "GenSigSendType" SG_ 1425 CEMdevelpsignalgroupreqFunctiondevpsignalgroup8 1;
// Frame: EtctoHcmlXCPFr01
BA_ "GenMsgSendType" BO_ 1430 1;
BA_ "GenMsgDelayTime" BO_ 1430 10.000;
// Frame: EtctoHcmrXCPFr01
BA_ "GenMsgSendType" BO_ 1428 1;
BA_ "GenMsgDelayTime" BO_ 1428 10.000;
// Frame: HcmlBodyExpoFr02
BA_ "GenMsgSendType" BO_ 593 0;
BA_ "GenMsgCycleTime" BO_ 593 150.000;
BA_ "GenSigSendType" SG_ 593 StsOfLedHiBeamLe 0;
BA_ "GenSigSendType" SG_ 593 StsOfLedLoBeamLe 0;
// Frame: HcmlBodyExpoFr04
BA_ "GenMsgSendType" BO_ 124 0;
BA_ "GenMsgCycleTime" BO_ 124 120.000;
BA_ "GenSigSendType" SG_ 124 DwnLoadStsFbOfHdlampLe 0;
BA_ "GenSigSendType" SG_ 124 ExtrLiShowActvnFrntLeFb 0;
BA_ "GenSigSendType" SG_ 124 HdlampLeInpSts1 0;
BA_ "GenSigSendType" SG_ 124 HdlampLeInpSts2 0;
BA_ "GenSigSendType" SG_ 124 StsOfAfsLe 0;
BA_ "GenSigSendType" SG_ 124 StsOfAhbcLe 0;
BA_ "GenSigSendType" SG_ 124 StsOfFrntSideMkrLampLe2 0;
BA_ "GenSigSendType" SG_ 124 StsOfLedCornrgLampLe 0;
BA_ "GenSigSendType" SG_ 124 StsOfLedDaytiRunngLampLe 0;
BA_ "GenSigSendType" SG_ 124 StsOfLedFrntFogLampLe 0;
BA_ "GenSigSendType" SG_ 124 StsOfLedFrntPosnLampLe 0;
BA_ "GenSigSendType" SG_ 124 StsOfLedFrntTurnIndcrLe 0;
BA_ "GenSigSendType" SG_ 124 StsOfLvlgLeChks 0;
BA_ "GenSigSendType" SG_ 124 StsOfLvlgLeCntr 0;
BA_ "GenSigSendType" SG_ 124 StsOfLvlgLeStsOfLvlgLe 0;
BA_ "GenSigSendType" SG_ 124 StsOfSwvlgLe 0;
BA_ "GenSigSendType" SG_ 124 StsOfTouristModLe 0;
// Frame: HcmlBodyExposedNMFr
BA_ "GenMsgSendType" BO_ 1329 1;
BA_ "GenMsgDelayTime" BO_ 1329 20.000;
BA_ "GenMsgILSupport" BO_ 1329 0;
BA_ "NmAsrMessage" BO_ 1329 1;
// Frame: HcmlToCemBodyCanExposedDiagResFrame
BA_ "GenMsgSendType" BO_ 1715 1;
BA_ "GenMsgDelayTime" BO_ 1715 5.000;
// Frame: HcmltoEtcXCPFr01
BA_ "GenMsgSendType" BO_ 1424 1;
BA_ "GenMsgDelayTime" BO_ 1424 10.000;
// Frame: HcmrBodyExpoFr02
BA_ "GenMsgSendType" BO_ 594 0;
BA_ "GenMsgCycleTime" BO_ 594 50.000;
BA_ "GenSigSendType" SG_ 594 StsOfLedHiBeamRi 0;
BA_ "GenSigSendType" SG_ 594 StsOfLedLoBeamRi 0;
// Frame: HcmrBodyExpoFr04
BA_ "GenMsgSendType" BO_ 127 0;
BA_ "GenMsgCycleTime" BO_ 127 50.000;
BA_ "GenSigSendType" SG_ 127 DwnLoadStsFbOfHdlampRi 0;
BA_ "GenSigSendType" SG_ 127 ExtrLiShowActvnFrntRiFb 0;
BA_ "GenSigSendType" SG_ 127 HdlampRiInpSts1 0;
BA_ "GenSigSendType" SG_ 127 HdlampRiInpSts2 0;
BA_ "GenSigSendType" SG_ 127 StsOfAfsRi 0;
BA_ "GenSigSendType" SG_ 127 StsOfAhbcRi 0;
BA_ "GenSigSendType" SG_ 127 StsOfFrntSideMkrLampRi2 0;
BA_ "GenSigSendType" SG_ 127 StsOfLedCornrgLampRi 0;
BA_ "GenSigSendType" SG_ 127 StsOfLedDaytiRunngLampRi 0;
BA_ "GenSigSendType" SG_ 127 StsOfLedFrntFogLampRi 0;
BA_ "GenSigSendType" SG_ 127 StsOfLedFrntPosnLampRi 0;
BA_ "GenSigSendType" SG_ 127 StsOfLedFrntTurnIndcrRi 0;
BA_ "GenSigSendType" SG_ 127 StsOfLvlgRiChks 0;
BA_ "GenSigSendType" SG_ 127 StsOfLvlgRiCntr 0;
BA_ "GenSigSendType" SG_ 127 StsOfLvlgRiStsOfLvlgRi 0;
BA_ "GenSigSendType" SG_ 127 StsOfSwvlgRi 0;
BA_ "GenSigSendType" SG_ 127 StsOfTouristModRi 0;
// Frame: HcmrBodyExposedNMFr
BA_ "GenMsgSendType" BO_ 1330 1;
BA_ "GenMsgDelayTime" BO_ 1330 20.000;
BA_ "GenMsgILSupport" BO_ 1330 0;
BA_ "NmAsrMessage" BO_ 1330 1;
// Frame: HcmrToCemBodyCanExposedDiagResFrame
BA_ "GenMsgSendType" BO_ 1716 1;
BA_ "GenMsgDelayTime" BO_ 1716 5.000;
// Frame: HcmrtoEtcXCPFr01
BA_ "GenMsgSendType" BO_ 1426 1;
BA_ "GenMsgDelayTime" BO_ 1426 10.000;
VAL_ 99 DwnLoadDynLitPrmLedReTurnIndcrRi1ModePrm 0 "Mode1_Off" 1 "Mode1_On" 2 "Mode1_GradualOn" 3 "Mode1_GradualOff" 4 "Mode1_ForwardWipingOn" 5 "Mode1_BackwardWipingOn" 6 "Mode1_OutwardWipingOn" 7 "Mode1_InwardWipingOn" 8 "Mode1_ForwardWipingOff" 9 "Mode1_BackwardWipingOff" 10 "Mode1_OutwardWipingOff" 11 "Mode1_InwardWipingOff" 12 "Mode1_ForwardScanning" 13 "Mode1_BackwardScanning" 14 "Mode1_BreathOn" 15 "Mode1_BreathOff" 16 "Mode1_Spare1" 17 "Mode1_Spare2";
VAL_ 103 DwnLoadDynLitPrmLedRvsgLampLe1ModePrm 0 "Mode1_Off" 1 "Mode1_On" 2 "Mode1_GradualOn" 3 "Mode1_GradualOff" 4 "Mode1_ForwardWipingOn" 5 "Mode1_BackwardWipingOn" 6 "Mode1_OutwardWipingOn" 7 "Mode1_InwardWipingOn" 8 "Mode1_ForwardWipingOff" 9 "Mode1_BackwardWipingOff" 10 "Mode1_OutwardWipingOff" 11 "Mode1_InwardWipingOff" 12 "Mode1_ForwardScanning" 13 "Mode1_BackwardScanning" 14 "Mode1_BreathOn" 15 "Mode1_BreathOff" 16 "Mode1_Spare1" 17 "Mode1_Spare2";
VAL_ 107 DwnLoadDynLitPrmLedRvsgLampLe2ModePrm 0 "Mode1_Off" 1 "Mode1_On" 2 "Mode1_GradualOn" 3 "Mode1_GradualOff" 4 "Mode1_ForwardWipingOn" 5 "Mode1_BackwardWipingOn" 6 "Mode1_OutwardWipingOn" 7 "Mode1_InwardWipingOn" 8 "Mode1_ForwardWipingOff" 9 "Mode1_BackwardWipingOff" 10 "Mode1_OutwardWipingOff" 11 "Mode1_InwardWipingOff" 12 "Mode1_ForwardScanning" 13 "Mode1_BackwardScanning" 14 "Mode1_BreathOn" 15 "Mode1_BreathOff" 16 "Mode1_Spare1" 17 "Mode1_Spare2";
VAL_ 111 DwnLoadDynLitPrmLedRvsgLampRi1ModePrm 0 "Mode1_Off" 1 "Mode1_On" 2 "Mode1_GradualOn" 3 "Mode1_GradualOff" 4 "Mode1_ForwardWipingOn" 5 "Mode1_BackwardWipingOn" 6 "Mode1_OutwardWipingOn" 7 "Mode1_InwardWipingOn" 8 "Mode1_ForwardWipingOff" 9 "Mode1_BackwardWipingOff" 10 "Mode1_OutwardWipingOff" 11 "Mode1_InwardWipingOff" 12 "Mode1_ForwardScanning" 13 "Mode1_BackwardScanning" 14 "Mode1_BreathOn" 15 "Mode1_BreathOff" 16 "Mode1_Spare1" 17 "Mode1_Spare2";
VAL_ 120 LvlgSwtSetReqADModCtrlInhbn 0 "NoInhb" 1 "L12LgtCtrlModInhb" 2 "AutoParkingModInhb" 3 "L12AndAutoParkingModInhb" 4 "L3ADModInhb" 5 "L3ADAndL12LgtCtrlModInhb" 6 "L3ADAndAutoParkingModInhb" 7 "L3ADAndAutoParkingAndL12LgtCtrlModInhb";
VAL_ 120 OutdBriSts 0 "OutdBriSts_Ukwn" 1 "OutdBriSts_Night" 2 "OutdBriSts_Day" 3 "OutdBriSts_Invld";
VAL_ 407 DwnLoadDynLitPrmForLedHiBeamLeModePrm 0 "Mode1_Off" 1 "Mode1_On" 2 "Mode1_GradualOn" 3 "Mode1_GradualOff" 4 "Mode1_ForwardWipingOn" 5 "Mode1_BackwardWipingOn" 6 "Mode1_OutwardWipingOn" 7 "Mode1_InwardWipingOn" 8 "Mode1_ForwardWipingOff" 9 "Mode1_BackwardWipingOff" 10 "Mode1_OutwardWipingOff" 11 "Mode1_InwardWipingOff" 12 "Mode1_ForwardScanning" 13 "Mode1_BackwardScanning" 14 "Mode1_BreathOn" 15 "Mode1_BreathOff" 16 "Mode1_Spare1" 17 "Mode1_Spare2";
VAL_ 412 DwnLoadDynLitPrmForLedLoBeamLeModePrm 0 "Mode1_Off" 1 "Mode1_On" 2 "Mode1_GradualOn" 3 "Mode1_GradualOff" 4 "Mode1_ForwardWipingOn" 5 "Mode1_BackwardWipingOn" 6 "Mode1_OutwardWipingOn" 7 "Mode1_InwardWipingOn" 8 "Mode1_ForwardWipingOff" 9 "Mode1_BackwardWipingOff" 10 "Mode1_OutwardWipingOff" 11 "Mode1_InwardWipingOff" 12 "Mode1_ForwardScanning" 13 "Mode1_BackwardScanning" 14 "Mode1_BreathOn" 15 "Mode1_BreathOff" 16 "Mode1_Spare1" 17 "Mode1_Spare2";
VAL_ 415 DwnLoadDynLtgPrmForLedAllWthrLampLeModePrm 0 "Mode1_Off" 1 "Mode1_On" 2 "Mode1_GradualOn" 3 "Mode1_GradualOff" 4 "Mode1_ForwardWipingOn" 5 "Mode1_BackwardWipingOn" 6 "Mode1_OutwardWipingOn" 7 "Mode1_InwardWipingOn" 8 "Mode1_ForwardWipingOff" 9 "Mode1_BackwardWipingOff" 10 "Mode1_OutwardWipingOff" 11 "Mode1_InwardWipingOff" 12 "Mode1_ForwardScanning" 13 "Mode1_BackwardScanning" 14 "Mode1_BreathOn" 15 "Mode1_BreathOff" 16 "Mode1_Spare1" 17 "Mode1_Spare2";
VAL_ 419 DwnLoadDynLtgPrmForLedAllWthrLampRiModePrm 0 "Mode1_Off" 1 "Mode1_On" 2 "Mode1_GradualOn" 3 "Mode1_GradualOff" 4 "Mode1_ForwardWipingOn" 5 "Mode1_BackwardWipingOn" 6 "Mode1_OutwardWipingOn" 7 "Mode1_InwardWipingOn" 8 "Mode1_ForwardWipingOff" 9 "Mode1_BackwardWipingOff" 10 "Mode1_OutwardWipingOff" 11 "Mode1_InwardWipingOff" 12 "Mode1_ForwardScanning" 13 "Mode1_BackwardScanning" 14 "Mode1_BreathOn" 15 "Mode1_BreathOff" 16 "Mode1_Spare1" 17 "Mode1_Spare2";
VAL_ 423 DwnLoadDynLtgPrmForLedCornrgLampLeModePrm 0 "Mode1_Off" 1 "Mode1_On" 2 "Mode1_GradualOn" 3 "Mode1_GradualOff" 4 "Mode1_ForwardWipingOn" 5 "Mode1_BackwardWipingOn" 6 "Mode1_OutwardWipingOn" 7 "Mode1_InwardWipingOn" 8 "Mode1_ForwardWipingOff" 9 "Mode1_BackwardWipingOff" 10 "Mode1_OutwardWipingOff" 11 "Mode1_InwardWipingOff" 12 "Mode1_ForwardScanning" 13 "Mode1_BackwardScanning" 14 "Mode1_BreathOn" 15 "Mode1_BreathOff" 16 "Mode1_Spare1" 17 "Mode1_Spare2";
VAL_ 427 DwnLoadDynLtgPrmForLedCornrgLampRiModePrm 0 "Mode1_Off" 1 "Mode1_On" 2 "Mode1_GradualOn" 3 "Mode1_GradualOff" 4 "Mode1_ForwardWipingOn" 5 "Mode1_BackwardWipingOn" 6 "Mode1_OutwardWipingOn" 7 "Mode1_InwardWipingOn" 8 "Mode1_ForwardWipingOff" 9 "Mode1_BackwardWipingOff" 10 "Mode1_OutwardWipingOff" 11 "Mode1_InwardWipingOff" 12 "Mode1_ForwardScanning" 13 "Mode1_BackwardScanning" 14 "Mode1_BreathOn" 15 "Mode1_BreathOff" 16 "Mode1_Spare1" 17 "Mode1_Spare2";
VAL_ 430 DwnLoadDynLtgPrmForLedDaytiRunngLampLeModePrm 0 "Mode1_Off" 1 "Mode1_On" 2 "Mode1_GradualOn" 3 "Mode1_GradualOff" 4 "Mode1_ForwardWipingOn" 5 "Mode1_BackwardWipingOn" 6 "Mode1_OutwardWipingOn" 7 "Mode1_InwardWipingOn" 8 "Mode1_ForwardWipingOff" 9 "Mode1_BackwardWipingOff" 10 "Mode1_OutwardWipingOff" 11 "Mode1_InwardWipingOff" 12 "Mode1_ForwardScanning" 13 "Mode1_BackwardScanning" 14 "Mode1_BreathOn" 15 "Mode1_BreathOff" 16 "Mode1_Spare1" 17 "Mode1_Spare2";
VAL_ 436 DwnLoadDynLtgPrmForLedDaytiRunngLampRiModePrm 0 "Mode1_Off" 1 "Mode1_On" 2 "Mode1_GradualOn" 3 "Mode1_GradualOff" 4 "Mode1_ForwardWipingOn" 5 "Mode1_BackwardWipingOn" 6 "Mode1_OutwardWipingOn" 7 "Mode1_InwardWipingOn" 8 "Mode1_ForwardWipingOff" 9 "Mode1_BackwardWipingOff" 10 "Mode1_OutwardWipingOff" 11 "Mode1_InwardWipingOff" 12 "Mode1_ForwardScanning" 13 "Mode1_BackwardScanning" 14 "Mode1_BreathOn" 15 "Mode1_BreathOff" 16 "Mode1_Spare1" 17 "Mode1_Spare2";
VAL_ 440 DwnLoadDynLtgPrmForLedFrntPosnLampLeModePrm 0 "Mode1_Off" 1 "Mode1_On" 2 "Mode1_GradualOn" 3 "Mode1_GradualOff" 4 "Mode1_ForwardWipingOn" 5 "Mode1_BackwardWipingOn" 6 "Mode1_OutwardWipingOn" 7 "Mode1_InwardWipingOn" 8 "Mode1_ForwardWipingOff" 9 "Mode1_BackwardWipingOff" 10 "Mode1_OutwardWipingOff" 11 "Mode1_InwardWipingOff" 12 "Mode1_ForwardScanning" 13 "Mode1_BackwardScanning" 14 "Mode1_BreathOn" 15 "Mode1_BreathOff" 16 "Mode1_Spare1" 17 "Mode1_Spare2";
VAL_ 444 DwnLoadDynLtgPrmForLedFrntPosnLampRiModePrm 0 "Mode1_Off" 1 "Mode1_On" 2 "Mode1_GradualOn" 3 "Mode1_GradualOff" 4 "Mode1_ForwardWipingOn" 5 "Mode1_BackwardWipingOn" 6 "Mode1_OutwardWipingOn" 7 "Mode1_InwardWipingOn" 8 "Mode1_ForwardWipingOff" 9 "Mode1_BackwardWipingOff" 10 "Mode1_OutwardWipingOff" 11 "Mode1_InwardWipingOff" 12 "Mode1_ForwardScanning" 13 "Mode1_BackwardScanning" 14 "Mode1_BreathOn" 15 "Mode1_BreathOff" 16 "Mode1_Spare1" 17 "Mode1_Spare2";
VAL_ 447 DwnLoadDynLtgPrmForLedFrntTurnIndcrLeModePrm 0 "Mode1_Off" 1 "Mode1_On" 2 "Mode1_GradualOn" 3 "Mode1_GradualOff" 4 "Mode1_ForwardWipingOn" 5 "Mode1_BackwardWipingOn" 6 "Mode1_OutwardWipingOn" 7 "Mode1_InwardWipingOn" 8 "Mode1_ForwardWipingOff" 9 "Mode1_BackwardWipingOff" 10 "Mode1_OutwardWipingOff" 11 "Mode1_InwardWipingOff" 12 "Mode1_ForwardScanning" 13 "Mode1_BackwardScanning" 14 "Mode1_BreathOn" 15 "Mode1_BreathOff" 16 "Mode1_Spare1" 17 "Mode1_Spare2";
VAL_ 451 DwnLoadDynLtgPrmForLedFrntTurnIndcrRiModePrm 0 "Mode1_Off" 1 "Mode1_On" 2 "Mode1_GradualOn" 3 "Mode1_GradualOff" 4 "Mode1_ForwardWipingOn" 5 "Mode1_BackwardWipingOn" 6 "Mode1_OutwardWipingOn" 7 "Mode1_InwardWipingOn" 8 "Mode1_ForwardWipingOff" 9 "Mode1_BackwardWipingOff" 10 "Mode1_OutwardWipingOff" 11 "Mode1_InwardWipingOff" 12 "Mode1_ForwardScanning" 13 "Mode1_BackwardScanning" 14 "Mode1_BreathOn" 15 "Mode1_BreathOff" 16 "Mode1_Spare1" 17 "Mode1_Spare2";
VAL_ 455 DwnLoadDynLtgPrmForLedHiBeamRiModePrm 0 "Mode1_Off" 1 "Mode1_On" 2 "Mode1_GradualOn" 3 "Mode1_GradualOff" 4 "Mode1_ForwardWipingOn" 5 "Mode1_BackwardWipingOn" 6 "Mode1_OutwardWipingOn" 7 "Mode1_InwardWipingOn" 8 "Mode1_ForwardWipingOff" 9 "Mode1_BackwardWipingOff" 10 "Mode1_OutwardWipingOff" 11 "Mode1_InwardWipingOff" 12 "Mode1_ForwardScanning" 13 "Mode1_BackwardScanning" 14 "Mode1_BreathOn" 15 "Mode1_BreathOff" 16 "Mode1_Spare1" 17 "Mode1_Spare2";
VAL_ 377 ADataRawSafeALat1Qf 0 "Qf1_DevOfDataUndefd" 1 "Qf1_DataTmpUndefdAndEvlnInProgs" 2 "Qf1_DevOfDataNotWithinRngAllwd" 3 "Qf1_DataCalcdWithDevDefd";
VAL_ 377 ADataRawSafeALgt1Qf 0 "Qf1_DevOfDataUndefd" 1 "Qf1_DataTmpUndefdAndEvlnInProgs" 2 "Qf1_DevOfDataNotWithinRngAllwd" 3 "Qf1_DataCalcdWithDevDefd";
VAL_ 377 ADataRawSafeAVertQf 0 "Qf1_DevOfDataUndefd" 1 "Qf1_DataTmpUndefdAndEvlnInProgs" 2 "Qf1_DevOfDataNotWithinRngAllwd" 3 "Qf1_DataCalcdWithDevDefd";
VAL_ 381 ActnOfLedPosnLampDyn 0 "OnOff1_Off" 1 "OnOff1_On";
VAL_ 381 AgDataRawSafeRollRateQf 0 "Qf1_DevOfDataUndefd" 1 "Qf1_DataTmpUndefdAndEvlnInProgs" 2 "Qf1_DevOfDataNotWithinRngAllwd" 3 "Qf1_DataCalcdWithDevDefd";
VAL_ 381 AgDataRawSafeYawRateQf 0 "Qf1_DevOfDataUndefd" 1 "Qf1_DataTmpUndefdAndEvlnInProgs" 2 "Qf1_DevOfDataNotWithinRngAllwd" 3 "Qf1_DataCalcdWithDevDefd";
VAL_ 612 BrkPedlValQf 0 "GenQf1_UndefindDataAccur" 1 "GenQf1_TmpUndefdData" 2 "GenQf1_DataAccurNotWithinSpcn" 3 "GenQf1_AccurData";
VAL_ 612 LitArea 0 "NoYes1_No" 1 "NoYes1_Yes";
VAL_ 612 WipgInfoWipgSpdInfo 0 "WipgSpdInfo_Off" 1 "WipgSpdInfo_IntlLo" 2 "WipgSpdInfo_IntlHi" 3 "WipgSpdInfo_WipgSpd4045" 4 "WipgSpdInfo_WipgSpd4650" 5 "WipgSpdInfo_WipgSpd5155" 6 "WipgSpdInfo_WipgSpd5660" 7 "WipgSpdInfo_WiprErr";
VAL_ 612 WipgInfoWiprActv 0 "OnOff1_Off" 1 "OnOff1_On";
VAL_ 612 WipgInfoWiprInWipgAr 0 "OnOff1_Off" 1 "OnOff1_On";
VAL_ 476 DwnLoadDynLitPrmForLedMkrLampRi2ModePrm 0 "Mode1_Off" 1 "Mode1_On" 2 "Mode1_GradualOn" 3 "Mode1_GradualOff" 4 "Mode1_ForwardWipingOn" 5 "Mode1_BackwardWipingOn" 6 "Mode1_OutwardWipingOn" 7 "Mode1_InwardWipingOn" 8 "Mode1_ForwardWipingOff" 9 "Mode1_BackwardWipingOff" 10 "Mode1_OutwardWipingOff" 11 "Mode1_InwardWipingOff" 12 "Mode1_ForwardScanning" 13 "Mode1_BackwardScanning" 14 "Mode1_BreathOn" 15 "Mode1_BreathOff" 16 "Mode1_Spare1" 17 "Mode1_Spare2";
VAL_ 473 DwnLoadDynLitPrmLedRvsgLampRi2ModePrm 0 "Mode1_Off" 1 "Mode1_On" 2 "Mode1_GradualOn" 3 "Mode1_GradualOff" 4 "Mode1_ForwardWipingOn" 5 "Mode1_BackwardWipingOn" 6 "Mode1_OutwardWipingOn" 7 "Mode1_InwardWipingOn" 8 "Mode1_ForwardWipingOff" 9 "Mode1_BackwardWipingOff" 10 "Mode1_OutwardWipingOff" 11 "Mode1_InwardWipingOff" 12 "Mode1_ForwardScanning" 13 "Mode1_BackwardScanning" 14 "Mode1_BreathOn" 15 "Mode1_BreathOff" 16 "Mode1_Spare1" 17 "Mode1_Spare2";
VAL_ 522 ActnOfLedCornrgLampLe 0 "OnOff1_Off" 1 "OnOff1_On";
VAL_ 522 ActnOfLedCornrgLampRi 0 "OnOff1_Off" 1 "OnOff1_On";
VAL_ 522 ActnOfLedDaytiRunngLamp 0 "OnOff1_Off" 1 "OnOff1_On";
VAL_ 522 ActnOfLedFrntFogLamp 0 "OnOff1_Off" 1 "OnOff1_On";
VAL_ 522 ActnOfLedHiBeam 0 "OnOff1_Off" 1 "OnOff1_On";
VAL_ 522 ActnOfLedLoBeamActnOfLedLoBeam 0 "OnOff1_Off" 1 "OnOff1_On";
VAL_ 522 ActnOfLedPosnLamp 0 "OnOff1_Off" 1 "OnOff1_On";
VAL_ 522 ActnOfLedReFogLamp 0 "OnOff1_Off" 1 "OnOff1_On";
VAL_ 522 ActnOfLedRvsgLamp 0 "OnOff1_Off" 1 "OnOff1_On";
VAL_ 522 ActnOfLedStopLampActnOfLedStopLamp 0 "OnOff1_Off" 1 "OnOff1_On";
VAL_ 522 ActvnOfAfs 0 "OnOff1_Off" 1 "OnOff1_On";
VAL_ 522 ActvnOfAhbc 0 "OnOff1_Off" 1 "OnOff1_On";
VAL_ 522 ActvnOfAhl 0 "OnOff1_Off" 1 "OnOff1_On";
VAL_ 522 ActvnOfBrkLi 0 "OnOff1_Off" 1 "OnOff1_On";
VAL_ 522 ActvnOfDbl 0 "OnOff1_Off" 1 "OnOff1_On";
VAL_ 522 ActvnOfGoodByeLi 0 "OnOff1_Off" 1 "OnOff1_On";
VAL_ 522 ActvnOfTouristMod 0 "OnOff1_Off" 1 "OnOff1_On";
VAL_ 522 ActvnOfWelcomeLi 0 "OnOff1_Off" 1 "OnOff1_On";
VAL_ 538 ActvnOfIndcrIndcrOut 0 "IndcrSts1_Off" 1 "IndcrSts1_LeOn" 2 "IndcrSts1_RiOn" 3 "IndcrSts1_LeAndRiOn";
VAL_ 538 EmgyBrkLiIndcrTurn 0 "OnOffCrit1_NotVld1" 1 "OnOffCrit1_Off" 2 "OnOffCrit1_On" 3 "OnOffCrit1_NotVld2";
VAL_ 538 IndcrSts 0 "IndcrSts1_Off" 1 "IndcrSts1_LeOn" 2 "IndcrSts1_RiOn" 3 "IndcrSts1_LeAndRiOn";
VAL_ 160 DwnLoadDynLitPrmForLedLogoLampModePrm 0 "Mode1_Off" 1 "Mode1_On" 2 "Mode1_GradualOn" 3 "Mode1_GradualOff" 4 "Mode1_ForwardWipingOn" 5 "Mode1_BackwardWipingOn" 6 "Mode1_OutwardWipingOn" 7 "Mode1_InwardWipingOn" 8 "Mode1_ForwardWipingOff" 9 "Mode1_BackwardWipingOff" 10 "Mode1_OutwardWipingOff" 11 "Mode1_InwardWipingOff" 12 "Mode1_ForwardScanning" 13 "Mode1_BackwardScanning" 14 "Mode1_BreathOn" 15 "Mode1_BreathOff" 16 "Mode1_Spare1" 17 "Mode1_Spare2";
VAL_ 163 DwnLoadDynLitPrmLedRePosnLampLe3ModePrm 0 "Mode1_Off" 1 "Mode1_On" 2 "Mode1_GradualOn" 3 "Mode1_GradualOff" 4 "Mode1_ForwardWipingOn" 5 "Mode1_BackwardWipingOn" 6 "Mode1_OutwardWipingOn" 7 "Mode1_InwardWipingOn" 8 "Mode1_ForwardWipingOff" 9 "Mode1_BackwardWipingOff" 10 "Mode1_OutwardWipingOff" 11 "Mode1_InwardWipingOff" 12 "Mode1_ForwardScanning" 13 "Mode1_BackwardScanning" 14 "Mode1_BreathOn" 15 "Mode1_BreathOff" 16 "Mode1_Spare1" 17 "Mode1_Spare2";
VAL_ 166 DwnLoadDynLitPrmLedRePosnLampLe4ModePrm 0 "Mode1_Off" 1 "Mode1_On" 2 "Mode1_GradualOn" 3 "Mode1_GradualOff" 4 "Mode1_ForwardWipingOn" 5 "Mode1_BackwardWipingOn" 6 "Mode1_OutwardWipingOn" 7 "Mode1_InwardWipingOn" 8 "Mode1_ForwardWipingOff" 9 "Mode1_BackwardWipingOff" 10 "Mode1_OutwardWipingOff" 11 "Mode1_InwardWipingOff" 12 "Mode1_ForwardScanning" 13 "Mode1_BackwardScanning" 14 "Mode1_BreathOn" 15 "Mode1_BreathOff" 16 "Mode1_Spare1" 17 "Mode1_Spare2";
VAL_ 169 DwnLoadDynLitPrmLedRePosnLampLe5ModePrm 0 "Mode1_Off" 1 "Mode1_On" 2 "Mode1_GradualOn" 3 "Mode1_GradualOff" 4 "Mode1_ForwardWipingOn" 5 "Mode1_BackwardWipingOn" 6 "Mode1_OutwardWipingOn" 7 "Mode1_InwardWipingOn" 8 "Mode1_ForwardWipingOff" 9 "Mode1_BackwardWipingOff" 10 "Mode1_OutwardWipingOff" 11 "Mode1_InwardWipingOff" 12 "Mode1_ForwardScanning" 13 "Mode1_BackwardScanning" 14 "Mode1_BreathOn" 15 "Mode1_BreathOff" 16 "Mode1_Spare1" 17 "Mode1_Spare2";
VAL_ 172 DwnLoadDynLitPrmLedRePosnLampRi3ModePrm 0 "Mode1_Off" 1 "Mode1_On" 2 "Mode1_GradualOn" 3 "Mode1_GradualOff" 4 "Mode1_ForwardWipingOn" 5 "Mode1_BackwardWipingOn" 6 "Mode1_OutwardWipingOn" 7 "Mode1_InwardWipingOn" 8 "Mode1_ForwardWipingOff" 9 "Mode1_BackwardWipingOff" 10 "Mode1_OutwardWipingOff" 11 "Mode1_InwardWipingOff" 12 "Mode1_ForwardScanning" 13 "Mode1_BackwardScanning" 14 "Mode1_BreathOn" 15 "Mode1_BreathOff" 16 "Mode1_Spare1" 17 "Mode1_Spare2";
VAL_ 174 DwnLoadDynLitPrmLedRePosnLampRi4ModePrm 0 "Mode1_Off" 1 "Mode1_On" 2 "Mode1_GradualOn" 3 "Mode1_GradualOff" 4 "Mode1_ForwardWipingOn" 5 "Mode1_BackwardWipingOn" 6 "Mode1_OutwardWipingOn" 7 "Mode1_InwardWipingOn" 8 "Mode1_ForwardWipingOff" 9 "Mode1_BackwardWipingOff" 10 "Mode1_OutwardWipingOff" 11 "Mode1_InwardWipingOff" 12 "Mode1_ForwardScanning" 13 "Mode1_BackwardScanning" 14 "Mode1_BreathOn" 15 "Mode1_BreathOff" 16 "Mode1_Spare1" 17 "Mode1_Spare2";
VAL_ 175 DwnLoadDynLitPrmLedRePosnLampRi5ModePrm 0 "Mode1_Off" 1 "Mode1_On" 2 "Mode1_GradualOn" 3 "Mode1_GradualOff" 4 "Mode1_ForwardWipingOn" 5 "Mode1_BackwardWipingOn" 6 "Mode1_OutwardWipingOn" 7 "Mode1_InwardWipingOn" 8 "Mode1_ForwardWipingOff" 9 "Mode1_BackwardWipingOff" 10 "Mode1_OutwardWipingOff" 11 "Mode1_InwardWipingOff" 12 "Mode1_ForwardScanning" 13 "Mode1_BackwardScanning" 14 "Mode1_BreathOn" 15 "Mode1_BreathOff" 16 "Mode1_Spare1" 17 "Mode1_Spare2";
VAL_ 593 StsOfLedHiBeamLe 0 "DevSts4_Off" 1 "DevSts4_On" 2 "DevSts4_Err" 3 "DevSts4_Resd";
VAL_ 593 StsOfLedLoBeamLe 0 "DevSts4_Off" 1 "DevSts4_On" 2 "DevSts4_Err" 3 "DevSts4_Resd";
VAL_ 124 DwnLoadStsFbOfHdlampLe 0 "Sts_Resd" 1 "Sts_Err" 2 "Sts_CmplOk" 3 "Sts_InProgs";
VAL_ 124 ExtrLiShowActvnFrntLeFb 0 "Sts_Resd" 1 "Sts_Err" 2 "Sts_CmplOk" 3 "Sts_InProgs";
VAL_ 124 HdlampLeInpSts1 0 "Boolean_FALSE" 1 "Boolean_TRUE";
VAL_ 124 HdlampLeInpSts2 0 "Boolean_FALSE" 1 "Boolean_TRUE";
VAL_ 124 StsOfAfsLe 0 "DevSts4_Off" 1 "DevSts4_On" 2 "DevSts4_Err" 3 "DevSts4_Resd";
VAL_ 124 StsOfAhbcLe 0 "DevSts4_Off" 1 "DevSts4_On" 2 "DevSts4_Err" 3 "DevSts4_Resd";
VAL_ 124 StsOfFrntSideMkrLampLe2 0 "DevSts4_Off" 1 "DevSts4_On" 2 "DevSts4_Err" 3 "DevSts4_Resd";
VAL_ 124 StsOfLedCornrgLampLe 0 "DevSts4_Off" 1 "DevSts4_On" 2 "DevSts4_Err" 3 "DevSts4_Resd";
VAL_ 124 StsOfLedDaytiRunngLampLe 0 "DevSts4_Off" 1 "DevSts4_On" 2 "DevSts4_Err" 3 "DevSts4_Resd";
VAL_ 124 StsOfLedFrntFogLampLe 0 "DevSts4_Off" 1 "DevSts4_On" 2 "DevSts4_Err" 3 "DevSts4_Resd";
VAL_ 124 StsOfLedFrntPosnLampLe 0 "DevSts4_Off" 1 "DevSts4_On" 2 "DevSts4_Err" 3 "DevSts4_Resd";
VAL_ 124 StsOfLedFrntTurnIndcrLe 0 "DevSts4_Off" 1 "DevSts4_On" 2 "DevSts4_Err" 3 "DevSts4_Resd";
VAL_ 124 StsOfLvlgLeStsOfLvlgLe 0 "DevSts4_Off" 1 "DevSts4_On" 2 "DevSts4_Err" 3 "DevSts4_Resd";
VAL_ 124 StsOfSwvlgLe 0 "DevSts4_Off" 1 "DevSts4_On" 2 "DevSts4_Err" 3 "DevSts4_Resd";
VAL_ 124 StsOfTouristModLe 0 "DevSts4_Off" 1 "DevSts4_On" 2 "DevSts4_Err" 3 "DevSts4_Resd";
VAL_ 594 StsOfLedHiBeamRi 0 "DevSts4_Off" 1 "DevSts4_On" 2 "DevSts4_Err" 3 "DevSts4_Resd";
VAL_ 594 StsOfLedLoBeamRi 0 "DevSts4_Off" 1 "DevSts4_On" 2 "DevSts4_Err" 3 "DevSts4_Resd";
VAL_ 127 DwnLoadStsFbOfHdlampRi 0 "Sts_Resd" 1 "Sts_Err" 2 "Sts_CmplOk" 3 "Sts_InProgs";
VAL_ 127 ExtrLiShowActvnFrntRiFb 0 "Sts_Resd" 1 "Sts_Err" 2 "Sts_CmplOk" 3 "Sts_InProgs";
VAL_ 127 HdlampRiInpSts1 0 "Boolean_FALSE" 1 "Boolean_TRUE";
VAL_ 127 HdlampRiInpSts2 0 "Boolean_FALSE" 1 "Boolean_TRUE";
VAL_ 127 StsOfAfsRi 0 "DevSts4_Off" 1 "DevSts4_On" 2 "DevSts4_Err" 3 "DevSts4_Resd";
VAL_ 127 StsOfAhbcRi 0 "DevSts4_Off" 1 "DevSts4_On" 2 "DevSts4_Err" 3 "DevSts4_Resd";
VAL_ 127 StsOfFrntSideMkrLampRi2 0 "DevSts4_Off" 1 "DevSts4_On" 2 "DevSts4_Err" 3 "DevSts4_Resd";
VAL_ 127 StsOfLedCornrgLampRi 0 "DevSts4_Off" 1 "DevSts4_On" 2 "DevSts4_Err" 3 "DevSts4_Resd";
VAL_ 127 StsOfLedDaytiRunngLampRi 0 "DevSts4_Off" 1 "DevSts4_On" 2 "DevSts4_Err" 3 "DevSts4_Resd";
VAL_ 127 StsOfLedFrntFogLampRi 0 "DevSts4_Off" 1 "DevSts4_On" 2 "DevSts4_Err" 3 "DevSts4_Resd";
VAL_ 127 StsOfLedFrntPosnLampRi 0 "DevSts4_Off" 1 "DevSts4_On" 2 "DevSts4_Err" 3 "DevSts4_Resd";
VAL_ 127 StsOfLedFrntTurnIndcrRi 0 "DevSts4_Off" 1 "DevSts4_On" 2 "DevSts4_Err" 3 "DevSts4_Resd";
VAL_ 127 StsOfLvlgRiStsOfLvlgRi 0 "DevSts4_Off" 1 "DevSts4_On" 2 "DevSts4_Err" 3 "DevSts4_Resd";
VAL_ 127 StsOfSwvlgRi 0 "DevSts4_Off" 1 "DevSts4_On" 2 "DevSts4_Err" 3 "DevSts4_Resd";
VAL_ 127 StsOfTouristModRi 0 "DevSts4_Off" 1 "DevSts4_On" 2 "DevSts4_Err" 3 "DevSts4_Resd";
SIG_GROUP_ 522 ActnOfLedLoBeam 1 : ActnOfLedLoBeamActnOfLedLoBeam ActnOfLedLoBeamChks ActnOfLedLoBeamCntr;
SIG_GROUP_ 522 ActnOfLedStopLamp 1 : ActnOfLedStopLampActnOfLedStopLamp ActnOfLedStopLampChks ActnOfLedStopLampCntr;
SIG_GROUP_ 538 ActvnOfIndcr 1 : ActvnOfIndcrIndcrOut ActvnOfIndcrIndcrOutChks ActvnOfIndcrIndcrOutCntr;
SIG_GROUP_ 377 ADataRawSafe 1 : ADataRawSafeALat ADataRawSafeALat1Qf ADataRawSafeALgt ADataRawSafeALgt1Qf ADataRawSafeAVert ADataRawSafeAVertQf ADataRawSafeChks ADataRawSafeCntr;
SIG_GROUP_ 381 AgDataRawSafe 1 : AgDataRawSafeChks AgDataRawSafeCntr AgDataRawSafeRollRate AgDataRawSafeRollRateQf AgDataRawSafeYawRate AgDataRawSafeYawRateQf;
SIG_GROUP_ 612 BrkPedlVal 1 : BrkPedlValBrkPedlVal BrkPedlValQf;
SIG_GROUP_ 1425 CEMdevelpsignalgroupreq 1 : CEMdevelpsignalgroupreqFunctiondevpsignalgroup1 CEMdevelpsignalgroupreqFunctiondevpsignalgroup2 CEMdevelpsignalgroupreqFunctiondevpsignalgroup3 CEMdevelpsignalgroupreqFunctiondevpsignalgroup4 CEMdevelpsignalgroupreqFunctiondevpsignalgroup5 CEMdevelpsignalgroupreqFunctiondevpsignalgroup6 CEMdevelpsignalgroupreqFunctiondevpsignalgroup7 CEMdevelpsignalgroupreqFunctiondevpsignalgroup8;
SIG_GROUP_ 407 DwnLoadDynLitPrmForLedHiBeamLe 1 : DwnLoadDynLitPrmForLedHiBeamLeContTiPrm DwnLoadDynLitPrmForLedHiBeamLeLowBriPrm DwnLoadDynLitPrmForLedHiBeamLeModePrm DwnLoadDynLitPrmForLedHiBeamLeOffsTiPrm DwnLoadDynLitPrmForLedHiBeamLeTistamp DwnLoadDynLitPrmForLedHiBeamLeUpprBriPrm;
SIG_GROUP_ 412 DwnLoadDynLitPrmForLedLoBeamLe 1 : DwnLoadDynLitPrmForLedLoBeamLeContTiPrm DwnLoadDynLitPrmForLedLoBeamLeLowBriPrm DwnLoadDynLitPrmForLedLoBeamLeModePrm DwnLoadDynLitPrmForLedLoBeamLeOffsTiPrm DwnLoadDynLitPrmForLedLoBeamLeTistamp DwnLoadDynLitPrmForLedLoBeamLeUpprBriPrm;
SIG_GROUP_ 160 DwnLoadDynLitPrmForLedLogoLamp 1 : DwnLoadDynLitPrmForLedLogoLampContTiPrm DwnLoadDynLitPrmForLedLogoLampLowBriPrm DwnLoadDynLitPrmForLedLogoLampModePrm DwnLoadDynLitPrmForLedLogoLampOffsTiPrm DwnLoadDynLitPrmForLedLogoLampTistamp DwnLoadDynLitPrmForLedLogoLampUpprBriPrm;
SIG_GROUP_ 476 DwnLoadDynLitPrmForLedMkrLampRi2 1 : DwnLoadDynLitPrmForLedMkrLampRi2ContTiPrm DwnLoadDynLitPrmForLedMkrLampRi2LowBriPrm DwnLoadDynLitPrmForLedMkrLampRi2ModePrm DwnLoadDynLitPrmForLedMkrLampRi2OffsTiPrm DwnLoadDynLitPrmForLedMkrLampRi2Tistamp DwnLoadDynLitPrmForLedMkrLampRi2UpprBriPrm;
SIG_GROUP_ 163 DwnLoadDynLitPrmLedRePosnLampLe3 1 : DwnLoadDynLitPrmLedRePosnLampLe3ContTiPrm DwnLoadDynLitPrmLedRePosnLampLe3LowBriPrm DwnLoadDynLitPrmLedRePosnLampLe3ModePrm DwnLoadDynLitPrmLedRePosnLampLe3OffsTiPrm DwnLoadDynLitPrmLedRePosnLampLe3Tistamp DwnLoadDynLitPrmLedRePosnLampLe3UpprBriPrm;
SIG_GROUP_ 166 DwnLoadDynLitPrmLedRePosnLampLe4 1 : DwnLoadDynLitPrmLedRePosnLampLe4ContTiPrm DwnLoadDynLitPrmLedRePosnLampLe4LowBriPrm DwnLoadDynLitPrmLedRePosnLampLe4ModePrm DwnLoadDynLitPrmLedRePosnLampLe4OffsTiPrm DwnLoadDynLitPrmLedRePosnLampLe4Tistamp DwnLoadDynLitPrmLedRePosnLampLe4UpprBriPrm;
SIG_GROUP_ 169 DwnLoadDynLitPrmLedRePosnLampLe5 1 : DwnLoadDynLitPrmLedRePosnLampLe5ContTiPrm DwnLoadDynLitPrmLedRePosnLampLe5LowBriPrm DwnLoadDynLitPrmLedRePosnLampLe5ModePrm DwnLoadDynLitPrmLedRePosnLampLe5OffsTiPrm DwnLoadDynLitPrmLedRePosnLampLe5Tistamp DwnLoadDynLitPrmLedRePosnLampLe5UpprBriPrm;
SIG_GROUP_ 172 DwnLoadDynLitPrmLedRePosnLampRi3 1 : DwnLoadDynLitPrmLedRePosnLampRi3ContTiPrm DwnLoadDynLitPrmLedRePosnLampRi3LowBriPrm DwnLoadDynLitPrmLedRePosnLampRi3ModePrm DwnLoadDynLitPrmLedRePosnLampRi3OffsTiPrm DwnLoadDynLitPrmLedRePosnLampRi3Tistamp DwnLoadDynLitPrmLedRePosnLampRi3UpprBriPrm;
SIG_GROUP_ 174 DwnLoadDynLitPrmLedRePosnLampRi4 1 : DwnLoadDynLitPrmLedRePosnLampRi4ContTiPrm DwnLoadDynLitPrmLedRePosnLampRi4LowBriPrm DwnLoadDynLitPrmLedRePosnLampRi4ModePrm DwnLoadDynLitPrmLedRePosnLampRi4OffsTiPrm DwnLoadDynLitPrmLedRePosnLampRi4Tistamp DwnLoadDynLitPrmLedRePosnLampRi4UpprBriPrm;
SIG_GROUP_ 175 DwnLoadDynLitPrmLedRePosnLampRi5 1 : DwnLoadDynLitPrmLedRePosnLampRi5ContTiPrm DwnLoadDynLitPrmLedRePosnLampRi5LowBriPrm DwnLoadDynLitPrmLedRePosnLampRi5ModePrm DwnLoadDynLitPrmLedRePosnLampRi5OffsTiPrm DwnLoadDynLitPrmLedRePosnLampRi5Tistamp DwnLoadDynLitPrmLedRePosnLampRi5UpprBriPrm;
SIG_GROUP_ 99 DwnLoadDynLitPrmLedReTurnIndcrRi1 1 : DwnLoadDynLitPrmLedReTurnIndcrRi1ContTiPrm DwnLoadDynLitPrmLedReTurnIndcrRi1LowBriPrm DwnLoadDynLitPrmLedReTurnIndcrRi1ModePrm DwnLoadDynLitPrmLedReTurnIndcrRi1OffsTiPrm DwnLoadDynLitPrmLedReTurnIndcrRi1Tistamp DwnLoadDynLitPrmLedReTurnIndcrRi1UpprBriPrm;
SIG_GROUP_ 103 DwnLoadDynLitPrmLedRvsgLampLe1 1 : DwnLoadDynLitPrmLedRvsgLampLe1ContTiPrm DwnLoadDynLitPrmLedRvsgLampLe1LowBriPrm DwnLoadDynLitPrmLedRvsgLampLe1ModePrm DwnLoadDynLitPrmLedRvsgLampLe1OffsTiPrm DwnLoadDynLitPrmLedRvsgLampLe1Tistamp DwnLoadDynLitPrmLedRvsgLampLe1UpprBriPrm;
SIG_GROUP_ 107 DwnLoadDynLitPrmLedRvsgLampLe2 1 : DwnLoadDynLitPrmLedRvsgLampLe2ContTiPrm DwnLoadDynLitPrmLedRvsgLampLe2LowBriPrm DwnLoadDynLitPrmLedRvsgLampLe2ModePrm DwnLoadDynLitPrmLedRvsgLampLe2OffsTiPrm DwnLoadDynLitPrmLedRvsgLampLe2Tistamp DwnLoadDynLitPrmLedRvsgLampLe2UpprBriPrm;
SIG_GROUP_ 111 DwnLoadDynLitPrmLedRvsgLampRi1 1 : DwnLoadDynLitPrmLedRvsgLampRi1ContTiPrm DwnLoadDynLitPrmLedRvsgLampRi1LowBriPrm DwnLoadDynLitPrmLedRvsgLampRi1ModePrm DwnLoadDynLitPrmLedRvsgLampRi1OffsTiPrm DwnLoadDynLitPrmLedRvsgLampRi1Tistamp DwnLoadDynLitPrmLedRvsgLampRi1UpprBriPrm;
SIG_GROUP_ 473 DwnLoadDynLitPrmLedRvsgLampRi2 1 : DwnLoadDynLitPrmLedRvsgLampRi2ContTiPrm DwnLoadDynLitPrmLedRvsgLampRi2LowBriPrm DwnLoadDynLitPrmLedRvsgLampRi2ModePrm DwnLoadDynLitPrmLedRvsgLampRi2OffsTiPrm DwnLoadDynLitPrmLedRvsgLampRi2Tistamp DwnLoadDynLitPrmLedRvsgLampRi2UpprBriPrm;
SIG_GROUP_ 415 DwnLoadDynLtgPrmForLedAllWthrLampLe 1 : DwnLoadDynLtgPrmForLedAllWthrLampLeContTiPrm DwnLoadDynLtgPrmForLedAllWthrLampLeLowBriPrm DwnLoadDynLtgPrmForLedAllWthrLampLeModePrm DwnLoadDynLtgPrmForLedAllWthrLampLeOffsTiPrm DwnLoadDynLtgPrmForLedAllWthrLampLeTistamp DwnLoadDynLtgPrmForLedAllWthrLampLeUpprBriPrm;
SIG_GROUP_ 419 DwnLoadDynLtgPrmForLedAllWthrLampRi 1 : DwnLoadDynLtgPrmForLedAllWthrLampRiContTiPrm DwnLoadDynLtgPrmForLedAllWthrLampRiLowBriPrm DwnLoadDynLtgPrmForLedAllWthrLampRiModePrm DwnLoadDynLtgPrmForLedAllWthrLampRiOffsTiPrm DwnLoadDynLtgPrmForLedAllWthrLampRiTistamp DwnLoadDynLtgPrmForLedAllWthrLampRiUpprBriPrm;
SIG_GROUP_ 423 DwnLoadDynLtgPrmForLedCornrgLampLe 1 : DwnLoadDynLtgPrmForLedCornrgLampLeContTiPrm DwnLoadDynLtgPrmForLedCornrgLampLeLowBriPrm DwnLoadDynLtgPrmForLedCornrgLampLeModePrm DwnLoadDynLtgPrmForLedCornrgLampLeOffsTiPrm DwnLoadDynLtgPrmForLedCornrgLampLeTistamp DwnLoadDynLtgPrmForLedCornrgLampLeUpprBriPrm;
SIG_GROUP_ 427 DwnLoadDynLtgPrmForLedCornrgLampRi 1 : DwnLoadDynLtgPrmForLedCornrgLampRiContTiPrm DwnLoadDynLtgPrmForLedCornrgLampRiLowBriPrm DwnLoadDynLtgPrmForLedCornrgLampRiModePrm DwnLoadDynLtgPrmForLedCornrgLampRiOffsTiPrm DwnLoadDynLtgPrmForLedCornrgLampRiTistamp DwnLoadDynLtgPrmForLedCornrgLampRiUpprBriPrm;
SIG_GROUP_ 430 DwnLoadDynLtgPrmForLedDaytiRunngLampLe 1 : DwnLoadDynLtgPrmForLedDaytiRunngLampLeContTiPrm DwnLoadDynLtgPrmForLedDaytiRunngLampLeLowBriPrm DwnLoadDynLtgPrmForLedDaytiRunngLampLeModePrm DwnLoadDynLtgPrmForLedDaytiRunngLampLeOffsTiPrm DwnLoadDynLtgPrmForLedDaytiRunngLampLeTistamp DwnLoadDynLtgPrmForLedDaytiRunngLampLeUpprBriPrm;
SIG_GROUP_ 436 DwnLoadDynLtgPrmForLedDaytiRunngLampRi 1 : DwnLoadDynLtgPrmForLedDaytiRunngLampRiContTiPrm DwnLoadDynLtgPrmForLedDaytiRunngLampRiLowBriPrm DwnLoadDynLtgPrmForLedDaytiRunngLampRiModePrm DwnLoadDynLtgPrmForLedDaytiRunngLampRiOffsTiPrm DwnLoadDynLtgPrmForLedDaytiRunngLampRiTistamp DwnLoadDynLtgPrmForLedDaytiRunngLampRiUpprBriPrm;
SIG_GROUP_ 440 DwnLoadDynLtgPrmForLedFrntPosnLampLe 1 : DwnLoadDynLtgPrmForLedFrntPosnLampLeContTiPrm DwnLoadDynLtgPrmForLedFrntPosnLampLeLowBriPrm DwnLoadDynLtgPrmForLedFrntPosnLampLeModePrm DwnLoadDynLtgPrmForLedFrntPosnLampLeOffsTiPrm DwnLoadDynLtgPrmForLedFrntPosnLampLeTistamp DwnLoadDynLtgPrmForLedFrntPosnLampLeUpprBriPrm;
SIG_GROUP_ 444 DwnLoadDynLtgPrmForLedFrntPosnLampRi 1 : DwnLoadDynLtgPrmForLedFrntPosnLampRiContTiPrm DwnLoadDynLtgPrmForLedFrntPosnLampRiLowBriPrm DwnLoadDynLtgPrmForLedFrntPosnLampRiModePrm DwnLoadDynLtgPrmForLedFrntPosnLampRiOffsTiPrm DwnLoadDynLtgPrmForLedFrntPosnLampRiTistamp DwnLoadDynLtgPrmForLedFrntPosnLampRiUpprBriPrm;
SIG_GROUP_ 447 DwnLoadDynLtgPrmForLedFrntTurnIndcrLe 1 : DwnLoadDynLtgPrmForLedFrntTurnIndcrLeContTiPrm DwnLoadDynLtgPrmForLedFrntTurnIndcrLeLowBriPrm DwnLoadDynLtgPrmForLedFrntTurnIndcrLeModePrm DwnLoadDynLtgPrmForLedFrntTurnIndcrLeOffsTiPrm DwnLoadDynLtgPrmForLedFrntTurnIndcrLeTistamp DwnLoadDynLtgPrmForLedFrntTurnIndcrLeUpprBriPrm;
SIG_GROUP_ 451 DwnLoadDynLtgPrmForLedFrntTurnIndcrRi 1 : DwnLoadDynLtgPrmForLedFrntTurnIndcrRiContTiPrm DwnLoadDynLtgPrmForLedFrntTurnIndcrRiLowBriPrm DwnLoadDynLtgPrmForLedFrntTurnIndcrRiModePrm DwnLoadDynLtgPrmForLedFrntTurnIndcrRiOffsTiPrm DwnLoadDynLtgPrmForLedFrntTurnIndcrRiTistamp DwnLoadDynLtgPrmForLedFrntTurnIndcrRiUpprBriPrm;
SIG_GROUP_ 455 DwnLoadDynLtgPrmForLedHiBeamRi 1 : DwnLoadDynLtgPrmForLedHiBeamRiContTiPrm DwnLoadDynLtgPrmForLedHiBeamRiLowBriPrm DwnLoadDynLtgPrmForLedHiBeamRiModePrm DwnLoadDynLtgPrmForLedHiBeamRiOffsTiPrm DwnLoadDynLtgPrmForLedHiBeamRiTistamp DwnLoadDynLtgPrmForLedHiBeamRiUpprBriPrm;
SIG_GROUP_ 538 IndcrPat 1 : IndcrPatCmd1WdTiOff IndcrPatCmd1WdTiOn;
SIG_GROUP_ 120 LvlgSwtSetReq 1 : LvlgSwtSetReqADModCtrlInhbn LvlgSwtSetReqChks LvlgSwtSetReqCntr;
SIG_GROUP_ 120 OutdBri 1 : OutdBriChks OutdBriCntr OutdBriSts;
SIG_GROUP_ 124 StsOfLvlgLe 1 : StsOfLvlgLeChks StsOfLvlgLeCntr StsOfLvlgLeStsOfLvlgLe;
SIG_GROUP_ 127 StsOfLvlgRi 1 : StsOfLvlgRiChks StsOfLvlgRiCntr StsOfLvlgRiStsOfLvlgRi;
SIG_GROUP_ 612 WipgInfo 1 : WipgInfoWipgSpdInfo WipgInfoWiprActv WipgInfoWiprInWipgAr;
